VERSION ""

NS_ :

BS_:

BU_: Airbag Allrad EPS Teves_MK60_ESP LWS LWR Teves_MK70_MABS Waehlhebel EPB TRW_ESP ACC_Radar AFS Magne_Ride RKA_Plus Selespeed Waehlhebel_Sele PDC_PLA Lenkhilfe_APA VAQ Daempfer Hybrid_BMS Hybrid_PWR Hybrid_DQ200 EKlimakomp SWA HCA ACC_Lidar Lenkhilfe_ZF_3G FLA AG6 DQ Hybrid_MSG Diesel Otto Gateway_PQ35_A Gateway_PQ46_A Vector_XXX Fzg_CAN

BO_ 1104 mGetriebe_8: 8 Selespeed
 SG_ GE8_Checksumme : 0|8@1+ (1,0) [0|255] ""  Otto
 SG_ GE8_Hydr_Pumpe : 12|1@1+ (1,0) [0|1] ""  Otto
 SG_ GE8_Motor_aus : 13|1@1+ (1,0) [0|1] ""  Otto
 SG_ GE8_Anfahrfkt : 14|1@1+ (1,0) [0|1] ""  Otto
 SG_ GE8_SollDZ : 16|10@1+ (10,0) [0|10230] "upm"  Otto
 SG_ GE8_VorsteuerMom : 26|10@1+ (1,0) [0|1023] "Nm"  Otto
 SG_ GE8_KuppMom : 36|10@1+ (1,0) [0|1023] "Nm"  Otto
 SG_ GE8_Zaehler : 8|4@1+ (1,0) [0|15] ""  Otto
 SG_ GE8_res_15 : 15|1@1+ (1,0) [0|1] "" Vector__XXX
 SG_ GE8_res_46 : 46|1@1+ (1,0) [0|1] "" Vector__XXX
 SG_ GE8_res_47 : 47|1@1+ (1,0) [0|1] "" Vector__XXX
 SG_ GE8_res_48 : 48|1@1+ (1,0) [0|1] "" Vector__XXX
 SG_ GE8_res_49 : 49|1@1+ (1,0) [0|1] "" Vector__XXX
 SG_ GE8_res_50 : 50|1@1+ (1,0) [0|1] "" Vector__XXX
 SG_ GE8_res_52 : 52|1@1+ (1,0) [0|1] "" Vector__XXX
 SG_ GE8_res_53 : 53|1@1+ (1,0) [0|1] "" Vector__XXX
 SG_ GE8_res_54 : 54|1@1+ (1,0) [0|1] "" Vector__XXX
 SG_ GE8_res_55 : 55|1@1+ (1,0) [0|1] "" Vector__XXX
 SG_ GE8_res_56 : 56|1@1+ (1,0) [0|1] "" Vector__XXX
 SG_ GE8_res_57 : 57|1@1+ (1,0) [0|1] "" Vector__XXX
 SG_ GE8_res_51 : 51|1@1+ (1,0) [0|1] "" Vector__XXX
 SG_ GE8_res_58 : 58|1@1+ (1,0) [0|1] "" Vector__XXX
 SG_ GE8_res_59 : 59|1@1+ (1,0) [0|1] "" Vector__XXX
 SG_ GE8_res_60 : 60|1@1+ (1,0) [0|1] "" Vector__XXX
 SG_ GE8_res_61 : 61|1@1+ (1,0) [0|1] "" Vector__XXX
 SG_ GE8_res_63 : 63|1@1+ (1,0) [0|1] "" Vector__XXX
 SG_ GE8_res_62 : 62|1@1+ (1,0) [0|1] "" Vector__XXX

BO_ 1102 mWaehlhebel_2: 5 Waehlhebel_Sele
 SG_ WH2_Fehler0 : 24|1@1+ (1,0) [0|1] ""  Selespeed
 SG_ WH2_Testergebnis : 32|8@1+ (1,0) [0|255] ""  Selespeed
 SG_ WH2_Zaehler : 8|4@1+ (1,0) [0|15] ""  Selespeed
 SG_ WH2_Init : 12|1@1+ (1,0) [0|1] ""  Selespeed
 SG_ WH2_Checksumme : 0|8@1+ (1,0) [0|255] ""  Selespeed
 SG_ WH2_Winter : 15|1@1+ (1,0) [0|1] ""  Selespeed
 SG_ WH2_Sport : 14|1@1+ (1,0) [0|1] ""  Selespeed
 SG_ WH2_Reserve1 : 19|4@1+ (1,0) [0|15] ""  Selespeed
 SG_ WH2_Test_Flag : 13|1@1+ (1,0) [0|1] ""  Selespeed
 SG_ WH2_Position : 16|3@1+ (1,0) [0|7] ""  Selespeed
 SG_ WH2_Ruhestromfehler : 23|1@1+ (1,0) [0|1] ""  Selespeed
 SG_ WH2_Fehler2 : 26|1@1+ (1,0) [0|1] ""  Selespeed
 SG_ WH2_Fehler1 : 25|1@1+ (1,0) [0|1] ""  Selespeed
 SG_ WH2_Fehler4 : 28|1@1+ (1,0) [0|1] ""  Selespeed
 SG_ WH2_Fehler5 : 29|1@1+ (1,0) [0|1] ""  Selespeed
 SG_ WH2_Fehler3 : 27|1@1+ (1,0) [0|1] ""  Selespeed
 SG_ WH2_Fehler7 : 31|1@1+ (1,0) [0|1] ""  Selespeed
 SG_ WH2_Fehler6 : 30|1@1+ (1,0) [0|1] ""  Selespeed

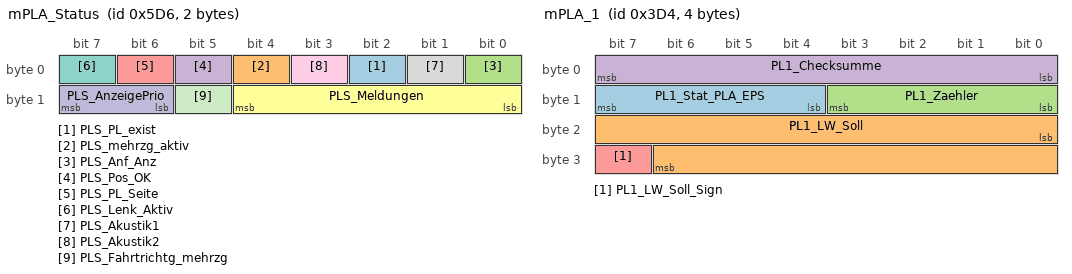
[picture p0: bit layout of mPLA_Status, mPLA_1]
BO_ 1494 mPLA_Status: 2 PDC_PLA
 SG_ PLS_PL_exist : 2|1@1+ (1,0) [0|1] ""  Gateway_PQ46_A,Gateway_PQ35_A
 SG_ PLS_mehrzg_aktiv : 4|1@1+ (1,0) [0|1] ""  Gateway_PQ46_A,Gateway_PQ35_A
 SG_ PLS_Anf_Anz : 0|1@1+ (1,0) [0|1] ""  Gateway_PQ46_A,Gateway_PQ35_A
 SG_ PLS_Pos_OK : 5|1@1+ (1,0) [0|1] ""  Gateway_PQ46_A,Gateway_PQ35_A
 SG_ PLS_PL_Seite : 6|1@1+ (1,0) [0|1] ""  Gateway_PQ46_A,Gateway_PQ35_A
 SG_ PLS_Meldungen : 8|5@1+ (1,0) [0|31] ""  Gateway_PQ46_A,Gateway_PQ35_A
 SG_ PLS_Lenk_Aktiv : 7|1@1+ (1,0) [0|1] ""  Gateway_PQ46_A,Gateway_PQ35_A
 SG_ PLS_Akustik1 : 1|1@1+ (1,0) [0|1] ""  Gateway_PQ46_A,Gateway_PQ35_A
 SG_ PLS_Akustik2 : 3|1@1+ (1,0) [0|1] ""  Gateway_PQ46_A,Gateway_PQ35_A
 SG_ PLS_AnzeigePrio : 14|2@1+ (1,0) [0|3] ""  Gateway_PQ46_A,Gateway_PQ35_A
 SG_ PLS_Fahrtrichtg_mehrzg : 13|1@1+ (1,0) [0|1] ""  Gateway_PQ46_A,Gateway_PQ35_A

BO_ 980 mPLA_1: 4 PDC_PLA
 SG_ PL1_Stat_PLA_EPS : 12|4@1+ (1,0) [0|15] ""  EPS,Lenkhilfe_APA,Lenkhilfe_ZF_3G
 SG_ PL1_LW_Soll : 16|15@1+ (0.04375,0) [0|1433.55625] "°"  EPS,Lenkhilfe_APA,Lenkhilfe_ZF_3G
 SG_ PL1_Zaehler : 8|4@1+ (1,0) [0|15] ""  EPS,Lenkhilfe_APA,Lenkhilfe_ZF_3G
 SG_ PL1_Checksumme : 0|8@1+ (1,0) [0|255] ""  EPS,Lenkhilfe_APA,Lenkhilfe_ZF_3G
 SG_ PL1_LW_Soll_Sign : 31|1@1+ (1,0) [0|1] ""  EPS,Lenkhilfe_APA,Lenkhilfe_ZF_3G

BO_ 541 mTP_Er_PLA_PDC: 7 PDC_PLA
 SG_ PLA_PDC_TP_Er : 0|56@1+ (1,0) [0|7.2057594038E+016] ""  Gateway_PQ46_A,Gateway_PQ35_A

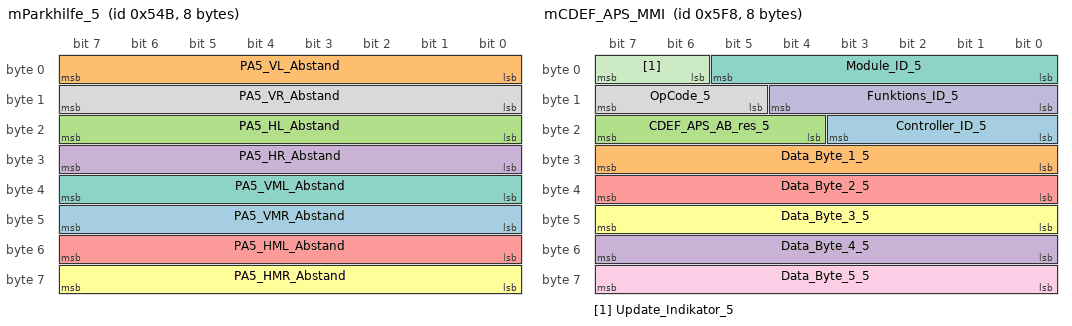
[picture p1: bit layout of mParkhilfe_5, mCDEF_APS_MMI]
BO_ 1355 mParkhilfe_5: 8 PDC_PLA
 SG_ PA5_VMR_Abstand : 40|8@1+ (1,0) [0|254] "cm"  Gateway_PQ46_A,Gateway_PQ35_A
 SG_ PA5_VL_Abstand : 0|8@1+ (1,0) [0|254] "cm"  Gateway_PQ46_A,Gateway_PQ35_A
 SG_ PA5_HL_Abstand : 16|8@1+ (1,0) [0|254] "cm"  Gateway_PQ46_A,Gateway_PQ35_A
 SG_ PA5_HR_Abstand : 24|8@1+ (1,0) [0|254] "cm"  Gateway_PQ46_A,Gateway_PQ35_A
 SG_ PA5_HML_Abstand : 48|8@1+ (1,0) [0|254] "cm"  Gateway_PQ46_A,Gateway_PQ35_A
 SG_ PA5_HMR_Abstand : 56|8@1+ (1,0) [0|254] "cm"  Gateway_PQ46_A,Gateway_PQ35_A
 SG_ PA5_VML_Abstand : 32|8@1+ (1,0) [0|254] "cm"  Gateway_PQ46_A,Gateway_PQ35_A
 SG_ PA5_VR_Abstand : 8|8@1+ (1,0) [0|254] "cm"  Gateway_PQ46_A,Gateway_PQ35_A

BO_ 1175 Parkhilfe_01: 8 PDC_PLA
 SG_ PH_Opt_Anzeige_V_ein : 16|1@1+ (1,0) [0|1] ""  Gateway_PQ46_A,Gateway_PQ35_A
 SG_ PH_Opt_Anzeige_H_ein : 17|1@1+ (1,0) [0|1] ""  Gateway_PQ46_A,Gateway_PQ35_A
 SG_ PH_Opt_Anz_V_Hindernis : 18|1@1+ (1,0) [0|1] ""  Gateway_PQ46_A,Gateway_PQ35_A
 SG_ PH_Abschaltursache : 13|3@1+ (1,0) [0|7] ""  Gateway_PQ46_A,Gateway_PQ35_A
 SG_ PH_Opt_Anz_H_Hindernis : 19|1@1+ (1,0) [0|1] ""  Gateway_PQ46_A,Gateway_PQ35_A
 SG_ PH_Tongeber_V_aktiv : 20|1@1+ (1,0) [0|1] ""  Gateway_PQ46_A,Gateway_PQ35_A
 SG_ PH_Tongeber_mute : 22|1@1+ (1,0) [0|1] ""  Gateway_PQ46_A,Gateway_PQ35_A
 SG_ PH_Frequenz_hinten : 32|4@1+ (1,0) [0|15] ""  Gateway_PQ46_A,Gateway_PQ35_A
 SG_ PH_Lautstaerke_hinten : 36|4@1+ (1,0) [0|15] ""  Gateway_PQ46_A,Gateway_PQ35_A
 SG_ PH_Tongeber_H_aktiv : 21|1@1+ (1,0) [0|1] ""  Gateway_PQ46_A,Gateway_PQ35_A
 SG_ PH_Frequenz_vorn : 40|4@1+ (1,0) [0|15] ""  Gateway_PQ46_A,Gateway_PQ35_A
 SG_ PH_Lautstaerke_vorn : 44|4@1+ (1,0) [0|15] ""  Gateway_PQ46_A,Gateway_PQ35_A
 SG_ PH_defekt : 56|1@1+ (1,0) [0|1] ""  Gateway_PQ46_A,Gateway_PQ35_A
 SG_ PH_Anf_Audioabsenkung : 23|1@1+ (1,0) [0|1] ""  Gateway_PQ46_A,Gateway_PQ35_A
 SG_ PH_Systemzustand : 58|3@1+ (1,0) [0|7] ""  Gateway_PQ46_A,Gateway_PQ35_A
 SG_ PH_Display_Kundenwunsch : 61|2@1+ (1,0) [0|3] ""  Gateway_PQ46_A,Gateway_PQ35_A
 SG_ PH_KD_Fehler : 63|1@1+ (1,0) [0|1] ""  Gateway_PQ46_A,Gateway_PQ35_A
 SG_ PH_gestoert : 57|1@1+ (1,0) [0|1] ""  Gateway_PQ46_A,Gateway_PQ35_A
 SG_ PH_res_02 : 2|1@1+ (1,0) [0|1] ""  Gateway_PQ46_A,Gateway_PQ35_A
 SG_ PH_res_04 : 4|1@1+ (1,0) [0|1] ""  Gateway_PQ46_A,Gateway_PQ35_A
 SG_ PH_res_01 : 1|1@1+ (1,0) [0|1] ""  Gateway_PQ46_A,Gateway_PQ35_A
 SG_ PH_res_00 : 0|1@1+ (1,0) [0|1] ""  Gateway_PQ46_A,Gateway_PQ35_A
 SG_ PH_res_05 : 5|1@1+ (1,0) [0|1] ""  Gateway_PQ46_A,Gateway_PQ35_A
 SG_ PH_res_03 : 3|1@1+ (1,0) [0|1] ""  Gateway_PQ46_A,Gateway_PQ35_A
 SG_ PH_res_06 : 6|1@1+ (1,0) [0|1] ""  Gateway_PQ46_A,Gateway_PQ35_A
 SG_ PH_res_07 : 7|1@1+ (1,0) [0|1] ""  Gateway_PQ46_A,Gateway_PQ35_A
 SG_ PH_res_08 : 8|1@1+ (1,0) [0|1] ""  Gateway_PQ46_A,Gateway_PQ35_A
 SG_ PH_res_10 : 10|1@1+ (1,0) [0|1] ""  Gateway_PQ46_A,Gateway_PQ35_A
 SG_ PH_res_11 : 11|1@1+ (1,0) [0|1] ""  Gateway_PQ46_A,Gateway_PQ35_A
 SG_ PH_res_12 : 12|1@1+ (1,0) [0|1] ""  Gateway_PQ46_A,Gateway_PQ35_A
 SG_ PH_res_09 : 9|1@1+ (1,0) [0|1] ""  Gateway_PQ46_A,Gateway_PQ35_A
 SG_ PH_res_25 : 25|1@1+ (1,0) [0|1] ""  Gateway_PQ46_A,Gateway_PQ35_A
 SG_ PH_res_26 : 26|1@1+ (1,0) [0|1] ""  Gateway_PQ46_A,Gateway_PQ35_A
 SG_ PH_res_27 : 27|1@1+ (1,0) [0|1] ""  Gateway_PQ46_A,Gateway_PQ35_A
 SG_ PH_res_24 : 24|1@1+ (1,0) [0|1] ""  Gateway_PQ46_A,Gateway_PQ35_A
 SG_ PH_res_28 : 28|1@1+ (1,0) [0|1] ""  Gateway_PQ46_A,Gateway_PQ35_A
 SG_ PH_res_30 : 30|1@1+ (1,0) [0|1] ""  Gateway_PQ46_A,Gateway_PQ35_A
 SG_ PH_Trigger_Bildaufschaltung : 48|1@1+ (1,0) [0|1] ""  Gateway_PQ46_A,Gateway_PQ35_A
 SG_ PH_Aufbauten_erk : 51|1@1+ (1,0) [0|1] ""  Gateway_PQ46_A,Gateway_PQ35_A
 SG_ PH_res_29 : 29|1@1+ (1,0) [0|1] ""  Gateway_PQ46_A,Gateway_PQ35_A
 SG_ PH_BerErk_vorn : 52|2@1+ (1,0) [0|3] ""  Gateway_PQ46_A,Gateway_PQ35_A
 SG_ PH_res_31 : 31|1@1+ (1,0) [0|1] ""  Gateway_PQ46_A,Gateway_PQ35_A
 SG_ PH_StartStopp_Info : 49|2@1+ (1,0) [0|3] ""  Gateway_PQ46_A,Gateway_PQ35_A,Otto,Diesel
 SG_ PH_BerErk_hinten : 54|2@1+ (1,0) [0|3] ""  Gateway_PQ46_A,Gateway_PQ35_A

BO_ 1754 BAP_OPS: 8 PDC_PLA
 SG_ BAP_var_OPS : 16|48@1+ (1,0) [0|2.8147497671E+014] ""  Gateway_PQ46_A,Gateway_PQ35_A
 SG_ BAP_Data_OPS : 0|16@1+ (1,0) [0|65535] ""  Gateway_PQ46_A,Gateway_PQ35_A

BO_ 1528 mCDEF_APS_MMI: 8 PDC_PLA
 SG_ Controller_ID_5 : 16|4@1+ (1,0) [0|15] ""  Gateway_PQ35_A
 SG_ Data_Byte_1_5 : 24|8@1+ (1,0) [0|255] ""  Gateway_PQ35_A
 SG_ CDEF_APS_AB_res_5 : 20|4@1+ (1,0) [0|15] ""  Gateway_PQ35_A
 SG_ Data_Byte_4_5 : 48|8@1+ (1,0) [0|255] ""  Gateway_PQ35_A
 SG_ Data_Byte_2_5 : 32|8@1+ (1,0) [0|255] ""  Gateway_PQ35_A
 SG_ Data_Byte_3_5 : 40|8@1+ (1,0) [0|255] ""  Gateway_PQ35_A
 SG_ Module_ID_5 : 0|6@1+ (1,0) [0|63] ""  Gateway_PQ35_A
 SG_ OpCode_5 : 13|3@1+ (1,0) [0|7] ""  Gateway_PQ35_A
 SG_ Data_Byte_5_5 : 56|8@1+ (1,0) [0|255] ""  Gateway_PQ35_A
 SG_ Funktions_ID_5 : 8|5@1+ (1,0) [0|31] ""  Gateway_PQ35_A
 SG_ Update_Indikator_5 : 6|2@1+ (1,0) [0|3] ""  Gateway_PQ35_A

BO_ 1908 ISO_EPH_Resp: 8 PDC_PLA
 SG_ ISO_EPH_Resp_Data : 0|64@1+ (1,0) [0|1.8446744074E+019] ""  Gateway_PQ46_A,Gateway_PQ35_A

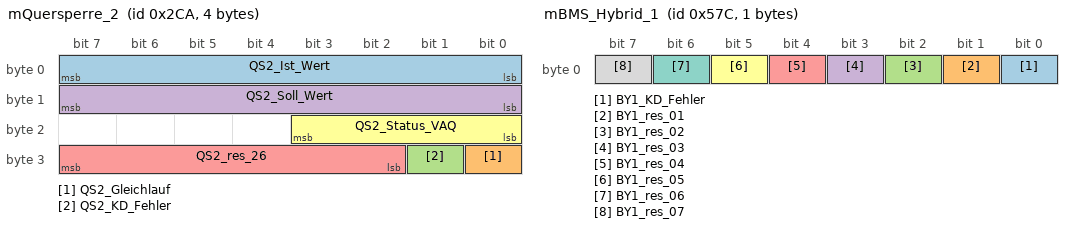
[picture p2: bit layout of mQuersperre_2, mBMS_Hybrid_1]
BO_ 714 mQuersperre_2: 4 VAQ
 SG_ QS2_Ist_Wert : 0|8@1+ (10,0) [0|2540] "Nm"  Teves_MK60_ESP
 SG_ QS2_Gleichlauf : 24|1@1+ (1,0) [0|1] ""  Teves_MK60_ESP
 SG_ QS2_KD_Fehler : 25|1@1+ (1,0) [0|1] ""  Gateway_PQ35_A
 SG_ QS2_Soll_Wert : 8|8@1+ (10,0) [0|2540] "Nm"  Teves_MK60_ESP
 SG_ QS2_res_26 : 26|6@1+ (1,0) [0|63] "" Vector__XXX
 SG_ QS2_Status_VAQ : 16|4@1+ (1,0) [0|15] ""  Teves_MK60_ESP

BO_ 536 mTP_Er_Quersperre: 7 VAQ
 SG_ Quersperre_TP_Er : 0|56@1+ (1,0) [0|7.2057594038E+016] ""  Gateway_PQ35_A

BO_ 1404 mBMS_Hybrid_1: 1 Hybrid_BMS
 SG_ BY1_KD_Fehler : 0|1@1+ (1,0) [0|1] "" Vector__XXX
 SG_ BY1_res_01 : 1|1@1+ (1,0) [0|1] "" Vector__XXX
 SG_ BY1_res_02 : 2|1@1+ (1,0) [0|1] "" Vector__XXX
 SG_ BY1_res_03 : 3|1@1+ (1,0) [0|1] "" Vector__XXX
 SG_ BY1_res_04 : 4|1@1+ (1,0) [0|1] "" Vector__XXX
 SG_ BY1_res_05 : 5|1@1+ (1,0) [0|1] "" Vector__XXX
 SG_ BY1_res_06 : 6|1@1+ (1,0) [0|1] "" Vector__XXX
 SG_ BY1_res_07 : 7|1@1+ (1,0) [0|1] "" Vector__XXX

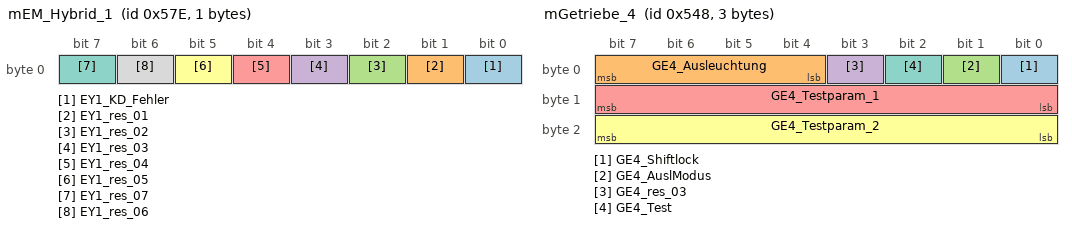
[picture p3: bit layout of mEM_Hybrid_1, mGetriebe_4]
BO_ 1406 mEM_Hybrid_1: 1 Hybrid_PWR
 SG_ EY1_KD_Fehler : 0|1@1+ (1,0) [0|1] "" Vector__XXX
 SG_ EY1_res_01 : 1|1@1+ (1,0) [0|1] "" Vector__XXX
 SG_ EY1_res_02 : 2|1@1+ (1,0) [0|1] "" Vector__XXX
 SG_ EY1_res_03 : 3|1@1+ (1,0) [0|1] "" Vector__XXX
 SG_ EY1_res_04 : 4|1@1+ (1,0) [0|1] "" Vector__XXX
 SG_ EY1_res_05 : 5|1@1+ (1,0) [0|1] "" Vector__XXX
 SG_ EY1_res_07 : 7|1@1+ (1,0) [0|1] "" Vector__XXX
 SG_ EY1_res_06 : 6|1@1+ (1,0) [0|1] "" Vector__XXX

BO_ 1352 mGetriebe_4: 3 Hybrid_DQ200
 SG_ GE4_Shiftlock : 0|1@1+ (1,0) [0|1] ""  Waehlhebel
 SG_ GE4_Ausleuchtung : 4|4@1+ (1,0) [0|15] ""  Waehlhebel
 SG_ GE4_AuslModus : 1|1@1+ (1,0) [0|1] ""  Waehlhebel
 SG_ GE4_res_03 : 3|1@1+ (1,0) [0|1] "" Vector__XXX
 SG_ GE4_Testparam_1 : 8|8@1+ (1,0) [0|255] ""  Waehlhebel
 SG_ GE4_Testparam_2 : 16|8@1+ (1,0) [0|255] ""  Waehlhebel
 SG_ GE4_Test : 2|1@1+ (1,0) [0|1] ""  Waehlhebel

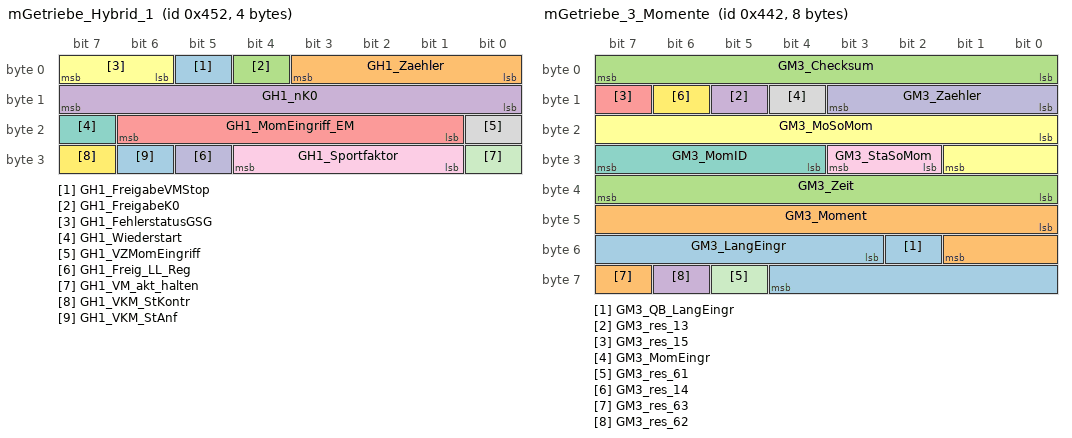
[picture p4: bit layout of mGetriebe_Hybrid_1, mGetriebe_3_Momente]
BO_ 1106 mGetriebe_Hybrid_1: 4 Hybrid_DQ200
 SG_ GH1_FreigabeVMStop : 5|1@1+ (1,0) [0|1] ""  Hybrid_MSG
 SG_ GH1_Zaehler : 0|4@1+ (1,0) [0|15] ""  Hybrid_MSG
 SG_ GH1_FreigabeK0 : 4|1@1+ (1,0) [0|1] ""  Hybrid_MSG
 SG_ GH1_nK0 : 8|8@1+ (25,0) [0|6350] "1/min"  Hybrid_MSG
 SG_ GH1_MomEingriff_EM : 17|6@1+ (0.5,0) [0|31.5] "Nm"  Hybrid_PWR
 SG_ GH1_FehlerstatusGSG : 6|2@1+ (1,0) [0|3] ""  Hybrid_MSG
 SG_ GH1_Wiederstart : 23|1@1+ (1,0) [0|1] ""  Hybrid_MSG
 SG_ GH1_VZMomEingriff : 16|1@1+ (1,0) [0|1] ""  Hybrid_PWR
 SG_ GH1_Sportfaktor : 25|4@1+ (1,0) [0|15] ""  Hybrid_MSG
 SG_ GH1_Freig_LL_Reg : 29|1@1+ (1,0) [0|1] ""  Hybrid_MSG
 SG_ GH1_VM_akt_halten : 24|1@1+ (1,0) [0|1] ""  Hybrid_MSG
 SG_ GH1_VKM_StKontr : 31|1@1+ (1,0) [0|1] ""  Hybrid_MSG
 SG_ GH1_VKM_StAnf : 30|1@1+ (1,0) [0|1] ""  Hybrid_MSG

BO_ 2025 ISO_Getriebe_01_Resp: 8 Hybrid_DQ200
 SG_ ISO_Getriebe_01_Resp_Data : 0|64@1+ (1,0) [0|1.8446744074E+019] ""  Gateway_PQ35_A,Gateway_PQ46_A

BO_ 1090 mGetriebe_3_Momente: 8 Hybrid_DQ200
 SG_ GM3_QB_LangEingr : 50|1@1+ (1,0) [0|1] "" Vector__XXX
 SG_ GM3_Moment : 40|10@1+ (1,0) [0|1022] "Nm" Vector__XXX
 SG_ GM3_Checksum : 0|8@1+ (1,0) [0|255] "" Vector__XXX
 SG_ GM3_res_13 : 13|1@1+ (1,0) [0|1] "" Vector__XXX
 SG_ GM3_res_15 : 15|1@1+ (1,0) [0|1] "" Vector__XXX
 SG_ GM3_MoSoMom : 16|10@1+ (1,0) [0|1021] "Nm"  Hybrid_MSG
 SG_ GM3_MomID : 28|4@1+ (1,0) [0|15] "" Vector__XXX
 SG_ GM3_MomEingr : 12|1@1+ (1,0) [0|1] ""  Hybrid_MSG
 SG_ GM3_StaSoMom : 26|2@1+ (1,0) [0|3] "" Vector__XXX
 SG_ GM3_Zaehler : 8|4@1+ (1,0) [0|15] "" Vector__XXX
 SG_ GM3_res_61 : 61|1@1+ (1,0) [0|1] "" Vector__XXX
 SG_ GM3_res_14 : 14|1@1+ (1,0) [0|1] "" Vector__XXX
 SG_ GM3_LangEingr : 51|10@1+ (1,0) [0|1021] "Nm" Vector__XXX
 SG_ GM3_res_63 : 63|1@1+ (1,0) [0|1] "" Vector__XXX
 SG_ GM3_Zeit : 32|8@1+ (10,0) [0|2550] "ms" Vector__XXX
 SG_ GM3_res_62 : 62|1@1+ (1,0) [0|1] "" Vector__XXX

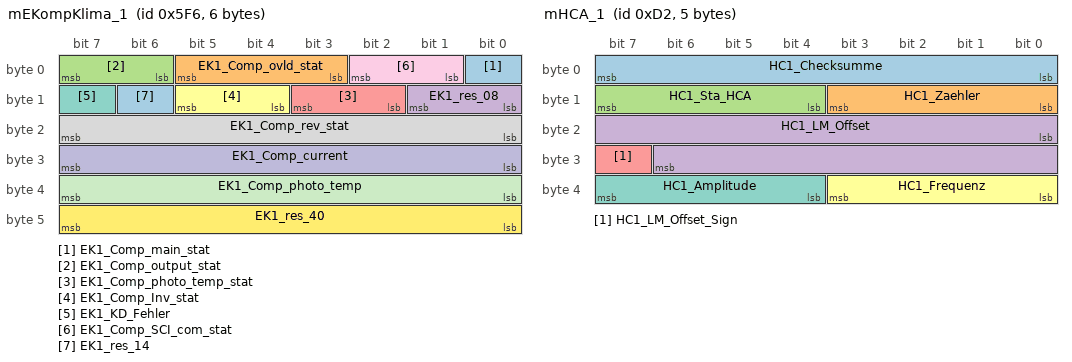
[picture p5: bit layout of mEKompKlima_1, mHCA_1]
BO_ 1526 mEKompKlima_1: 6 EKlimakomp
 SG_ EK1_Comp_main_stat : 0|1@1+ (1,0) [0|1] ""  Gateway_PQ35_A,Gateway_PQ46_A
 SG_ EK1_Comp_ovld_stat : 3|3@1+ (1,0) [0|7] ""  Gateway_PQ46_A,Gateway_PQ35_A
 SG_ EK1_Comp_output_stat : 6|2@1+ (1,0) [0|3] ""  Gateway_PQ46_A,Gateway_PQ35_A
 SG_ EK1_res_08 : 8|2@1+ (1,0) [0|3] ""  Gateway_PQ46_A,Gateway_PQ35_A
 SG_ EK1_Comp_photo_temp_stat : 10|2@1+ (1,0) [0|3] ""  Gateway_PQ46_A,Gateway_PQ35_A
 SG_ EK1_Comp_Inv_stat : 12|2@1+ (1,0) [0|3] ""  Gateway_PQ46_A,Gateway_PQ35_A
 SG_ EK1_KD_Fehler : 15|1@1+ (1,0) [0|1] ""  Gateway_PQ46_A,Gateway_PQ35_A
 SG_ EK1_Comp_rev_stat : 16|8@1+ (50,0) [0|8600] "rpm"  Gateway_PQ46_A,Gateway_PQ35_A
 SG_ EK1_Comp_SCI_com_stat : 1|2@1+ (1,0) [0|3] ""  Gateway_PQ46_A,Gateway_PQ35_A
 SG_ EK1_Comp_current : 24|8@1+ (0.1,0) [0|25.4] "A"  Hybrid_MSG,Gateway_PQ46_A,Gateway_PQ35_A
 SG_ EK1_Comp_photo_temp : 32|8@1+ (1,0) [0|254] "°C"  Gateway_PQ46_A,Gateway_PQ35_A
 SG_ EK1_res_40 : 40|8@1+ (1,0) [0|255] ""  Gateway_PQ46_A,Gateway_PQ35_A
 SG_ EK1_res_14 : 14|1@1+ (1,0) [0|1] ""  Gateway_PQ46_A,Gateway_PQ35_A

BO_ 1923 ISO_EKomp_Resp: 8 EKlimakomp
 SG_ ISO_EKomp_Resp_Data : 0|64@1+ (1,0) [0|1.8446744074E+019] "" Vector__XXX

BO_ 1650 BAP_SWA: 8 SWA
 SG_ BAP_var_SWA : 16|48@1+ (1,0) [0|2.8147497671E+014] ""  Gateway_PQ46_A,Gateway_PQ35_A
 SG_ BAP_Data_SWA : 0|16@1+ (1,0) [0|65535] ""  Gateway_PQ35_A,Gateway_PQ46_A

BO_ 954 mSWA_1: 8 SWA
 SG_ SWA_Gong : 16|2@1+ (1,0) [0|3] ""  Gateway_PQ35_A,Gateway_PQ46_A
 SG_ SWA_Textbits : 12|4@1+ (1,0) [0|15] ""  Gateway_PQ35_A,Gateway_PQ46_A
 SG_ SWA_Sta_passiv : 19|1@1+ (1,0) [0|1] ""  Gateway_PQ35_A,Gateway_PQ46_A
 SG_ SWA_KD_Fehler : 59|1@1+ (1,0) [0|1] ""  Gateway_PQ35_A,Gateway_PQ46_A
 SG_ SWA_res_00 : 0|1@1+ (1,0) [0|1] ""  Gateway_PQ46_A,Gateway_PQ35_A
 SG_ SWA_res_01 : 1|1@1+ (1,0) [0|1] ""  Gateway_PQ46_A,Gateway_PQ35_A
 SG_ SWA_res_02 : 2|1@1+ (1,0) [0|1] ""  Gateway_PQ46_A,Gateway_PQ35_A
 SG_ SWA_res_03 : 3|1@1+ (1,0) [0|1] ""  Gateway_PQ46_A,Gateway_PQ35_A
 SG_ SWA_res_06 : 6|1@1+ (1,0) [0|1] ""  Gateway_PQ46_A,Gateway_PQ35_A
 SG_ SWA_res_07 : 7|1@1+ (1,0) [0|1] ""  Gateway_PQ46_A,Gateway_PQ35_A
 SG_ SWA_Sta_aktiv : 20|1@1+ (1,0) [0|1] ""  Gateway_PQ35_A,Gateway_PQ46_A
 SG_ SWA_res_04 : 4|1@1+ (1,0) [0|1] ""  Gateway_PQ46_A,Gateway_PQ35_A
 SG_ SWA_res_05 : 5|1@1+ (1,0) [0|1] ""  Gateway_PQ46_A,Gateway_PQ35_A
 SG_ SWA_res_08 : 8|1@1+ (1,0) [0|1] ""  Gateway_PQ46_A,Gateway_PQ35_A
 SG_ SWA_res_09 : 9|1@1+ (1,0) [0|1] ""  Gateway_PQ46_A,Gateway_PQ35_A
 SG_ SWA_res_10 : 10|1@1+ (1,0) [0|1] ""  Gateway_PQ46_A,Gateway_PQ35_A
 SG_ SWA_res_11 : 11|1@1+ (1,0) [0|1] ""  Gateway_PQ46_A,Gateway_PQ35_A
 SG_ SWA_res_21 : 21|1@1+ (1,0) [0|1] ""  Gateway_PQ46_A,Gateway_PQ35_A
 SG_ SWA_res_22 : 22|1@1+ (1,0) [0|1] ""  Gateway_PQ46_A,Gateway_PQ35_A
 SG_ SWA_res_23 : 23|1@1+ (1,0) [0|1] ""  Gateway_PQ46_A,Gateway_PQ35_A
 SG_ SWA_res_18 : 18|1@1+ (1,0) [0|1] ""  Gateway_PQ46_A,Gateway_PQ35_A
 SG_ SWA_res_24 : 24|1@1+ (1,0) [0|1] ""  Gateway_PQ46_A,Gateway_PQ35_A
 SG_ SWA_res_25 : 25|1@1+ (1,0) [0|1] ""  Gateway_PQ46_A,Gateway_PQ35_A
 SG_ SWA_res_26 : 26|1@1+ (1,0) [0|1] ""  Gateway_PQ46_A,Gateway_PQ35_A
 SG_ SWA_res_27 : 27|1@1+ (1,0) [0|1] ""  Gateway_PQ46_A,Gateway_PQ35_A
 SG_ SWA_res_28 : 28|1@1+ (1,0) [0|1] ""  Gateway_PQ46_A,Gateway_PQ35_A
 SG_ SWA_res_30 : 30|1@1+ (1,0) [0|1] ""  Gateway_PQ46_A,Gateway_PQ35_A
 SG_ SWA_res_31 : 31|1@1+ (1,0) [0|1] ""  Gateway_PQ46_A,Gateway_PQ35_A
 SG_ SWA_res_32 : 32|1@1+ (1,0) [0|1] ""  Gateway_PQ46_A,Gateway_PQ35_A
 SG_ SWA_res_29 : 29|1@1+ (1,0) [0|1] ""  Gateway_PQ46_A,Gateway_PQ35_A
 SG_ SWA_res_33 : 33|1@1+ (1,0) [0|1] ""  Gateway_PQ46_A,Gateway_PQ35_A
 SG_ SWA_res_34 : 34|1@1+ (1,0) [0|1] ""  Gateway_PQ46_A,Gateway_PQ35_A
 SG_ SWA_res_35 : 35|1@1+ (1,0) [0|1] ""  Gateway_PQ46_A,Gateway_PQ35_A
 SG_ SWA_res_38 : 38|1@1+ (1,0) [0|1] ""  Gateway_PQ46_A,Gateway_PQ35_A
 SG_ SWA_res_39 : 39|1@1+ (1,0) [0|1] ""  Gateway_PQ46_A,Gateway_PQ35_A
 SG_ SWA_res_40 : 40|1@1+ (1,0) [0|1] ""  Gateway_PQ46_A,Gateway_PQ35_A
 SG_ SWA_res_37 : 37|1@1+ (1,0) [0|1] ""  Gateway_PQ46_A,Gateway_PQ35_A
 SG_ SWA_res_41 : 41|1@1+ (1,0) [0|1] ""  Gateway_PQ46_A,Gateway_PQ35_A
 SG_ SWA_res_36 : 36|1@1+ (1,0) [0|1] ""  Gateway_PQ46_A,Gateway_PQ35_A
 SG_ SWA_res_42 : 42|1@1+ (1,0) [0|1] ""  Gateway_PQ46_A,Gateway_PQ35_A
 SG_ SWA_res_43 : 43|1@1+ (1,0) [0|1] ""  Gateway_PQ46_A,Gateway_PQ35_A
 SG_ SWA_res_44 : 44|1@1+ (1,0) [0|1] ""  Gateway_PQ46_A,Gateway_PQ35_A
 SG_ SWA_res_45 : 45|1@1+ (1,0) [0|1] ""  Gateway_PQ46_A,Gateway_PQ35_A
 SG_ SWA_res_47 : 47|1@1+ (1,0) [0|1] ""  Gateway_PQ46_A,Gateway_PQ35_A
 SG_ SWA_res_48 : 48|1@1+ (1,0) [0|1] ""  Gateway_PQ46_A,Gateway_PQ35_A
 SG_ SWA_res_46 : 46|1@1+ (1,0) [0|1] ""  Gateway_PQ46_A,Gateway_PQ35_A
 SG_ SWA_res_50 : 50|1@1+ (1,0) [0|1] ""  Gateway_PQ46_A,Gateway_PQ35_A
 SG_ SWA_res_49 : 49|1@1+ (1,0) [0|1] ""  Gateway_PQ46_A,Gateway_PQ35_A
 SG_ SWA_res_51 : 51|1@1+ (1,0) [0|1] ""  Gateway_PQ46_A,Gateway_PQ35_A
 SG_ SWA_res_52 : 52|1@1+ (1,0) [0|1] ""  Gateway_PQ46_A,Gateway_PQ35_A
 SG_ SWA_res_53 : 53|1@1+ (1,0) [0|1] ""  Gateway_PQ46_A,Gateway_PQ35_A
 SG_ SWA_res_55 : 55|1@1+ (1,0) [0|1] ""  Gateway_PQ46_A,Gateway_PQ35_A
 SG_ SWA_res_57 : 57|1@1+ (1,0) [0|1] ""  Gateway_PQ46_A,Gateway_PQ35_A
 SG_ SWA_res_54 : 54|1@1+ (1,0) [0|1] ""  Gateway_PQ46_A,Gateway_PQ35_A
 SG_ SWA_res_60 : 60|1@1+ (1,0) [0|1] ""  Gateway_PQ46_A,Gateway_PQ35_A
 SG_ SWA_res_61 : 61|1@1+ (1,0) [0|1] ""  Gateway_PQ46_A,Gateway_PQ35_A
 SG_ SWA_res_56 : 56|1@1+ (1,0) [0|1] ""  Gateway_PQ46_A,Gateway_PQ35_A
 SG_ SWA_res_63 : 63|1@1+ (1,0) [0|1] ""  Gateway_PQ46_A,Gateway_PQ35_A
 SG_ SWA_res_58 : 58|1@1+ (1,0) [0|1] ""  Gateway_PQ46_A,Gateway_PQ35_A
 SG_ SWA_res_62 : 62|1@1+ (1,0) [0|1] ""  Gateway_PQ46_A,Gateway_PQ35_A

BO_ 540 mTP_Er_SWA: 7 SWA
 SG_ SWA_TP_Er : 0|56@1+ (1,0) [0|7.2057594038E+016] ""  Gateway_PQ35_A,Gateway_PQ46_A

BO_ 1651 BAP_LDW: 8 HCA
 SG_ BAP_Data_LDW : 0|16@1+ (1,0) [0|65535] ""  Gateway_PQ46_A,Gateway_PQ35_A
 SG_ BAP_var_LDW : 16|48@1+ (1,0) [0|2.8147497671E+014] ""  Gateway_PQ46_A,Gateway_PQ35_A

BO_ 1470 mLDW_Status: 3 HCA
 SG_ LDW_Lampe_gelb : 19|1@1+ (1,0) [0|1] ""  Gateway_PQ46_A,Gateway_PQ35_A
 SG_ LDW_Gong : 16|2@1+ (1,0) [0|3] ""  Gateway_PQ46_A,Gateway_PQ35_A
 SG_ LDW_Lampe_gruen : 20|1@1+ (1,0) [0|1] ""  Gateway_PQ46_A,Gateway_PQ35_A
 SG_ LDW_KD_Fehler : 23|1@1+ (1,0) [0|1] ""  Gateway_PQ46_A,Gateway_PQ35_A
 SG_ LDW_res_00 : 0|1@1+ (1,0) [0|1] ""  Gateway_PQ46_A,Gateway_PQ35_A
 SG_ LDW_Textbits : 12|4@1+ (1,0) [0|15] ""  Gateway_PQ46_A,Gateway_PQ35_A
 SG_ LDW_res_01 : 1|1@1+ (1,0) [0|1] ""  Gateway_PQ46_A,Gateway_PQ35_A
 SG_ LDW_res_02 : 2|1@1+ (1,0) [0|1] ""  Gateway_PQ46_A,Gateway_PQ35_A
 SG_ LDW_res_03 : 3|1@1+ (1,0) [0|1] ""  Gateway_PQ46_A,Gateway_PQ35_A
 SG_ LDW_res_05 : 5|1@1+ (1,0) [0|1] ""  Gateway_PQ46_A,Gateway_PQ35_A
 SG_ LDW_res_06 : 6|1@1+ (1,0) [0|1] ""  Gateway_PQ46_A,Gateway_PQ35_A
 SG_ LDW_res_07 : 7|1@1+ (1,0) [0|1] ""  Gateway_PQ46_A,Gateway_PQ35_A
 SG_ LDW_res_08 : 8|1@1+ (1,0) [0|1] ""  Gateway_PQ46_A,Gateway_PQ35_A
 SG_ LDW_Lernmodus : 9|3@1+ (1,0) [0|7] ""  Gateway_PQ46_A,Gateway_PQ35_A
 SG_ LDW_res_04 : 4|1@1+ (1,0) [0|1] ""  Gateway_PQ46_A,Gateway_PQ35_A
 SG_ LDW_res_18 : 18|1@1+ (1,0) [0|1] ""  Gateway_PQ46_A,Gateway_PQ35_A
 SG_ LDW_res_21 : 21|1@1+ (1,0) [0|1] ""  Gateway_PQ46_A,Gateway_PQ35_A
 SG_ LDW_res_22 : 22|1@1+ (1,0) [0|1] ""  Gateway_PQ46_A,Gateway_PQ35_A

BO_ 538 mTP_Er_LDW: 7 HCA
 SG_ LDW_TP_Er : 0|56@1+ (1,0) [0|7.2057594038E+016] ""  Gateway_PQ46_A,Gateway_PQ35_A

BO_ 210 mHCA_1: 5 HCA
 SG_ HC1_Checksumme : 0|8@1+ (1,0) [0|255] ""  EPS,Lenkhilfe_APA,Lenkhilfe_ZF_3G
 SG_ HC1_Zaehler : 8|4@1+ (1,0) [0|15] ""  Lenkhilfe_APA,EPS,Lenkhilfe_ZF_3G
 SG_ HC1_Sta_HCA : 12|4@1+ (1,0) [0|15] ""  Lenkhilfe_APA,EPS,Lenkhilfe_ZF_3G
 SG_ HC1_LM_Offset : 16|15@1+ (0.0003052,0) [0|10.0004884] "Nm"  Lenkhilfe_APA,EPS,Lenkhilfe_ZF_3G
 SG_ HC1_LM_Offset_Sign : 31|1@1+ (1,0) [0|1] ""  Lenkhilfe_APA,EPS,Lenkhilfe_ZF_3G
 SG_ HC1_Frequenz : 32|4@1+ (4,0) [0|60] "Hz"  Lenkhilfe_APA,EPS,Lenkhilfe_ZF_3G
 SG_ HC1_Amplitude : 36|4@1+ (0.5,0) [0|7.5] "Nm"  Lenkhilfe_APA,EPS,Lenkhilfe_ZF_3G

BO_ 1985 ISO_ACC_Resp: 8 ACC_Lidar
 SG_ ISO_ACC_Resp_Data : 0|64@1+ (1,0) [0|1.8446744074E+019] ""  Gateway_PQ35_A,Gateway_PQ46_A

BO_ 1916 ISO_Lenkhilfe_Resp: 8 Lenkhilfe_ZF_3G
 SG_ ISO_Lenkhilfe_Resp_Data : 0|64@1+ (1,0) [0|1.8446744074E+019] ""  Gateway_PQ46_A,Gateway_PQ35_A

BO_ 534 mTP_Er_FLA: 7 FLA
 SG_ FLA_TP_Er : 0|56@1+ (1,0) [0|7.2057594038E+016] ""  Gateway_PQ35_A,Gateway_PQ46_A

BO_ 1626 mFLA_1: 8 FLA
 SG_ FL1_Reserve01 : 0|8@1+ (1,0) [0|255] "" Vector__XXX
 SG_ FL1_Reserve02 : 8|4@1+ (1,0) [0|15] "" Vector__XXX
 SG_ FL1_KD_Fehler : 12|1@1+ (1,0) [0|1] ""  Gateway_PQ46_A,Gateway_PQ35_A
 SG_ FL1_FLA_aktiv : 13|1@1+ (1,0) [0|1] ""  Gateway_PQ46_A,Gateway_PQ35_A
 SG_ FL1_ISP_defekt : 14|1@1+ (1,0) [0|1] "" Vector__XXX
 SG_ FL1_Sensor_blockiert : 15|1@1+ (1,0) [0|1] "" Vector__XXX
 SG_ FL1_Abblendursache : 16|8@1+ (1,0) [0|255] "" Vector__XXX
 SG_ FL1_Fernlicht_PWM : 24|7@1+ (1,0) [0|100] "%" Vector__XXX
 SG_ FL1_ISP_Lichtwert_vo : 32|6@1+ (1,0) [0|61] "" Vector__XXX
 SG_ FL1_ISP_Lichtwert_hi : 40|6@1+ (1,0) [0|61] "" Vector__XXX
 SG_ FL1_ISP_Taste : 53|1@1+ (1,0) [0|1] "" Vector__XXX
 SG_ FL1_ISP_EC_aktiv : 54|1@1+ (1,0) [0|1] "" Vector__XXX
 SG_ FL1_ISP_Kompass_aktiv : 55|1@1+ (1,0) [0|1] "" Vector__XXX
 SG_ FL1_Dimmwert_ASP : 56|6@1+ (1.613,0) [0|100.006] "%" Vector__XXX
 SG_ FL1_FLA_Aufblenden : 62|1@1+ (1,0) [0|1] ""  Gateway_PQ46_A,Gateway_PQ35_A
 SG_ FL1_ISP_Himmelsrichtung : 48|5@1+ (12,0) [0|348] "Grad" Vector__XXX
 SG_ FL1_res_31 : 31|1@1+ (1,0) [0|1] "" Vector__XXX
 SG_ FL1_res_38 : 38|1@1+ (1,0) [0|1] "" Vector__XXX
 SG_ FL1_res_39 : 39|1@1+ (1,0) [0|1] "" Vector__XXX
 SG_ FL1_res_46 : 46|1@1+ (1,0) [0|1] "" Vector__XXX
 SG_ FL1_res_63 : 63|1@1+ (1,0) [0|1] "" Vector__XXX
 SG_ FL1_res_47 : 47|1@1+ (1,0) [0|1] "" Vector__XXX

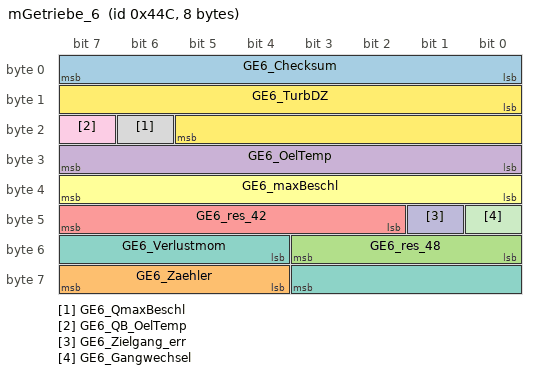
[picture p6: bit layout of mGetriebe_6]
BO_ 1100 mGetriebe_6: 8 AG6
 SG_ GE6_Checksum : 0|8@1+ (1,0) [0|255] ""  Diesel,Otto
 SG_ GE6_Zaehler : 60|4@1+ (1,0) [0|15] ""  Diesel,Otto
 SG_ GE6_res_48 : 48|4@1+ (1,0) [0|15] ""  Otto,Diesel
 SG_ GE6_OelTemp : 24|8@1+ (1,-55) [-55|199] "°C"  Diesel,Otto
 SG_ GE6_res_42 : 42|6@1+ (1,0) [0|63] ""  Otto,Diesel
 SG_ GE6_maxBeschl : 32|8@1+ (0.024,-2.112) [-2.112|3.984] "m/s²"  Otto,Diesel
 SG_ GE6_Verlustmom : 52|8@1+ (0.39,0) [0|99.45] "%"  Otto,Diesel
 SG_ GE6_QmaxBeschl : 22|1@1+ (1,0) [0|1] ""  Otto,Diesel
 SG_ GE6_QB_OelTemp : 23|1@1+ (1,0) [0|1] ""  Diesel,Otto
 SG_ GE6_Zielgang_err : 41|1@1+ (1,0) [0|1] ""  Otto,Diesel
 SG_ GE6_Gangwechsel : 40|1@1+ (1,0) [0|1] ""  Otto,Diesel
 SG_ GE6_TurbDZ : 8|14@1+ (1,0) [0|16381] "1/min"  Diesel,Otto

BO_ 896 mMotor_3: 8 Hybrid_MSG
 SG_ MO3_Prio_Dz : 1|1@1+ (1,0) [0|1] ""  TRW_ESP
 SG_ MO3_Sta_Pedal : 4|1@1+ (1,0) [0|1] ""  EPB,TRW_ESP
 SG_ MO3_res_02 : 2|1@1+ (1,0) [0|1] ""  TRW_ESP
 SG_ MO3_Winterprg : 3|1@1+ (1,0) [0|1] ""  AG6,DQ,TRW_ESP,Hybrid_DQ200
 SG_ MO3_Sign_FPG m1 : 6|1@1+ (1,0) [0|1] ""  TRW_ESP,Teves_MK60_ESP
 SG_ MO3_Aussentemp : 8|8@1+ (0.75,-48) [-48|142.5] "°C"  TRW_ESP,Magne_Ride
 SG_ MO3_Sta_FPG M : 5|1@1+ (1,0) [0|1] ""  TRW_ESP,Teves_MK60_ESP
 SG_ MO3_Vorgluehen : 0|1@1+ (1,0) [0|1] ""  TRW_ESP
 SG_ MO3_Sta_Temp : 7|1@1+ (1,0) [0|1] ""  TRW_ESP
 SG_ MO3_Pedalwert : 16|8@1+ (0.4,0) [0|101.6] "%"  AG6,EPB,TRW_ESP,Magne_Ride,HCA,Teves_MK60_ESP
 SG_ MO3_res_37 : 37|1@1+ (1,0) [0|1] ""  TRW_ESP
 SG_ MO3_res_38 : 38|1@1+ (1,0) [0|1] ""  TRW_ESP
 SG_ MO3_res_39 : 39|1@1+ (1,0) [0|1] ""  TRW_ESP
 SG_ MO3_FPGradient m1 : 56|8@1+ (25,0) [0|6350] "%/s"  TRW_ESP,Teves_MK60_ESP
 SG_ MO3_Vorz_RadWu : 36|1@1+ (1,0) [0|1] ""  TRW_ESP,DQ
 SG_ MO3_WunschDz : 48|8@1+ (25,0) [0|6350] "1/min"  TRW_ESP
 SG_ MO3_Rad_Wu_Mo : 24|12@1+ (0.39,0) [0|1596.66] "%MDI"  TRW_ESP,DQ
 SG_ MO3_DKW m0 : 56|8@1+ (0.4,0) [0|101.6] "%"  TRW_ESP
 SG_ MO3_Dz_Beeinfl : 40|8@1+ (0.39,0) [0|99.45] "%"  DQ,TRW_ESP,Hybrid_DQ200

BO_ 1420 mMotor_10: 8 Hybrid_MSG
 SG_ M10_Status_StSt : 8|2@1+ (1,0) [0|3] ""  Gateway_PQ35_A,Gateway_PQ46_A,ACC_Lidar,ACC_Radar,DQ,TRW_ESP,Teves_MK60_ESP
 SG_ M10_Druck_err_gem : 13|1@1+ (1,0) [0|1] ""  Gateway_PQ35_A,Gateway_PQ46_A
 SG_ M10_Anzeige : 0|4@1+ (1,0) [0|15] ""  Gateway_PQ35_A,Gateway_PQ46_A
 SG_ M10_Schubabschaltung : 12|1@1+ (1,0) [0|1] ""  Teves_MK60_ESP,Gateway_PQ35_A,Gateway_PQ46_A
 SG_ M10_rel_Saugrohrdruck : 16|6@1+ (18,0) [0|1116] "mbar"  Teves_MK60_ESP,Gateway_PQ35_A,Gateway_PQ46_A
 SG_ M10_Fahrbereitschaft : 22|1@1+ (1,0) [0|1] ""  EPS,Lenkhilfe_ZF_3G,EKlimakomp,Gateway_PQ35_A,Gateway_PQ46_A
 SG_ M10_Hybrid : 23|1@1+ (1,0) [0|1] ""  EPS,Lenkhilfe_ZF_3G,Gateway_PQ35_A,Gateway_PQ46_A
 SG_ M10_Freigabe_Reku : 14|2@1+ (1,0) [0|3] ""  Gateway_PQ35_A,Gateway_PQ46_A
 SG_ M10_VM_aktiv : 25|1@1+ (1,0) [0|1] ""  Gateway_PQ35_A,Gateway_PQ46_A
 SG_ M10_HYB_Bereitlampe : 26|1@1+ (1,0) [0|1] ""  Gateway_PQ35_A,Gateway_PQ46_A
 SG_ M10_HYB_Warnlampe : 27|1@1+ (1,0) [0|1] ""  Gateway_PQ35_A,Gateway_PQ46_A
 SG_ M10_HYB_Fehlerlampe : 28|1@1+ (1,0) [0|1] ""  Gateway_PQ35_A,Gateway_PQ46_A
 SG_ M10_Fehler_HV_Netz : 29|1@1+ (1,0) [0|1] ""  Gateway_PQ35_A,Gateway_PQ46_A
 SG_ M10_EKlKomLeiRed : 30|2@1+ (1,0) [0|1] ""  Gateway_PQ35_A,Gateway_PQ46_A
 SG_ M10_EM_aktiv : 24|1@1+ (1,0) [0|1] ""  Gateway_PQ35_A,Gateway_PQ46_A
 SG_ M10_Klimadruck : 32|8@1+ (0.2,0) [0|37] "bar"  Gateway_PQ46_A,Gateway_PQ35_A
 SG_ M10_KompAusCode : 40|4@1+ (1,0) [0|15] ""  Gateway_PQ46_A,Gateway_PQ35_A
 SG_ M10_Akustik : 46|2@1+ (1,0) [0|3] ""  Gateway_PQ35_A,Gateway_PQ46_A
 SG_ M10_ShiftLockLampe : 56|1@1+ (1,0) [0|1] ""  Gateway_PQ35_A,Gateway_PQ46_A
 SG_ M10_Text_1_Hybrid : 48|1@1+ (1,0) [0|1] ""  Gateway_PQ35_A,Gateway_PQ46_A
 SG_ M10_Text_2_Hybrid : 49|1@1+ (1,0) [0|1] ""  Gateway_PQ35_A,Gateway_PQ46_A
 SG_ M10_Text_4_Hybrid : 51|1@1+ (1,0) [0|1] ""  Gateway_PQ35_A,Gateway_PQ46_A
 SG_ M10_Text_5_Hybrid : 52|1@1+ (1,0) [0|1] ""  Gateway_PQ35_A,Gateway_PQ46_A
 SG_ M10_Text_6_Hybrid : 53|1@1+ (1,0) [0|1] ""  Gateway_PQ35_A,Gateway_PQ46_A
 SG_ M10_Text_7_Hybrid : 54|1@1+ (1,0) [0|1] ""  Gateway_PQ35_A,Gateway_PQ46_A
 SG_ M10_Text_8_Hybrid : 55|1@1+ (1,0) [0|1] ""  Gateway_PQ35_A,Gateway_PQ46_A
 SG_ M10_Text_3_Hybrid : 50|1@1+ (1,0) [0|1] ""  Gateway_PQ35_A,Gateway_PQ46_A
 SG_ M10_StSt_Lampe : 44|1@1+ (1,0) [0|1] ""  Gateway_PQ35_A,Gateway_PQ46_A
 SG_ M10_BattFanSpd : 60|4@1+ (10,0) [0|100] "%"  Gateway_PQ35_A,Gateway_PQ46_A
 SG_ M10_BMSInfo_gue : 58|1@1+ (1,0) [0|1] ""  Gateway_PQ35_A,Gateway_PQ46_A
 SG_ M10_VentilationReq : 59|1@1+ (1,0) [0|1] ""  Gateway_PQ35_A,Gateway_PQ46_A
 SG_ M10_res_06 : 6|1@1+ (1,0) [0|1] ""  Gateway_PQ46_A,Gateway_PQ35_A
 SG_ M10_MotorStopp : 10|1@1+ (1,0) [0|1] ""  Gateway_PQ35_A,Gateway_PQ46_A
 SG_ M10_Wiederstart : 11|1@1+ (1,0) [0|1] ""  Gateway_PQ35_A,Gateway_PQ46_A,ACC_Radar,ACC_Lidar,DQ,Teves_MK60_ESP,TRW_ESP
 SG_ M10_Anf_Kl75 : 4|1@1+ (1,0) [0|1] ""  Gateway_PQ46_A,Gateway_PQ35_A
 SG_ M10_Start_D_erl : 5|1@1+ (1,0) [0|1] ""  Gateway_PQ46_A,Gateway_PQ35_A,DQ
 SG_ M10_Blinken : 45|1@1+ (1,0) [0|1] ""  Gateway_PQ35_A,Gateway_PQ46_A
 SG_ M10_Start_D_gueltig : 57|1@1+ (1,0) [0|1] ""  Gateway_PQ35_A,Gateway_PQ46_A,DQ
 SG_ M10_UDruckDyn : 7|1@1+ (1,0) [0|1] ""  Gateway_PQ35_A,Gateway_PQ46_A,Teves_MK60_ESP

BO_ 513 mTP_Er_Motor: 7 Hybrid_MSG
 SG_ Motor_TP_Er : 0|56@1+ (1,0) [0|7.2057594038E+016] ""  Gateway_PQ46_A,Gateway_PQ35_A

BO_TX_BU_ 1352 : DQ,Hybrid_DQ200;
BO_TX_BU_ 2025 : DQ,AG6,Hybrid_DQ200;
BO_TX_BU_ 896 : Otto,Diesel,Hybrid_MSG;
BO_TX_BU_ 1420 : Otto,Diesel,Hybrid_MSG;
BO_TX_BU_ 513 : Otto,Diesel,Hybrid_MSG;
CM_ SG_ 1104 GE8_Checksumme "Checksumme
Prüfsumme, Definition im CAN Lastenheft";
CM_ SG_ 1104 GE8_Hydr_Pumpe "Hydraulikpumpe angesteuert
Momentenvorsteuerung der Leerlaufregelung muss erhöhtes Verlustmoment aussteuern";
CM_ SG_ 1104 GE8_Motor_aus "Motor aus
Motor soll beim Umschalten des Bits ausgeschaltet werden (Getriebeschutz)";
CM_ SG_ 1104 GE8_Anfahrfkt "Anfahrfunktion aktiv
Zwischen Motor und Getriebe gibt es für die Phase des Anfahrens eine besondere Funktion, bei der das Getriebe dem Motor eine Solldrehzahl und ein dazu passendes Vorsteuermoment vorgibt. Das Bit ?Anfahrfunktion aktiv? aktiviert die Funktion im Motor.";
CM_ SG_ 1104 GE8_SollDZ "Solldrehzahl für Anfahrfunktion
Zwischen Motor und Getriebe gibt es für die Phase des Anfahrens eine besondere Funktion, bei der das Getriebe dem Motor eine Solldrehzahl (Solldrehzahl für Anfahrfunktion) und ein dazu passendes Vorsteuermoment vorgibt.";
CM_ SG_ 1104 GE8_VorsteuerMom "Vorsteuermoment für Anfahrfunktion
Zwischen Motor und Getriebe gibt es für die Phase des Anfahrens eine besondere Funktion, bei der das Getriebe dem Motor eine Solldrehzahl (Solldrehzahl für Anfahrfunktion) und ein dazu passendes Vorsteuermoment (Vorsteuermoment für Anfahrfunktion) vorgibt.";
CM_ SG_ 1104 GE8_KuppMom "Kupplungsmoment für Anfahrfunktion
Zwischen Motor und Getriebe gibt es für die Phase des Anfahrens eine besondere Funktion, bei der das Getriebe dem Motor eine Solldrehzahl (Solldrehzahl für Anfahrfunktion) und ein dazu passendes Vorsteuermoment vorgibt. Im Fall, dass der Fahrer bei aktiver Anfahrfunktion plötzlich vom Gas geht, wird ein Überschwingen der Motordrehzahl wegen der sich plötzlich öffnenden Kupplung (Lastsprung) durch die Berücksichtigung des übertragenen Kupplungsmomentes verhindert.";
CM_ SG_ 1104 GE8_Zaehler "Botschaftszähler
Freilaufender Botschaftszähler";
CM_ SG_ 1104 GE8_res_15 " 
 ";
CM_ SG_ 1104 GE8_res_46 " 
 ";
CM_ SG_ 1104 GE8_res_47 " 
 ";
CM_ SG_ 1104 GE8_res_48 " 
 ";
CM_ SG_ 1104 GE8_res_49 " 
 ";
CM_ SG_ 1104 GE8_res_50 " 
 ";
CM_ SG_ 1104 GE8_res_52 " 
 ";
CM_ SG_ 1104 GE8_res_53 " 
 ";
CM_ SG_ 1104 GE8_res_54 " 
 ";
CM_ SG_ 1104 GE8_res_55 " 
 ";
CM_ SG_ 1104 GE8_res_56 " 
 ";
CM_ SG_ 1104 GE8_res_57 " 
 ";
CM_ SG_ 1104 GE8_res_51 " 
 ";
CM_ SG_ 1104 GE8_res_58 " 
 ";
CM_ SG_ 1104 GE8_res_59 " 
 ";
CM_ SG_ 1104 GE8_res_60 " 
 ";
CM_ SG_ 1104 GE8_res_61 " 
 ";
CM_ SG_ 1104 GE8_res_63 " 
 ";
CM_ SG_ 1104 GE8_res_62 " 
 ";
CM_ SG_ 1102 WH2_Fehler0 "Sensorarray Einzelfehler
Wird ein Einzelfehler im Sensorarray des Wählhebels erkannt, so wird dieses Bit gesetzt. Seitens Getriebesteuergerät erfolgt ein Fehlerspeichereintrag. Der Wählhebel funktioniert normal weiter.";
CM_ SG_ 1102 WH2_Testergebnis "Testergebnis (Wählhebel 2)
Ergebnis des Controllertests initiert durch Testfreigabeflag und Testparameter 1 + 2 aus Getriebe 5  Hier wird in Verbindung mit dem 'Test aktiv Flag' das gültige Testergebnis eines noch zu definierenden Frage- und Antwortspiels zur Überprüfung des Mikrokontrollers übertragen. Die Aufgabenstellung erfolgt über die beiden Bytes 'Testparameter 1 + 2', sowie über das Bit 'Testfreigabeflag' in der exklusiv für den Wählhebel gesendeten 'Getriebe 5¿ Botschaft. ;  ; Die Prüfung wird re";
CM_ SG_ 1102 WH2_Zaehler "Zähler (Wählhebel 2)
Freilaufender Botschaftszähler  Dient der Synchronisierung der Getriebebotschaften und stellt sicher, daß der Wählhebelrechner noch lebt, damit der Testmode nicht länger wie zwei Zyklen (20ms) aktiviert ist.";
CM_ SG_ 1102 WH2_Init "Wählhebel-Initialisierung
Das Bit zeigt dem Empfänger an, dass der Wählhebel in der Initialisierung war (z.B. Reset). Das Signal steht für 500ms ab Sendebeginn auf 1, danach dauerhaft auf 0.	";
CM_ SG_ 1102 WH2_Checksumme "Checksumme
Prüfsumme, Definition im CAN-Lastenheft";
CM_ SG_ 1102 WH2_Winter "Wintertaster
Das Bit zeigt an, dass der Fahrer den Wintermodus gewählt hat.";
CM_ SG_ 1102 WH2_Sport "Sporttaster
Das Bit zeigt an, dass der Fahrer den Sportmodus gewählt hat";
CM_ SG_ 1102 WH2_Reserve1 " 
 ";
CM_ SG_ 1102 WH2_Test_Flag "Test aktiv Flag (Wählhebel 2)
Controllertestergebnis gültig, Wählhebelposition kann evtl. nicht aktuell sein";
CM_ SG_ 1102 WH2_Position "Wählhebelposition (Wählhebel 2)
Wählhebel mit zwei stabilen Positionen (X und U). Zwischen X und U liegt die Zwischenposition V. Von X kann nach R getippt werden, der Wählhebel fällt danach zurück in X. Von U kann nach +, - und D getippt werden.";
CM_ SG_ 1102 WH2_Ruhestromfehler "Wählhebel Ruhestromfehler
Die Wählhebelelektronik enthält eine interne geschaltete Kl. 30 mit der die Hallsensoren versorgt werden. Bei Durchlegiertem Treiber werden die Hallsensoren dauerhaft versorgt, was zu einer erhöhten Ruhestromaufnahme führt. In diesem Fall wird das Bit gesetzt.";
CM_ SG_ 1102 WH2_Fehler2 "Sporttaster unterbrochen
Wird eine Unterbrechung der Verbindung zum Sporttaster erkannt, so wird dieses Bit gesetzt. Seitens Getriebesteuergerät erfolgt ein Fehlerspeichereintrag. Der Wählhebel funktioniert normal. Aktivierung der Sportfunktion nicht möglich.";
CM_ SG_ 1102 WH2_Fehler1 "Sensorarray Mehrfachfehler
Wird ein Mehrfachfehler im Sensorarray des Wählhebels erkannt, so wird dieses Bit gesetzt. Seitens Getriebesteuergerät erfolgt ein Fehlerspeichereintrag. Der Wählhebel wird deaktiviert. Im Kombstrument wird die Priorität 2 Warnmeldung ´Wählhjebel defekt, kein R-Gang´ angezeigt.";
CM_ SG_ 1102 WH2_Fehler4 "Unter-/ Überspannungsfehler
Verlässt die Versorgungsspannung den Bereich in dem ein störungsfreier Betrieb des Wählhebels gesichert ist, so wird dieses Bit gesetzt. Seitens Getriebesteuergerät erfolgt ein Fehlerspeichereintrag. Der Wählhebel funktioniert normal.";
CM_ SG_ 1102 WH2_Fehler5 "Kombi_2 message timeout
Der Wählhebel empfängt vom Kombi das Signal Kl58d für den Dimmwert der Anzeige am Wählhebel. Wird diese Botschaft nicht mehr empfangen, so wird der Dimmwert von der Hardware Kl58s verwendet. Ist auch Kl58s nicht verfügbar wird der maximale Helligkeitswert eingestellt. Seitens Getriebesteuergerät erfolgt ein Fehlerspeichereintrag. Der Wählhebel funktioniert normal.";
CM_ SG_ 1102 WH2_Fehler3 "Anzeige im Wählhebel defekt
Wird eine Falschausleuchtung der Getriebeposition am Wählhebel detektiert (Kurzschluss oder Unterbrechung des entsprechenden LED Treibers), so wird dieses Bit gesetzt. Seitens Getriebesteuergerät erfolgt ein Fehlerspeichereintrag. Der Wählhebel funktioniert normal. Die Positionsanzeige am Wählhebel wird bei Treiberunterbrechung abgeschaltet (keine Position ausgeleuchtet) und bei Treiberkurzschluss komplett eingeschaltet (alle Positionen ausgeleuchtet).";
CM_ SG_ 1102 WH2_Fehler7 "Gateway_Komfort_1 message timeout
Der Wählhebel empfängt aus der Gateway_Komfort_1 Botschaft das Sleep Acknowledge Bit zur Beendigung des Nachlaufes nach Kl. 15 AUS.  Fehlt die Botschalt Gateway_Komfort_1, so wird dieses Bit gesetzt. Seitens Getriebesteuergerät erfolgt ein Fehlerspeichereintrag. Der Wählhebel funktioniert bis Kl.15 AUS normal. Nach Klemme 15 AUS wird der Wählhebel nun 750ms nach dem Abschalten der Klemme 58s deaktiviert.";
CM_ SG_ 1102 WH2_Fehler6 "Getriebe_5 message timeout
Die Übertragung der Wählhebelposition an das Getriebesteuergerät ist durch ein Frage-Antwort Spiel abgesichert, dass die korrekte Bedienung von Getriebe_5 und Wählhebel_2 Botschaft voraussetzt. Fehlt die Botschalt Getriebe_5, so wird dieses Bit gesetzt. Der Wählhebel wird deaktiviert, die Anzeige am Wählhebel wird nicht mehr ausgeleuchtet. Seitens Getriebesteuergerät erfolgt ein Fehlerspeichereintrag.";
CM_ SG_ 1494 PLS_PL_exist "Parklückeninfo
Anzeige entsprechender Symbolik gem. HMI-Spezifikation  im Kombiinstrument";
CM_ SG_ 1494 PLS_mehrzg_aktiv "Mehrzügiges Einparken aktiv
Anzeige der Bedienbildschirme 'Mehrzügiges Einparken'";
CM_ SG_ 1494 PLS_Anf_Anz "Anforderung PLA-Anzeige
Nur Audi: Anforderung der Anzeige entsprechender Symbolik gem. HMI-Spezifikation  im Kombiinstrument in Abhängigkeit des Signals ?Parklücke links/rechts?, nachdem die PLA-Funktion über Tastendruck aktiviert wurde.Alle weiteren Signale des Bytes 1 werden nur zur Anzeige gebracht, wenn dieses Signal gesetzt ist.";
CM_ SG_ 1494 PLS_Pos_OK "Position Egofahrzeug
Anzeige der Parklückeninformationen gemäß HMI-Spezifikation.";
CM_ SG_ 1494 PLS_PL_Seite "Parklücke links/rechts
Anzeige der Parklückeninformationen gemäß HMI-Spezifikation.";
CM_ SG_ 1494 PLS_Meldungen "Meldungen PLA
Anzeige gemäß HMI-Spezifikation";
CM_ SG_ 1494 PLS_Lenk_Aktiv "Lenkeingriff aktiv
 ";
CM_ SG_ 1494 PLS_Akustik1 "Akustisches Signal 1
Nur Audi: Ausgabe bei Funktionsdeaktivierung oder Systemstörung";
CM_ SG_ 1494 PLS_Akustik2 "Akustisches Signal 2
Nur Audi: Das Signal dient der akustischen Signalisierung von PLA-Fehlerinformationen";
CM_ SG_ 1494 PLS_AnzeigePrio "Anzeige Priorität
Nur VW: Jeder Anzeigewunsch eines Piktogramms aus Byte 1 oder einer Meldung aus Byte 2 ist mit dieser Anzeigepriorität verknüpft. Entsprechend der Anzeigepriorität wird die Meldung in die Kombi-interne Prioritätenliste eingeordnet (s. Kombi-Spezifikation).Anforderung der Anzeige entsprechender Symbolik im Kombiinstrument gem. HMI-Spezifikation. Alle weiteren Signale des Bytes 1 und 2 werden nur zur Anzeige gebracht, wenn dieses Signal > 0 ist.";
CM_ SG_ 1494 PLS_Fahrtrichtg_mehrzg "Fahrtrichtung mehrzügig
In Kombination mit Bit Mehrzügiges Einparken aktiv und Bit Parklücke links/rechts Auswahl des Bildschirms";
CM_ SG_ 980 PL1_Stat_PLA_EPS "Status PLA EPS
16 Statuswerte (siehe LH PLA)";
CM_ SG_ 980 PL1_LW_Soll "Solllenkwinkel
positiver Lenkradwinkel: nach linksnegativer Lenkradwinkel: nach rechts";
CM_ SG_ 980 PL1_Zaehler "Botschaftszähler
Überlaufender Botschaftszähler, zur Lebenderkennung";
CM_ SG_ 980 PL1_Checksumme "Ckecksumme
Prüfsumme, Definition im CAN-Lastenheft";
CM_ SG_ 980 PL1_LW_Soll_Sign "VorzeichenSolllenkwinkel
Vorzeichen Solllenkwinkel";
CM_ SG_ 541 PLA_PDC_TP_Er "TP 2.0 Eroeffnungskanal
 ";
CM_ SG_ 1355 PA5_VMR_Abstand "Abstand vorne mitte rechts
FFh = kein Hindernis im Erfassungsbereich";
CM_ SG_ 1355 PA5_VL_Abstand "Abstand vorne links
FFh = kein Hindernis im Erfassungsbereich";
CM_ SG_ 1355 PA5_HL_Abstand "Abstand hinten links
FFh = kein Hindernis im Erfassungsbereich";
CM_ SG_ 1355 PA5_HR_Abstand "Abstand hinten rechts
FFh = kein Hindernis im Erfassungsbereich";
CM_ SG_ 1355 PA5_HML_Abstand "Abstand hinten mitte links
FFh = kein Hindernis im Erfassungsbereich";
CM_ SG_ 1355 PA5_HMR_Abstand "Abstand hinten mitte rechts
FFh = kein Hindernis im Erfassungsbereich";
CM_ SG_ 1355 PA5_VML_Abstand "Abstand vorne mitte links
FFh = kein Hindernis im Erfassungsbereich";
CM_ SG_ 1355 PA5_VR_Abstand "Abstand vorne rechts
FFh = kein Hindernis im Erfassungsbereich";
CM_ SG_ 1175 PH_Opt_Anzeige_V_ein "Optische Anzeige vorn aktiv
OPS vorne ist im Display aktiv bzw. Anzeigemodule vorne sind eingeschaltet";
CM_ SG_ 1175 PH_Opt_Anzeige_H_ein "Optische Anzeige hinten aktiv
OPS hinten ist im Display aktiv bzw. Anzeigemodule hinten sind eingeschaltet";
CM_ SG_ 1175 PH_Opt_Anz_V_Hindernis "Optische Anzeige vorn Hindernis
mindestens 1 Segment wird für den vorderen Detekionsbereich dargestellt, also ein Hindernis ist im Detektionsbereich";
CM_ SG_ 1175 PH_Abschaltursache "Abschaltursache
Abschaltursache bleibt bis zur nächsten Aktivierung bzw. bis KL15 aus gesetzt0 = keine, bzw. System aktiv1 = Abschaltung durch Herausnahme R-Gang2 = Abschaltung ueber Geschwindigkeit3 = Abschaltung ueber PDC-Taster4 = Abschaltung wegen PLA5 = Abschaltung durch Kl.15 Bit=07 = Fehler-/gestört Zustand, System noch aktiv";
CM_ SG_ 1175 PH_Opt_Anz_H_Hindernis "Optische Anzeige hinten Hindernis
mindestens 1 Segment wird für den hinteren Detekionsbereich dargestellt, also ein Hindernis ist im Detektionsbereich";
CM_ SG_ 1175 PH_Tongeber_V_aktiv "Tongeber vorn aktiv
Rohsignal für ´Tongeber vorne wird angesteuert´, verlängerbar mit Nachlauftimer";
CM_ SG_ 1175 PH_Tongeber_mute "Tongeber Mute
1 = Tongeber stummgeschaltet";
CM_ SG_ 1175 PH_Frequenz_hinten " 
Uebertragung der aktuell im APS Steuergeraet gespeicherten Werte fuer Tongeber Frequenz hinten";
CM_ SG_ 1175 PH_Lautstaerke_hinten " 
Uebertragung der aktuell im APS Steuergeraet gespeicherten Werte fuer Tongeber Lautstaerke hinten";
CM_ SG_ 1175 PH_Tongeber_H_aktiv "Tongeber hinten aktiv
Rohsignal für ´Tongeber hinten wird angesteuert´, verlängerbar mit Nachlauftimer";
CM_ SG_ 1175 PH_Frequenz_vorn " 
Uebertragung der aktuell im APS Steuergeraet gespeicherten Werte fuer Tongeber Frequenz vorne";
CM_ SG_ 1175 PH_Lautstaerke_vorn " 
Uebertragung der aktuell im APS Steuergeraet gespeicherten Werte fuer Tongeber Lautstaerke vorn.";
CM_ SG_ 1175 PH_defekt " 
ein Fehler ist aufgetreten, der die Parkhilfe in den Fehlerzustand versetzt, Signal bleibt bis zur nächste ´Gut-Aktivierung´ gesetzt";
CM_ SG_ 1175 PH_Anf_Audioabsenkung "Anforderung Audioabsenkung
1 = Anforderung an das Audiosystem für Absenkung der Lautstärke";
CM_ SG_ 1175 PH_Systemzustand " 
Aktivierungsursache wird für die Dauer der Aktivierung gemeldetIm Fehlerfall bei aktivem System wechselt das Signal auf ´7´(siehe auch ´Abschaltursache´)";
CM_ SG_ 1175 PH_Display_Kundenwunsch " 
Anzeige der aktuell verwendeten Parameter bzgl. Kundenwunsch Displayanziege bei Aktivierung (nicht zwingend die abgespeicherten !)";
CM_ SG_ 1175 PH_KD_Fehler " 
mindestens ein Fehler ist im Kundendienstfehlerspeicher eingetragen";
CM_ SG_ 1175 PH_gestoert " 
eine Störung ist aufgetreten, der die Parkhilfe in einen ´gestört-Zustand´ versetzt, z.B. massiver Fremdultraschall, Vereisung, Schnee";
CM_ SG_ 1175 PH_res_02 " 
 ";
CM_ SG_ 1175 PH_res_04 " 
 ";
CM_ SG_ 1175 PH_res_01 " 
 ";
CM_ SG_ 1175 PH_res_00 " 
 ";
CM_ SG_ 1175 PH_res_05 " 
 ";
CM_ SG_ 1175 PH_res_03 " 
 ";
CM_ SG_ 1175 PH_res_06 " 
 ";
CM_ SG_ 1175 PH_res_07 " 
 ";
CM_ SG_ 1175 PH_res_08 " 
 ";
CM_ SG_ 1175 PH_res_10 " 
 ";
CM_ SG_ 1175 PH_res_11 " 
 ";
CM_ SG_ 1175 PH_res_12 " 
 ";
CM_ SG_ 1175 PH_res_09 " 
 ";
CM_ SG_ 1175 PH_res_25 " 
 ";
CM_ SG_ 1175 PH_res_26 " 
 ";
CM_ SG_ 1175 PH_res_27 " 
 ";
CM_ SG_ 1175 PH_res_24 " 
 ";
CM_ SG_ 1175 PH_res_28 " 
 ";
CM_ SG_ 1175 PH_res_30 " 
 ";
CM_ SG_ 1175 PH_Trigger_Bildaufschaltung " 
nur Audi für OPS in der RNS-E";
CM_ SG_ 1175 PH_Aufbauten_erk " 
 ";
CM_ SG_ 1175 PH_res_29 " 
 ";
CM_ SG_ 1175 PH_BerErk_vorn " 
 ";
CM_ SG_ 1175 PH_res_31 " 
 ";
CM_ SG_ 1175 PH_StartStopp_Info " 
Stopp-Freigabe/Start-Anforderung für den Start-Stopp-Koordinator";
CM_ SG_ 1175 PH_BerErk_hinten " 
 ";
CM_ SG_ 1754 BAP_var_OPS " 
 ";
CM_ SG_ 1754 BAP_Data_OPS " 
 ";
CM_ SG_ 1528 Controller_ID_5 " 
 ";
CM_ SG_ 1528 Data_Byte_1_5 "Datenbyte 1
Festlegung der Datenbytes siehe CAN Data Exchange Function Datenfestlegung";
CM_ SG_ 1528 CDEF_APS_AB_res_5 " 
 ";
CM_ SG_ 1528 Data_Byte_4_5 "Datenbyte 4
Festlegung der Datenbytes siehe CAN Data Exchange Function Datenfestlegung";
CM_ SG_ 1528 Data_Byte_2_5 "Datenbyte 2
Festlegung der Datenbytes siehe CAN Data Exchange Function Datenfestlegung";
CM_ SG_ 1528 Data_Byte_3_5 "Datenbyte 3
Festlegung der Datenbytes siehe CAN Data Exchange Function Datenfestlegung";
CM_ SG_ 1528 Module_ID_5 "APS
 ";
CM_ SG_ 1528 OpCode_5 " 
 ";
CM_ SG_ 1528 Data_Byte_5_5 "Datenbyte 5
Festlegung der Datenbytes siehe CAN Data Exchange Function Datenfestlegung";
CM_ SG_ 1528 Funktions_ID_5 " 
 ";
CM_ SG_ 1528 Update_Indikator_5 " 
 ";
CM_ SG_ 1908 ISO_EPH_Resp_Data "ISO Response Kanal
 ";
CM_ SG_ 714 QS2_Ist_Wert "Ist-Wert
Aktuell eingestelltes Kupplungs-(Sperr-)Moment";
CM_ SG_ 714 QS2_Gleichlauf "Gleichlauf
Dient der Qualifizierung des Ist-Sperrmoments, da dieses nicht während Gleichlauf berechnet werden kann";
CM_ SG_ 714 QS2_KD_Fehler "Kundendienstfehler
Bei gesetztem Bit ist mindestens ein Kundendienstfehler eingetragen";
CM_ SG_ 714 QS2_Soll_Wert "Soll-Wert
Bei Fremdsteuerung durch ESP erscheint  hier der Wunschsperrgrat, den die Sperre ohne ESPeinstellen würde.Im unbeeinflussten Fall sind Ist- und Sollwert identisch";
CM_ SG_ 714 QS2_res_26 " 
 ";
CM_ SG_ 714 QS2_Status_VAQ "Statusmaschine: VAQ Status
 ";
CM_ SG_ 536 Quersperre_TP_Er "TP 2.0 Eroeffnungskanal
 ";
CM_ SG_ 1404 BY1_KD_Fehler "Kundendienstfehler
Info für Diagnose; bei gesetztem Bit befindet sich mindestens ein Kundendienstfehler im Fehlerspeicher";
CM_ SG_ 1404 BY1_res_01 " 
 ";
CM_ SG_ 1404 BY1_res_02 " 
 ";
CM_ SG_ 1404 BY1_res_03 " 
 ";
CM_ SG_ 1404 BY1_res_04 " 
 ";
CM_ SG_ 1404 BY1_res_05 " 
 ";
CM_ SG_ 1404 BY1_res_06 " 
 ";
CM_ SG_ 1404 BY1_res_07 " 
 ";
CM_ SG_ 1406 EY1_KD_Fehler "Kundendienstfehler
Info für Diagnose; bei gesetztem Bit befindet sich mindestens ein Kundendienstfehler im Fehlerspeicher";
CM_ SG_ 1406 EY1_res_01 " 
 ";
CM_ SG_ 1406 EY1_res_02 " 
 ";
CM_ SG_ 1406 EY1_res_03 " 
 ";
CM_ SG_ 1406 EY1_res_04 " 
 ";
CM_ SG_ 1406 EY1_res_05 " 
 ";
CM_ SG_ 1406 EY1_res_07 " 
 ";
CM_ SG_ 1406 EY1_res_06 " 
 ";
CM_ SG_ 1352 GE4_Shiftlock "Shiftlock
Shiftlockaktivierung";
CM_ SG_ 1352 GE4_Ausleuchtung "Wählhebelausleuchtung
Mit dieser Botschaft wird die aktive Istgangausleuchtung des Wählhebels gesteuert.";
CM_ SG_ 1352 GE4_AuslModus "Ausleuchtungsmodus für Wählhebel
Bei RDW ist die Ausleuchtungsdauer begrenzt (Wählhebel nicht in P)";
CM_ SG_ 1352 GE4_res_03 " 
 ";
CM_ SG_ 1352 GE4_Testparam_1 "Testparameter 1
Testparameter 1 zum Funktionstest des Wählhebel-Controllers";
CM_ SG_ 1352 GE4_Testparam_2 "Testparameter 2
Testparameter 2 zum Funktionstest des Wählhebel-Controllers";
CM_ SG_ 1352 GE4_Test "Testfreigabeflag
Controllertest mit den Testparametern 1 + 2 durchführen";
CM_ SG_ 1106 GH1_FreigabeVMStop "Freigabe VM Stop
Signalisiert Bereitschaft GSG, dass VM gestoppt werden darf (Soft Stop) oder dass EM gestoppt werden darf (Übergang EM-Fahren => EM-Fahrbereitschaft)";
CM_ SG_ 1106 GH1_Zaehler "Botschaftszähler
Freilaufender Botschaftszähler";
CM_ SG_ 1106 GH1_FreigabeK0 "Freigabe K0
Übergang von 0 nach 1 (bzw. 1 nach 0) ist Teil des Wiederstart- (Stop-) Handshakes";
CM_ SG_ 1106 GH1_nK0 "Drehzahl nach Schließen K0
Nur PQ35 Hybrid:GSG teilt MSG mit, auf welcher DZ die EM nach schnellem Schließen der K0 und nach DZAngleichung durch das GSG landen wird.Wenn Bit7 Byte3 nicht aktiv: EM-Drehzahl wird gespiegeltWenn Bit7 Byte3 aktiv: DZ, auf der Motor nach Schließen K0 und nach DZAngleichung drehen wird(fester Gang: Synchron-DZ, Kriechen: LL-Soll-DZ, Anfahren: um Makroschlupf bereinigte Motor-DZ, Schaltung: Synchron-DZ des Zielganges)Nicht benutzt für PL71 Hybrid";
CM_ SG_ 1106 GH1_MomEingriff_EM "Betrag Getriebeeingriff auf EM
Nur PQ35 Hybrid: Direkter Eingriff des GSG auf EM.Ist der Betrag des Absolutwertes des Eingriffsmomentes in Nm. Verwendet zur Dämpfung des Triebstranges nach Impulsstart, wenn VM-Momente noch ungenau sind.E-Gas-Sicherheit: begrenzt auf 30Nm, zusätzlich muss Zeitintegral Null sein(nicht benutzt für PL71 Hybrid)";
CM_ SG_ 1106 GH1_FehlerstatusGSG "Fehlerstati GSG
Hybrid-spezifische FehlerstatiPQ35: Fehlerstatus 1 signalisiert, dass der Druckzum Öffnen der K0 nicht ausreicht (nach Kl15 ein)PL71: Fehlerstatus 1 signalisiert eine unzureichendeDruckversorgung durch die EOP.Fehlerstatus 2: Verhinderung ungewollten Vortriebs";
CM_ SG_ 1106 GH1_Wiederstart "Wiederstart aktiv
Getriebe zeigt an, ob Wiederstart aktiv ist";
CM_ SG_ 1106 GH1_VZMomEingriff "Vorzeichen Getriebeeingriff auf EM
PQ35 Hybrid: Vorzeichen für Getriebeeingriff auf EM (Byte 3, Bit 6..1)";
CM_ SG_ 1106 GH1_Sportfaktor "Sportfaktor
Sportlichkeitsfaktor Getriebe, zur Verwendung in der Hybrid-Fahrstrategie0 = nicht sportlich1..15 = sportlich";
CM_ SG_ 1106 GH1_Freig_LL_Reg "Freigabe LL-Regelung
GSG gibt hier die Aktivierung einer DZ-Regelung von VM und/oder EM frei.(Verhinderung Selbstbeschleuniger)";
CM_ SG_ 1106 GH1_VM_akt_halten "VM aktiv halten
Im elektrischen Fahren/Tip: Übergang von 0 auf 1 zeigt VM-Startanforderung des GSG an.Ansonsten: Empfehlung GSG an MSG, dass VM aktiv gehalten werden soll. Verwendbar zB bei den Funktionen fast off (Gang halten) oder bei Rückschaltung bei Bremsen";
CM_ SG_ 1106 GH1_VKM_StKontr "VKM Startkontrolle
Freigabe der WiederstartkontrolleNur zur abgestimmten Verwendung zwischen Hybridcontroller (MSG) und Getriebe (GSG)";
CM_ SG_ 1106 GH1_VKM_StAnf "VKM Startanforderung
Auslösen des VM-Wiederstart im elektromot. BetriebNur zur abgestimmten Verwendung zwischen Hybridcontroller (MSG) und Getriebe (GSG)";
CM_ SG_ 2025 ISO_Getriebe_01_Resp_Data "ISO Response Kanal
 ";
CM_ SG_ 1090 GM3_QB_LangEingr "Qualifizierungsbit Langfristiger Eingriff
Definition nach CAN Lastenheft";
CM_ SG_ 1090 GM3_Moment "Moment
Moment des Moment-Zeit-PaaresAnmerkung: Der Faktor zur Normierung der Momente (0,25, 0,5, 1, 2) wird zukünftig aus der ´Motor_Momente´-Botschaft entnommen (vorrübergehend 1)";
CM_ SG_ 1090 GM3_Checksum "Checksumme (Getriebe_3_Momente)
Prüfsumme, Definition im CAN Lastenheft";
CM_ SG_ 1090 GM3_res_13 " 
 ";
CM_ SG_ 1090 GM3_res_15 " 
 ";
CM_ SG_ 1090 GM3_MoSoMom "Motorsollmoment, Getriebeeingriff
Hybrid:Getriebeeingriff auf indiziertes Moment (Absolutwert).- Reduzierendes Moment kann auch von EM erzeugt werden => Eingriff beinhaltet auch EMAnteile.- Erhöhendes Moment kann auch von EM erzeugt werden => Eingriff beinhaltet auch EM-Anteile.";
CM_ SG_ 1090 GM3_MomID "Momenten-Ident
Zur Identifizierung der Moment-Zeit-Paare";
CM_ SG_ 1090 GM3_MomEingr "Freigabe Momenteneingriffsanforderung
Freigabe-Bit z. Zt. nur für Luftpfad-Eingriff gültig: ´Eine möglichr Anforderung Momentenreduktion für Hochschaltungen kann umgesetzt werden´, Näheres im Lastenheft LuftpfadHybrid:PQ35H: parallel zu Byte 1 Bit 7 aus Getriebe 1.";
CM_ SG_ 1090 GM3_StaSoMom "Status Sollmoment
 ";
CM_ SG_ 1090 GM3_Zaehler "Zähler (Getriebe_3_Momente)
Freilaufender Botschaftszähler";
CM_ SG_ 1090 GM3_res_61 " 
 ";
CM_ SG_ 1090 GM3_res_14 " 
 ";
CM_ SG_ 1090 GM3_LangEingr "Langfristiger Eingriff
Getriebeschutzmoment";
CM_ SG_ 1090 GM3_res_63 " 
 ";
CM_ SG_ 1090 GM3_Zeit "Zeit
Zeit des Moment-Zeit-Paares";
CM_ SG_ 1090 GM3_res_62 " 
 ";
CM_ SG_ 1526 EK1_Comp_main_stat "EK1_Comp_main_stat
Real compressor status not CAN board status";
CM_ SG_ 1526 EK1_Comp_ovld_stat "EK1_Comp_ovld_stat
Diagnosis series 1 'Over load'´0´ normal´2´ current restriction´3´ software over current´4´ over load´6´ over input current";
CM_ SG_ 1526 EK1_Comp_output_stat "EK1_Comp_output_stat
Diagnosis series 1 'Output'´0´ normal´1´ output line short´2´ output line cut out´3´ abnormal current detection";
CM_ SG_ 1526 EK1_res_08 " 
 ";
CM_ SG_ 1526 EK1_Comp_photo_temp_stat "EK1_Comp_photo_temp_stat
Diagnosis series 2 'Inverter temp.'´0´ normal´1´ over heat L´2´ over heat S´3´ sermister abnormal";
CM_ SG_ 1526 EK1_Comp_Inv_stat "EK1_Comp_Inv_stat
Diagnosis series 2 'Startability'´0´ normal´1´ start fail´2´ temp protection´3´ system abnormal stop";
CM_ SG_ 1526 EK1_KD_Fehler "Kundendienstfehler
Mind. ein Kundendienstfehler ist eingetragen";
CM_ SG_ 1526 EK1_Comp_rev_stat "EK1_Comp_rev_stat
compressor real revolution0-8624 rpm is outputted´output = (actual speed + 25) / 50´   speed over 8625rpm: ´172´";
CM_ SG_ 1526 EK1_Comp_SCI_com_stat "EK1_Comp_SCI_com_stat
´00´ normal´x1´ CAN_error (abnormal)´1x´ Inverter_error";
CM_ SG_ 1526 EK1_Comp_current "EK1_Comp_current
Compressor input current";
CM_ SG_ 1526 EK1_Comp_photo_temp "EK1_Comp_photo_temp
IGBT temp. measured by inverter.Photo coupler temp. is not  measured in compressor temp. of IGBT (same as EK1_Comp_Inv_temp) will be sent";
CM_ SG_ 1526 EK1_res_40 " 
 ";
CM_ SG_ 1526 EK1_res_14 " 
 ";
CM_ SG_ 1923 ISO_EKomp_Resp_Data "ISO Response Kanal
 ";
CM_ SG_ 1650 BAP_var_SWA " 
 ";
CM_ SG_ 1650 BAP_Data_SWA " 
 ";
CM_ SG_ 954 SWA_Gong "Gong
Gong 1 als FahrerhinweisGong 2 als Fahrerwarnung";
CM_ SG_ 954 SWA_Textbits "Textbits
SWA FehlertextanzeigeAUDI:Text 1: 'Audi Side Assist zur Zeit nicht verfügbar'Text 2: 'Audi Side Assist: Systemfehler'Text 3: 'Audi Side Assist nicht verfügbar: Sensor blockiert.'Text 4: 'Audi Side Assist im Anhängerbetrieb nicht verfügbar'VW:Text 1: 'SVA zur Zeit nicht verfügbar'Text 2: 'SVA Systemfehler'Text 3: 'SVA nicht verfügbar: Sensor blockiert'Text 4: 'SVA im Anhängerbetrieb nicht verfügbar'";
CM_ SG_ 954 SWA_Sta_passiv "SWA Status passiv
Lampenansteuerung gelb im Kombiinstrument";
CM_ SG_ 954 SWA_KD_Fehler "Fehlerspeichereintrag
Bei gesetztem Bit ist mindestens ein Kundendienstfehler eingetragen";
CM_ SG_ 954 SWA_res_00 " 
 ";
CM_ SG_ 954 SWA_res_01 " 
 ";
CM_ SG_ 954 SWA_res_02 " 
 ";
CM_ SG_ 954 SWA_res_03 " 
 ";
CM_ SG_ 954 SWA_res_06 " 
 ";
CM_ SG_ 954 SWA_res_07 " 
 ";
CM_ SG_ 954 SWA_Sta_aktiv "SWA Status aktiv
Lampenansteuerung grün im Kombiinstrument";
CM_ SG_ 954 SWA_res_04 " 
 ";
CM_ SG_ 954 SWA_res_05 " 
 ";
CM_ SG_ 954 SWA_res_08 " 
 ";
CM_ SG_ 954 SWA_res_09 " 
 ";
CM_ SG_ 954 SWA_res_10 " 
 ";
CM_ SG_ 954 SWA_res_11 " 
 ";
CM_ SG_ 954 SWA_res_21 " 
 ";
CM_ SG_ 954 SWA_res_22 " 
 ";
CM_ SG_ 954 SWA_res_23 " 
 ";
CM_ SG_ 954 SWA_res_18 " 
 ";
CM_ SG_ 954 SWA_res_24 " 
 ";
CM_ SG_ 954 SWA_res_25 " 
 ";
CM_ SG_ 954 SWA_res_26 " 
 ";
CM_ SG_ 954 SWA_res_27 " 
 ";
CM_ SG_ 954 SWA_res_28 " 
 ";
CM_ SG_ 954 SWA_res_30 " 
 ";
CM_ SG_ 954 SWA_res_31 " 
 ";
CM_ SG_ 954 SWA_res_32 " 
 ";
CM_ SG_ 954 SWA_res_29 " 
 ";
CM_ SG_ 954 SWA_res_33 " 
 ";
CM_ SG_ 954 SWA_res_34 " 
 ";
CM_ SG_ 954 SWA_res_35 " 
 ";
CM_ SG_ 954 SWA_res_38 " 
 ";
CM_ SG_ 954 SWA_res_39 " 
 ";
CM_ SG_ 954 SWA_res_40 " 
 ";
CM_ SG_ 954 SWA_res_37 " 
 ";
CM_ SG_ 954 SWA_res_41 " 
 ";
CM_ SG_ 954 SWA_res_36 " 
 ";
CM_ SG_ 954 SWA_res_42 " 
 ";
CM_ SG_ 954 SWA_res_43 " 
 ";
CM_ SG_ 954 SWA_res_44 " 
 ";
CM_ SG_ 954 SWA_res_45 " 
 ";
CM_ SG_ 954 SWA_res_47 " 
 ";
CM_ SG_ 954 SWA_res_48 " 
 ";
CM_ SG_ 954 SWA_res_46 " 
 ";
CM_ SG_ 954 SWA_res_50 " 
 ";
CM_ SG_ 954 SWA_res_49 " 
 ";
CM_ SG_ 954 SWA_res_51 " 
 ";
CM_ SG_ 954 SWA_res_52 " 
 ";
CM_ SG_ 954 SWA_res_53 " 
 ";
CM_ SG_ 954 SWA_res_55 " 
 ";
CM_ SG_ 954 SWA_res_57 " 
 ";
CM_ SG_ 954 SWA_res_54 " 
 ";
CM_ SG_ 954 SWA_res_60 " 
 ";
CM_ SG_ 954 SWA_res_61 " 
 ";
CM_ SG_ 954 SWA_res_56 " 
 ";
CM_ SG_ 954 SWA_res_63 " 
 ";
CM_ SG_ 954 SWA_res_58 " 
 ";
CM_ SG_ 954 SWA_res_62 " 
 ";
CM_ SG_ 540 SWA_TP_Er "TP 2.0 Eroeffnungskanal
 ";
CM_ SG_ 1651 BAP_Data_LDW " 
 ";
CM_ SG_ 1651 BAP_var_LDW " 
 ";
CM_ SG_ 1470 LDW_Lampe_gelb "LDW Lampe gelb
Lampenansteuerung gelb im Kombiinstrument";
CM_ SG_ 1470 LDW_Gong "Gong
 ";
CM_ SG_ 1470 LDW_Lampe_gruen "LDW Lampe grün
Lampenansteuerung grün im Kombiinstrument";
CM_ SG_ 1470 LDW_KD_Fehler "Fehlerspeichereintrag
Bei gesetztem Bit ist mindestens ein Kundendienstfehler eingetragen";
CM_ SG_ 1470 LDW_res_00 " 
 ";
CM_ SG_ 1470 LDW_Textbits "Textbits
Audi: LDW FehlertextanzeigeText 1: LDW zur Zeit nicht verfügbarText 2: LDW SystemfehlerText 3: LDW Frontscheibe außen reinigenVW: Heading Control Textmeldungen:Text1: Heading Control: zur Zeit nicht verfügbarText2: Heading Control: SystemfehlerText3: Heading Control: nicht verfügbar: zur Zeit keine SensorsichtText4: Heading Control: FahrerübernahmeText5: Heading Control: keine Funktion bei AnhängerbetriebKeine Gongauslösung durch Textbits";
CM_ SG_ 1470 LDW_res_01 " 
 ";
CM_ SG_ 1470 LDW_res_02 " 
 ";
CM_ SG_ 1470 LDW_res_03 " 
 ";
CM_ SG_ 1470 LDW_res_05 " 
 ";
CM_ SG_ 1470 LDW_res_06 " 
 ";
CM_ SG_ 1470 LDW_res_07 " 
 ";
CM_ SG_ 1470 LDW_res_08 " 
 ";
CM_ SG_ 1470 LDW_Lernmodus "Lernmodus
Ansteuerung von LDW-Funktionsanzeigen im Mitteldisplay Kombiinstrument analog B8/Q5 (im AU716, C6)";
CM_ SG_ 1470 LDW_res_04 " 
 ";
CM_ SG_ 1470 LDW_res_18 " 
Vorhalt für Warnzustand (nur VW)";
CM_ SG_ 1470 LDW_res_21 " 
Vorhalt für Lampenansteuerung rot im VW-Kombiinstrument";
CM_ SG_ 1470 LDW_res_22 " 
Vorhalt für Anforderung des LDW-SG zum Einschalten der Frontscheibenheizung (nicht AU716)";
CM_ SG_ 538 LDW_TP_Er "TP 2.0 Eroeffnungskanal
 ";
CM_ SG_ 210 HC1_Checksumme "Checksumme
Prüfsumme, Definition im CAN-Lastenheft";
CM_ SG_ 210 HC1_Zaehler "Freilaufender Botschaftszähler
Definition im CAN-Lastenheft";
CM_ SG_ 210 HC1_Sta_HCA "Status HCA
0: HCA deaktiviert1: HCA Anforderung nicht ausführbar (Lenkung Fehlerstatus)2: Kommunikation zum Lenkhilfe-SG gestört3: HCA funktionsbereit4: reserviert5: externer Momenteneingriff angefordert";
CM_ SG_ 210 HC1_LM_Offset "Anforderung Lenkmomenten-Offset
Reale Auflösung 0,01 Nm";
CM_ SG_ 210 HC1_LM_Offset_Sign "Lenkmomenten-Offset-Sign
Vorzeichen Anforderung Lenkmomenten-Offset";
CM_ SG_ 210 HC1_Frequenz "Frequenz
Frequenz der Lenkradvibration";
CM_ SG_ 210 HC1_Amplitude "Amplitude
Amplitude der Lenkradvibration";
CM_ SG_ 1985 ISO_ACC_Resp_Data "ISO Response Kanal
 ";
CM_ SG_ 1916 ISO_Lenkhilfe_Resp_Data "ISO Response Kanal
 ";
CM_ SG_ 534 FLA_TP_Er "TP 2.0 Eroeffnungskanal
 ";
CM_ SG_ 1626 FL1_Reserve01 " 
 ";
CM_ SG_ 1626 FL1_Reserve02 " 
 ";
CM_ SG_ 1626 FL1_KD_Fehler "Kundendienstfehler
mindestens ein Fehler ist im Kundendienstfehlerspeicher eingetragen";
CM_ SG_ 1626 FL1_FLA_aktiv "FLA aktiv
FLA aktiv";
CM_ SG_ 1626 FL1_ISP_defekt "FLA Innenspiegel defekt
FLA Innenspiegel defektinterner Fehler";
CM_ SG_ 1626 FL1_Sensor_blockiert "FLA Sensor blockiert
FLA Sensor blockiertSichtbeeinträchtigung CMOS-Kamera";
CM_ SG_ 1626 FL1_Abblendursache "FLA Abblendursache
FLA Abblendursache0x0 keine0x1 entgegenkommendes Fahrzeug0x2 vorausfahrendes Fahrzeug0x4 Geschwindigkeitslimit unterschritten0x8 Ort erkannt0x10 Umgebungshelligkeit generell zu hell, Abblendlicht aus0x20 Nebel erkannt0x40 Übertemperatur Imager0x80 Verzögerungsbedingung0xFF Fehler";
CM_ SG_ 1626 FL1_Fernlicht_PWM "FLA Fernlicht PWM
FLA PWM Vorgabe Fernlicht";
CM_ SG_ 1626 FL1_ISP_Lichtwert_vo "ISP Lichtwert vorne
Innenspiegel: Lichtwert vorne";
CM_ SG_ 1626 FL1_ISP_Lichtwert_hi "ISP Lichtwert hinten
Innenspiegel: Lichtwert hinten";
CM_ SG_ 1626 FL1_ISP_Taste "ISP Taste betätigt
Innenspiegel Taste betätigt";
CM_ SG_ 1626 FL1_ISP_EC_aktiv "ISP EC aktiv
Status Innenspiegel (EC-Spiegel)";
CM_ SG_ 1626 FL1_ISP_Kompass_aktiv "ISP Kompass aktiv
Status Kompass Innenspiegel";
CM_ SG_ 1626 FL1_Dimmwert_ASP "ISP Dimmwert ASP
Dimmwertvorgabe für Aussenspiegel0x0 - 0x3E = Dimmwert (0-62 = 0-100%)";
CM_ SG_ 1626 FL1_FLA_Aufblenden "FLA Aufblenden
FLA Aufblenden";
CM_ SG_ 1626 FL1_ISP_Himmelsrichtung "ISP Himmelsrichtung
Himmelsrichtung Kompass im EC SpiegelWertebereich 0-29 (12°-Schritte, 0-348°)12 x Wert [Grad]0x1E nicht verfügbar / Init0x1F Fehler";
CM_ SG_ 1626 FL1_res_31 " 
 ";
CM_ SG_ 1626 FL1_res_38 " 
 ";
CM_ SG_ 1626 FL1_res_39 " 
 ";
CM_ SG_ 1626 FL1_res_46 " 
 ";
CM_ SG_ 1626 FL1_res_63 " 
 ";
CM_ SG_ 1626 FL1_res_47 " 
 ";
CM_ SG_ 1100 GE6_Checksum "Checksumme (Getriebe_6)
Prüfsumme, Definition im CAN Lastenheft";
CM_ SG_ 1100 GE6_Zaehler "Zähler (Getriebe_6)
Freilaufender Botschaftszähler";
CM_ SG_ 1100 GE6_res_48 " 
 ";
CM_ SG_ 1100 GE6_OelTemp "Getriebeöltemperatur
Getriebeöltemperatur";
CM_ SG_ 1100 GE6_res_42 " 
 ";
CM_ SG_ 1100 GE6_maxBeschl "Max. Beschleunigung Getriebe
max. Beschleunigung Getriebe für Audi ACC-Projekte";
CM_ SG_ 1100 GE6_Verlustmom "Getriebeverlustmoment ACC/GRA
gesamtes Verlustmoment von Zentralgetriebe incl. Vorderachsdifferential (und Zentraldifferential / Verteilergetriebe bei quattro) Nutzung im ACC, GRA und Triebstrangkoordinator im Motor (nur AU716 und D3, nicht für andere Projekte verwenden!)";
CM_ SG_ 1100 GE6_QmaxBeschl "Qualifizierungsbit max. Beschleunigung
Definition im CAN Lastenheft";
CM_ SG_ 1100 GE6_QB_OelTemp "Qualifizierungsbit Getriebeöltemperatur
Definition im CAN Lastenheft";
CM_ SG_ 1100 GE6_Zielgang_err "Zielgang erreicht
Das Bit wird gesetzt, wenn der Betrag der Differenz zwischen Getriebeeingangsdrehzahl und Produkt aus Getriebeausgangsdrehzahl und Übersetzung des Zielgangs einen getriebeseitig applizierbaren Schwellwert unterschreitet. Das Bit wird zurückgesetzt, wenn das Bit ´Schaltung aktiv´ gesetzt wird (Beginn der nächsten Schaltung). Sonderfall Mehrfachschaltung: Im Falle einer Mehrfachschaltung erfolgt das Rücksetzen des Bits ´Zielgang erreicht´ entweder zeitgesteuert oder über die Bedingung für ";
CM_ SG_ 1100 GE6_Gangwechsel "Gangwechsel
Das Bit wird gesetzt, wenn das Bit ´Schaltung aktiv´ gesetzt ist und der Betrag der Differenz zwischen dem Produkt aus Getriebeausgangsdrehzahl und Übersetzung des Istgangs und der Getriebeeingangsdrehzahl einen getriebeseitig applizierbaren Schwellwert überschreitet. Das Bit wird zurückgesetzt mit der positiven Flanke von ´Zielgang erreicht´, wenn keine Weiterschaltung erfolgt, sonst mit der positiven Flanke von ´Zielgang erreicht´ des letzten Gangwechsels. Sonderfall Schaltung im Stand: Das ";
CM_ SG_ 1100 GE6_TurbDZ "Turbinendrehzahl
Zur Verbesserung des Lastschlagverhaltens beim Schaltvorgang";
CM_ SG_ 896 MO3_Prio_Dz "Motor Wunschdrehzahl Priorität
Wunschdrehzahl in Byte 7 ist als Zwang oder als Wunsch an das Getriebe zu interpretieren(Info: war Übertemperaturschutz teilw. noch im PQ25,T5GP)";
CM_ SG_ 896 MO3_Sta_Pedal "Fahrpedalwert ungenau (Motor 3)
Ersatzwert in Byte 3, Leergas- oder Kickdown-Info können betroffen sein";
CM_ SG_ 896 MO3_res_02 " 
(Info: war Motor-Wunschdrehzahl Priorität teilw. noch im PQ25,T5GP)";
CM_ SG_ 896 MO3_Winterprg "Winterfahrprogramm aktiv
Bei aktivem Winterfahrprogramm wird die Ausgabe des  Pedalkennfeldes im Motor modifiziert (PQ35)";
CM_ SG_ 896 MO3_Sign_FPG "Vorzeichen Fahrpedalgradient
Kennzeichnet das Vorzeichen des Signals ´Fahrpedalgradient (Motor 3 Byte 8 Bit 7...0). Die Ausgabe erfolgt nur bei parallel statisch mit gesendetem Signal: ´Steuerungsbit Fahrpedalgradient´ (Motor 3 Byte 1 Bit 5) (AU716, Audi TTNF, T5, D3, C6)";
CM_ SG_ 896 MO3_Aussentemp "Ansauglufttemperatur
In Fahrzeugen ohne Außentemperatur vom Kombi kann aus der Ansauglufttemperatur auf die Außentemperatur geschlossen werden. Beim SDI ist das mit einer gewissen Genauigkeit gegeben. Genutzt wird es vom ASG.";
CM_ SG_ 896 MO3_Sta_FPG "Steuerungsbit Fahrpedalgradient
Nur wenn das Bit ´Steuerungsbit Fahrpedalgradient´ gesetzt ist werden die beide Signale: ´Fahrpedalgradient´ (Motor 3 Byte 8 Bit 7..0) und ´Vorzeichen Fahrpedalgradient´ (Motor 3 Byte 3 Bit 6) vom ESP-Steuergerät zur Vorbefüllung der Radbremsen zur Verkürzung der Anhalteweges genutzt. (AU716, Audi TTNF, T5, C6, D3)Wenn das Bit nicht gesetzt ist, wird in Byte 8 weiterhin das Signal Drosselklappenpoti übertragen.(Info: war Drosselklappenwinkel ungenau)";
CM_ SG_ 896 MO3_Vorgluehen "Vorglühmeldung
bei kaltem Motor muß der Motor gestartet werden oder der nächste Start darf nur nach Vorglühung erfolgen";
CM_ SG_ 896 MO3_Sta_Temp "Fehlerstatus Ansauglufttemperatur
Ersatzwert oder Fehlerwert";
CM_ SG_ 896 MO3_Pedalwert "Fahrpedal-Rohsignal
Siehe Fahrpedalspezifikation";
CM_ SG_ 896 MO3_res_37 " 
(war reserviert für Quittung der Modus-Anforderung in Getriebe 2, Byte 7, Bit 6)";
CM_ SG_ 896 MO3_res_38 " 
(war kein E-Gas)";
CM_ SG_ 896 MO3_res_39 " 
(war kein Start-Stop)";
CM_ SG_ 896 MO3_FPGradient "Fahrpedalgradient
Das Motorsteuergerät besitzt 2 analoge Fahrpedalsignale. Diese werden alle 4ms abgetastet. Entsprechend der Steuergeräte spezifischen Zykluszeit (Otto-Motor-Steuergeräte: alle 10ms, Diesel-Motor-Steuergeräte: alle 20ms), dann die einzelnen Gradienten berechnet und der kleinste Fahrpedalgradient des aktuellen Führungs- Fahrpedals ausgegeben. Zuvor erfolgt noch eine Entjitterung des Fahrpedalsignal um Bitschwankungen des A/D-Wandler heraus zu filtern. Bei einem Fehler in einem der beiden F";
CM_ SG_ 896 MO3_Vorz_RadWu "Vorzeichen Rad-Wunschmoment
Vorzeichen-Bit Rad-Wunschmoment";
CM_ SG_ 896 MO3_WunschDz "Motor Wunschdrehzahl
wenn das Bit 'Motor-Wunschdrehzahl Priorität' (Byte 1, Bit 1) gesetzt ist, wird hier vom Motor-SG eine wegen Übertemperaturschutz oder wegen Motor internen Fehlern bedingte Maximal-Motordrehzahl ausgegeben, die das Getriebe-SG durch Rückschaltungen nicht überschreiten darf;wenn das Bit nicht gesetzt ist, wird hier eine aus Emissionsgründen nicht zu überschreitende maximale Motordrehzahl ausgegeben;ansonsten wird der Init-Wert ausgegeben";
CM_ SG_ 896 MO3_Rad_Wu_Mo "Rad-Wunschmoment
Low Byte 4; High Nibbel in Byte 5; der Wertebereich geht damit von 0 bis 4094 x 0,39 Prozent MDI (Byte 4 entspricht in der Darstellung den anderen Motormomenten, Nibbel in Byte 5 ist die Erweiterung) ";
CM_ SG_ 896 MO3_DKW "Drosselklappenpoti
Rohsignal des Drosselklappenpotis bei Otto Motor Steuergeräten mit E-GasEntfall zukünftig geplantDie Ausgabe erfolgt nur wenn Signal: ´Steuerungsbit Fahrpedalgradient´ (Motor 3, Byte 1, Bit 5) auf 0";
CM_ SG_ 896 MO3_Dz_Beeinfl "Motordrehzahlbeeinflussung
Mit diesem Faktor kann das Motorsteuergerät die vom VL30-Getriebe einzustellende Sollmotordrehzahl beeinflussen. Im VL30-Steuergerät ist ein verbrauchsoptimales Kennfeld und ein abgasoptimiertes Kennfeld abgelegt. Mit dem Wert von 0-100% wird zwischen diesen beiden Kennfeldern interpoliert. Dabei bedeutet 0% verbrauchoptimale Motordrehzahl. Solange ein Wert > 0% übertragen wird, ist die Fahrerbewertung (DSP) deaktiviert. ";
CM_ SG_ 1420 M10_Status_StSt "Systemstatus Start Stopp
Systemstatus des Start-Stopp-Koordinators0 = System in diesem Kl15 Zyklus nicht verfügbar (Sicherheitsabschaltung, Sensorfehler erkannt, Funktion nicht implementiert)1 = Abschaltung über Hauptschalter2 = System aktiv, Motorlauf nicht notwendig (Freigaben aller Komponenten liegen vor)3 = System aktiv, Motorlauf notwendig bzw. Wiederstart erforderlich (mindestens eine Komponenten-freigabe fehlt)";
CM_ SG_ 1420 M10_Druck_err_gem "Rel. Saugrohrdruck errechnet/gemessen
0: mind. eine Modellrechnung wird zur Berechnung des relativen Saugrohrdrucks (Byte 3, Bit 5..0) herangezogen.1: Relativer Saugrohrdruck wird ausschließlich über Messgrößen bestimmt.";
CM_ SG_ 1420 M10_Anzeige "Anzeige Start/Stopp_Automatikstart
0 keine AnzeigeStart/Stopp: 1 Anzeige Motor im Stopp-Betrieb 2 Anzeige Start-Stopp    sicherheitsbedingt deaktiviert 3 Anzeige System fordert Wiederstart4..11 tbdAutomatikstart:12 Anzeige Motor startet13 Anzeige Kupplung betätigen14 Anzeige Wählhebel in P/N Position15 Anzeige Bremse treten";
CM_ SG_ 1420 M10_Schubabschaltung "Schubabschaltung
ESP plausibilisiert Unterdrucksensor nur bei aktiver Schubabschaltung";
CM_ SG_ 1420 M10_rel_Saugrohrdruck "Relativer Saugrohrdruck
Der Wert gibt an, um wieviel mbar der Saugrohrdruck unterhalb des Umgebungsdrucks liegt. Überdruck im Saugrohr wird nicht ausgegeben.0: Saugrohrdruck >= Umgebungsdruck";
CM_ SG_ 1420 M10_Fahrbereitschaft "Fahrbereitschaft
Signal steuert u.a. in der Lenkhilfe zusammen mit weiteren Informationen den Modewechsel in den ´Drivemode´";
CM_ SG_ 1420 M10_Hybrid "Hybrid
Anhand dieses Signals plausibilisiert die Lenkhilfe das Bit Fahrbereitschaft";
CM_ SG_ 1420 M10_Freigabe_Reku "Freigabe Rekuperation
Empfehlung des Motor-SG's zur Spannungsabsenkung/-anhebung für den Rekuperationsbetrieb (PQ25, PQ35/46, AU210, C6, AU716, Hybrid-Projekte)";
CM_ SG_ 1420 M10_VM_aktiv "V-Motor aktiv
für Kombiinstrument zur Steuerung der Anzeigen und Auswertung (z.B. Reichweite, DÖW usw.)";
CM_ SG_ 1420 M10_HYB_Bereitlampe "Lampe Hybrid-Bereitschaft
grüne Anzeige im Kombiinstrument zur Signalisierung der Bereitschaft des Hybridsystems";
CM_ SG_ 1420 M10_HYB_Warnlampe "Lampe Hybrid-Warnung
gelbe Anzeige im Kombiinstrument zur Signalisierung der Warnmeldung des Hybridsystems";
CM_ SG_ 1420 M10_HYB_Fehlerlampe "Lampe Hybrid-Fehler
rote Anzeige im Kombiinstrument zur Signalisierung der Sicherheitsmeldung des Hybridsystems";
CM_ SG_ 1420 M10_Fehler_HV_Netz "Fehler HV-Netz
Im HV-Bordnetz ist fehlerbedingt kein generatorischer Betrieb möglich. Das 12V-Bordnetz wird über den DC/DC-Wandler allein aus der Traktionsbatterie gespeist. Um diesen Zustand möglichst lange aufrechterhalten zu können, sollten Komfort-Verbraucher abgeschaltet werden. (Hybrid)";
CM_ SG_ 1420 M10_EKlKomLeiRed "E-Klimakompressor Leistungsbegrenzung
Anforderung an die Klimasteuerung, die Leistungsaufnahme des E-Kompressors bei schlechtem SOC und in bestimmten Fahrsituationen zu begrenzen.(Das bereits bestehende Signal ´Klimakompressor aus´ Motor5, Byte2, Bit5 als stets umzusetzende Anforderung bleibt unverändert bestehen.)0 keine Leistungsbegr. gewünscht1 Leistungsbegr. auf 75% der max. Leistung2 Leistungsbegr. auf 50% der max. Leistung3 Leistungsbegr. auf 25% der max. Leistung";
CM_ SG_ 1420 M10_EM_aktiv "E-Motor aktiv
für Kombiinstrument zur Steuerung der Anzeigen und Auswertung (z.B. Reichweite, DÖW usw.)";
CM_ SG_ 1420 M10_Klimadruck "Klimadruck
Drucksensor am Motor-SG (China Modell X/Y)";
CM_ SG_ 1420 M10_KompAusCode "Kompressor-Aus-Code
Abschaltbedingungen im Motor für den Klimakompressor (China Modell X/Y)";
CM_ SG_ 1420 M10_Akustik "Akustik
Anforderung einer Akustikwarnung im Kombi (durch Hybrid- oder Start/Stopp-Koordinator)0 = keine Akustik1 = Akustik 1 (Gong 1000 bei VW)2 = Akustik 2 (3xSummer2000 bei VW)3 = frei";
CM_ SG_ 1420 M10_ShiftLockLampe "Shift-Lock Lampe
Bei Automatikstart/Startersteuerung im MSG: In Automatik-Fahrzeugen ist Betätigen der Bremse Freigabebedingung für den Startwunsch. (ergänzend/alternativ zur Textanzeige)";
CM_ SG_ 1420 M10_Text_1_Hybrid "Text 1 Hybrid
Text 1 (ID_TXT_1024.1): Fehler Hybridsystem Werkstatt aufsuchen (Kategorie 1)";
CM_ SG_ 1420 M10_Text_2_Hybrid "Text 2 Hybrid
Text 2 (ID_TXT_1025.1): Fehler Hybridsystem Werkstatt aufsuchen (Kategorie 2)";
CM_ SG_ 1420 M10_Text_4_Hybrid "Text 4 Hybrid
Text 4 (ID_TXT_1025.3): Bordnetzunterspannung Bordbuch";
CM_ SG_ 1420 M10_Text_5_Hybrid "Text 5 Hybrid
Text 5 (ID_TXT_1025.4): Anlasser länger betätigen!";
CM_ SG_ 1420 M10_Text_6_Hybrid "Text 6 Hybrid
 ";
CM_ SG_ 1420 M10_Text_7_Hybrid "Text 7 Hybrid
 ";
CM_ SG_ 1420 M10_Text_8_Hybrid "Text 8 Hybrid
 ";
CM_ SG_ 1420 M10_Text_3_Hybrid "Text 3 Hybrid
Text 3 (ID_TXT_1025.2): Warten. HV-Batterie wird geladen. Bordbuch";
CM_ SG_ 1420 M10_StSt_Lampe "Start Stopp Lampe
Vorhalt Start Stopp Lampe für Low-Line-Kombis";
CM_ SG_ 1420 M10_BattFanSpd "M10_VentilationReq
Relativwert der Batterielüfter-Ansteuerung bezogen auf Maximalwert. Signal wird vom MSG von Hybrid-CAN auf den A-CAN gespiegelt(mBMS_HYB_3, Byte 7, Bit 7..4 aus Hybrid-CAN DF > V1.5)";
CM_ SG_ 1420 M10_BMSInfo_gue "BMS Hybrid Info gültig
Die vom MSG aus dem Hybrid-CAN gespiegelten Daten ´M10_VentilationReq und ´M10_BattFanSpd sind gültig (Botschaften vom Hybrid-CAN vor weniger als 1000ms empfangen).";
CM_ SG_ 1420 M10_VentilationReq "M10_VentilationReq
BMS fordert bei Climatronic die Öffnung der Umluftklappe an. Signal wird vom MSG von Hybrid-CAN auf den A-CAN gespiegelt (mBMS_HYB_6, Byte 8, Bit 1 aus Hybrid-CAN DF > V1.5)";
CM_ SG_ 1420 M10_res_06 " 
 ";
CM_ SG_ 1420 M10_MotorStopp "Motor Stopp
Motor-Stopp durch Start-Stopp-Koordinator. Das Signal wird nur bei einem Motorstopp durch den Start-Stopp-Koordinator gesetzt. Bei Abwürgen des Motors oder nach Abstellen des Motors über KL15 (Nachlauf) bleibt das Signal inaktiv.Stopp-Modus aktiv wird erst nach Wiederstartende zurückgenommen, wenn der Motor stabil läuft und Moment abgefordert werden kann.";
CM_ SG_ 1420 M10_Wiederstart "Wiederstart
Motorwiederstart durch Start-Stopp-Koordinator. Wiederstart aktiv wird vom Koordinator gesetzt sobald der Wiederstart angetriggert wird und bleibt bis zum Startende gesetzt. (bleibt beim Erststart 0)";
CM_ SG_ 1420 M10_Anf_Kl75 "Anforderung KL75
Anforderung an das BSG/BCM bei Konzepten mit Startersteuerung durch das MSG: Beim Erststart fordert das MSG mit diesem Signal das Ausschalten der KL75-Verbraucher an. (Bei einem Wiederstart innerhalb der Start-Stopp-Funktionalität bleib das Signal gesetzt.)";
CM_ SG_ 1420 M10_Start_D_erl "Starten in Fahrstufe erlaubt
Erweiterte Startfreigabe für einen Wiederstart (bei Start/Stopp)";
CM_ SG_ 1420 M10_Blinken "Blink-Bit Start Stopp Lampe
Vorhalt Blink-Bit Start Stopp Lampe für Low-Line-Kombis";
CM_ SG_ 1420 M10_Start_D_gueltig "Gültigkeit der Startfreigabebedingungen
Das Signal Starten in Fahrstufe erlaubt (Byte 1, Bit 5) führt im Getriebe nur dann zu einer Änderung der Startfreigabe (P/N-Leitung), wenn es hier gültig erklärt wird.(Verhinderung von Startabbrüchen durch Initwerte in Byte1, Bit 5 nach Unterspannungsreset)";
CM_ SG_ 1420 M10_UDruckDyn "Saugrohrunterdruckdynamik
0 = Der Saugrohrunterdruckwert überstieg mind. einmal mehr als 50mbar (in Richtung Vakuum), bezogen auf den höchsten Saugrohrunterdruckwert aus der aktuellen und letzen CAN-Ausgabe (siehe mMotor_10, Byte 3, Bit 5..0).1 = Der Saugrohrunterdruckwert war immer weniger als 50mbar angestiegen (in Richtung Vakuum), bezogen auf den höchsten Saugrohrunterdruckwert aus der aktuellen und letzen CAN-Ausgabe (siehe mMotor_10, Byte 3, Bit 5..0).";
CM_ SG_ 513 Motor_TP_Er "TP 2.0 Eroeffnungskanal
 ";
BA_DEF_ BO_  "VAGTP20_API" HEX 0 255;
BA_DEF_ BO_  "VAGTP20_StatConnection" ENUM  "No","Yes";
BA_DEF_ BO_  "VAGTP20_DynConnection" ENUM  "No","Yes";
BA_DEF_ BO_  "VAGTP20_DynSetup" ENUM  "No","Yes";
BA_DEF_ BO_  "NmMessage" ENUM  "No","Yes";
BA_DEF_ BO_  "NmhMessage" ENUM  "No","Yes";
BA_DEF_ BO_  "GenMsgCycleTime" INT 0 65535;
BA_DEF_ BO_  "GenMsgSendType" ENUM  "cyclicX","spontanX","cyclicIfActiveX","spontanWithDelay","cyclicAndSpontanX","cyclicAndSpontanWithDelay","spontanWithRepitition","cyclicIfActiveAndSpontanWD","NoMsgSendType","cyclicWithRepeatOnDemand";
BA_DEF_ BO_  "GenMsgCycleTimeFast" INT 0 65535;
BA_DEF_ BO_  "GenMsgNrOfRepetition" INT 0 255;
BA_DEF_ BO_  "GenMsgDelayTime" INT 0 100000;
BA_DEF_ BO_  "GenMsgILSupport" ENUM  "No","Yes";
BA_DEF_ BO_  "GenMsgTimeoutTime" INT 0 100000;
BA_DEF_ BO_  "GenMsgAutoGenDsp" ENUM  "No","Yes";
BA_DEF_ BO_  "GenMsgAutoGenSnd" ENUM  "No","Yes";
BA_DEF_ BO_  "DiagRequest" ENUM  "No","Yes";
BA_DEF_ BO_  "DiagResponse" ENUM  "No","Yes";
BA_DEF_ BO_  "DiagState" ENUM  "No","Yes";
BA_DEF_ SG_  "GenSigSendType" ENUM  "Cyclic","OnWrite","OnWriteWithRepetition","OnChange","OnChangeWithRepetition","IfActive","IfActiveWithRepetition","NoSigSendType";
BA_DEF_ SG_  "GenSigStartValue" INT 0 4294967295;
BA_DEF_ SG_  "GenSigInactiveValue" INT 0 2147483647;
BA_DEF_ SG_  "GenSigAutoGenDsp" ENUM  "No","Yes";
BA_DEF_ SG_  "GenSigAutoGenSnd" ENUM  "No","Yes";
BA_DEF_ SG_  "GenSigEnvVarType" STRING ;
BA_DEF_ SG_  "GenSigFuncType" ENUM  "NoFunction","MsgCounter","CRC-8","XOR","XOR-2","DatedBit","SW-Kl15","CHK","Constant","Protokoll";
BA_DEF_ SG_  "NWM-WakeUpAllowed" ENUM  "No","Yes";
BA_DEF_ SG_  "INIT" STRING ;
BA_DEF_ SG_  "GenSigTimeoutMsg_Airbag" HEX 0 2047;
BA_DEF_ SG_  "GenSigTimeoutTime_Airbag" INT 0 65535;
BA_DEF_ SG_  "GenSigTimeoutMsg_Allrad" HEX 0 2047;
BA_DEF_ SG_  "GenSigTimeoutTime_Allrad" INT 0 65535;
BA_DEF_ SG_  "GenSigTimeoutMsg_Lenkhilfe_ZF_2" HEX 0 2047;
BA_DEF_ SG_  "GenSigTimeoutTime_Lenkhilfe_ZF_2" INT 0 65535;
BA_DEF_ SG_  "GenSigTimeoutMsg_Teves_MK60_ESP" HEX 0 2047;
BA_DEF_ SG_  "GenSigTimeoutTime_Teves_MK60_ESP" INT 0 65535;
BA_DEF_ SG_  "GenSigTimeoutMsg_LWS" HEX 0 2047;
BA_DEF_ SG_  "GenSigTimeoutTime_LWS" INT 0 65535;
BA_DEF_ SG_  "GenSigTimeoutMsg_LWR" HEX 0 2047;
BA_DEF_ SG_  "GenSigTimeoutTime_LWR" INT 0 65535;
BA_DEF_ SG_  "GenSigTimeoutMsg_Teves_MK70_MAB" HEX 0 2047;
BA_DEF_ SG_  "GenSigTimeoutTime_Teves_MK70_MAB" INT 0 65535;
BA_DEF_ SG_  "GenSigTimeoutMsg_Waehlhebel" HEX 0 2047;
BA_DEF_ SG_  "GenSigTimeoutTime_Waehlhebel" INT 0 65535;
BA_DEF_ SG_  "GenSigTimeoutMsg_EPB" HEX 0 2047;
BA_DEF_ SG_  "GenSigTimeoutTime_EPB" INT 0 65535;
BA_DEF_ SG_  "GenSigTimeoutMsg_TRW_ESP" HEX 0 2047;
BA_DEF_ SG_  "GenSigTimeoutTime_TRW_ESP" INT 0 65535;
BA_DEF_ SG_  "GenSigTimeoutMsg_ACC_Radar" HEX 0 2047;
BA_DEF_ SG_  "GenSigTimeoutTime_ACC_Radar" INT 0 65535;
BA_DEF_ SG_  "GenSigTimeoutMsg_AFS" HEX 0 2047;
BA_DEF_ SG_  "GenSigTimeoutTime_AFS" INT 0 65535;
BA_DEF_ SG_  "GenSigTimeoutMsg_Magne_Ride" HEX 0 2047;
BA_DEF_ SG_  "GenSigTimeoutTime_Magne_Ride" INT 0 65535;
BA_DEF_ SG_  "GenSigTimeoutMsg_RKA_Plus" HEX 0 2047;
BA_DEF_ SG_  "GenSigTimeoutTime_RKA_Plus" INT 0 65535;
BA_DEF_ SG_  "GenSigTimeoutMsg_Selespeed" HEX 0 2047;
BA_DEF_ SG_  "GenSigTimeoutTime_Selespeed" INT 0 65535;
BA_DEF_ SG_  "GenSigTimeoutMsg_Waehlhebel_Sel" HEX 0 2047;
BA_DEF_ SG_  "GenSigTimeoutTime_Waehlhebel_Sel" INT 0 65535;
BA_DEF_ SG_  "GenSigTimeoutMsg_PDC_PLA" HEX 0 2047;
BA_DEF_ SG_  "GenSigTimeoutTime_PDC_PLA" INT 0 65535;
BA_DEF_ SG_  "GenSigTimeoutMsg_Lenkhilfe_APA" HEX 0 2047;
BA_DEF_ SG_  "GenSigTimeoutTime_Lenkhilfe_APA" INT 0 65535;
BA_DEF_ SG_  "GenSigTimeoutMsg_VAQ" HEX 0 2047;
BA_DEF_ SG_  "GenSigTimeoutTime_VAQ" INT 0 65535;
BA_DEF_ SG_  "GenSigTimeoutMsg_Daempfer" HEX 0 2047;
BA_DEF_ SG_  "GenSigTimeoutTime_Daempfer" INT 0 65535;
BA_DEF_ SG_  "GenSigTimeoutMsg_Hybrid_BMS" HEX 0 2047;
BA_DEF_ SG_  "GenSigTimeoutTime_Hybrid_BMS" INT 0 65535;
BA_DEF_ SG_  "GenSigTimeoutMsg_Hybrid_PWR" HEX 0 2047;
BA_DEF_ SG_  "GenSigTimeoutTime_Hybrid_PWR" INT 0 65535;
BA_DEF_ SG_  "GenSigTimeoutMsg_Hybrid_DQ200" HEX 0 2047;
BA_DEF_ SG_  "GenSigTimeoutTime_Hybrid_DQ200" INT 0 65535;
BA_DEF_ SG_  "GenSigTimeoutMsg_EKlimakomp" HEX 0 2047;
BA_DEF_ SG_  "GenSigTimeoutTime_EKlimakomp" INT 0 65535;
BA_DEF_ SG_  "GenSigTimeoutMsg_SWA" HEX 0 2047;
BA_DEF_ SG_  "GenSigTimeoutTime_SWA" INT 0 65535;
BA_DEF_ SG_  "GenSigTimeoutMsg_HCA" HEX 0 2047;
BA_DEF_ SG_  "GenSigTimeoutTime_HCA" INT 0 65535;
BA_DEF_ SG_  "GenSigTimeoutMsg_ACC_Lidar" HEX 0 2047;
BA_DEF_ SG_  "GenSigTimeoutTime_ACC_Lidar" INT 0 65535;
BA_DEF_ SG_  "GenSigTimeoutMsg_Lenkhilfe_ZF_3" HEX 0 2047;
BA_DEF_ SG_  "GenSigTimeoutTime_Lenkhilfe_ZF_3" INT 0 65535;
BA_DEF_ SG_  "GenSigTimeoutMsg_FLA" HEX 0 2047;
BA_DEF_ SG_  "GenSigTimeoutTime_FLA" INT 0 65535;
BA_DEF_ SG_  "GenSigTimeoutMsg_AG6" HEX 0 2047;
BA_DEF_ SG_  "GenSigTimeoutTime_AG6" INT 0 65535;
BA_DEF_ SG_  "GenSigTimeoutMsg_DQ" HEX 0 2047;
BA_DEF_ SG_  "GenSigTimeoutTime_DQ" INT 0 65535;
BA_DEF_ SG_  "GenSigTimeoutMsg_Hybrid_MSG" HEX 0 2047;
BA_DEF_ SG_  "GenSigTimeoutTime_Hybrid_MSG" INT 0 65535;
BA_DEF_ SG_  "GenSigTimeoutMsg_Diesel" HEX 0 2047;
BA_DEF_ SG_  "GenSigTimeoutTime_Diesel" INT 0 65535;
BA_DEF_ SG_  "GenSigTimeoutMsg_Otto" HEX 0 2047;
BA_DEF_ SG_  "GenSigTimeoutTime_Otto" INT 0 65535;
BA_DEF_ SG_  "GenSigTimeoutMsg_Gateway_PQ35_A" HEX 0 2047;
BA_DEF_ SG_  "GenSigTimeoutTime_Gateway_PQ35_A" INT 0 65535;
BA_DEF_ SG_  "GenSigTimeoutMsg_Gateway_PQ46_A" HEX 0 2047;
BA_DEF_ SG_  "GenSigTimeoutTime_Gateway_PQ46_A" INT 0 65535;
BA_DEF_DEF_  "VAGTP20_API" 0;
BA_DEF_DEF_  "VAGTP20_StatConnection" "No";
BA_DEF_DEF_  "VAGTP20_DynConnection" "No";
BA_DEF_DEF_  "VAGTP20_DynSetup" "No";
BA_DEF_DEF_  "NmMessage" "No";
BA_DEF_DEF_  "NmhMessage" "No";
BA_DEF_DEF_  "GenMsgCycleTime" 0;
BA_DEF_DEF_  "GenMsgSendType" "NoMsgSendType";
BA_DEF_DEF_  "GenMsgCycleTimeFast" 0;
BA_DEF_DEF_  "GenMsgNrOfRepetition" 0;
BA_DEF_DEF_  "GenMsgDelayTime" 0;
BA_DEF_DEF_  "GenMsgILSupport" "No";
BA_DEF_DEF_  "GenMsgTimeoutTime" 0;
BA_DEF_DEF_  "GenMsgAutoGenDsp" "Yes";
BA_DEF_DEF_  "GenMsgAutoGenSnd" "Yes";
BA_DEF_DEF_  "DiagRequest" "No";
BA_DEF_DEF_  "DiagResponse" "No";
BA_DEF_DEF_  "DiagState" "No";
BA_DEF_DEF_  "GenSigSendType" "NoSigSendType";
BA_DEF_DEF_  "GenSigStartValue" 0;
BA_DEF_DEF_  "GenSigInactiveValue" 0;
BA_DEF_DEF_  "GenSigAutoGenDsp" "Yes";
BA_DEF_DEF_  "GenSigAutoGenSnd" "Yes";
BA_DEF_DEF_  "GenSigEnvVarType" "Undef";
BA_DEF_DEF_  "GenSigFuncType" "NoFunction";
BA_DEF_DEF_  "NWM-WakeUpAllowed" "No";
BA_DEF_DEF_  "INIT" "";
BA_DEF_DEF_  "GenSigTimeoutMsg_Airbag" 0;
BA_DEF_DEF_  "GenSigTimeoutTime_Airbag" 0;
BA_DEF_DEF_  "GenSigTimeoutMsg_Allrad" 0;
BA_DEF_DEF_  "GenSigTimeoutTime_Allrad" 0;
BA_DEF_DEF_  "GenSigTimeoutMsg_Lenkhilfe_ZF_2" 0;
BA_DEF_DEF_  "GenSigTimeoutTime_Lenkhilfe_ZF_2" 0;
BA_DEF_DEF_  "GenSigTimeoutMsg_Teves_MK60_ESP" 0;
BA_DEF_DEF_  "GenSigTimeoutTime_Teves_MK60_ESP" 0;
BA_DEF_DEF_  "GenSigTimeoutMsg_LWS" 0;
BA_DEF_DEF_  "GenSigTimeoutTime_LWS" 0;
BA_DEF_DEF_  "GenSigTimeoutMsg_LWR" 0;
BA_DEF_DEF_  "GenSigTimeoutTime_LWR" 0;
BA_DEF_DEF_  "GenSigTimeoutMsg_Teves_MK70_MAB" 0;
BA_DEF_DEF_  "GenSigTimeoutTime_Teves_MK70_MAB" 0;
BA_DEF_DEF_  "GenSigTimeoutMsg_Waehlhebel" 0;
BA_DEF_DEF_  "GenSigTimeoutTime_Waehlhebel" 0;
BA_DEF_DEF_  "GenSigTimeoutMsg_EPB" 0;
BA_DEF_DEF_  "GenSigTimeoutTime_EPB" 0;
BA_DEF_DEF_  "GenSigTimeoutMsg_TRW_ESP" 0;
BA_DEF_DEF_  "GenSigTimeoutTime_TRW_ESP" 0;
BA_DEF_DEF_  "GenSigTimeoutMsg_ACC_Radar" 0;
BA_DEF_DEF_  "GenSigTimeoutTime_ACC_Radar" 0;
BA_DEF_DEF_  "GenSigTimeoutMsg_AFS" 0;
BA_DEF_DEF_  "GenSigTimeoutTime_AFS" 0;
BA_DEF_DEF_  "GenSigTimeoutMsg_Magne_Ride" 0;
BA_DEF_DEF_  "GenSigTimeoutTime_Magne_Ride" 0;
BA_DEF_DEF_  "GenSigTimeoutMsg_RKA_Plus" 0;
BA_DEF_DEF_  "GenSigTimeoutTime_RKA_Plus" 0;
BA_DEF_DEF_  "GenSigTimeoutMsg_Selespeed" 0;
BA_DEF_DEF_  "GenSigTimeoutTime_Selespeed" 0;
BA_DEF_DEF_  "GenSigTimeoutMsg_Waehlhebel_Sel" 0;
BA_DEF_DEF_  "GenSigTimeoutTime_Waehlhebel_Sel" 0;
BA_DEF_DEF_  "GenSigTimeoutMsg_PDC_PLA" 0;
BA_DEF_DEF_  "GenSigTimeoutTime_PDC_PLA" 0;
BA_DEF_DEF_  "GenSigTimeoutMsg_Lenkhilfe_APA" 0;
BA_DEF_DEF_  "GenSigTimeoutTime_Lenkhilfe_APA" 0;
BA_DEF_DEF_  "GenSigTimeoutMsg_VAQ" 0;
BA_DEF_DEF_  "GenSigTimeoutTime_VAQ" 0;
BA_DEF_DEF_  "GenSigTimeoutMsg_Daempfer" 0;
BA_DEF_DEF_  "GenSigTimeoutTime_Daempfer" 0;
BA_DEF_DEF_  "GenSigTimeoutMsg_Hybrid_BMS" 0;
BA_DEF_DEF_  "GenSigTimeoutTime_Hybrid_BMS" 0;
BA_DEF_DEF_  "GenSigTimeoutMsg_Hybrid_PWR" 0;
BA_DEF_DEF_  "GenSigTimeoutTime_Hybrid_PWR" 0;
BA_DEF_DEF_  "GenSigTimeoutMsg_Hybrid_DQ200" 0;
BA_DEF_DEF_  "GenSigTimeoutTime_Hybrid_DQ200" 0;
BA_DEF_DEF_  "GenSigTimeoutMsg_EKlimakomp" 0;
BA_DEF_DEF_  "GenSigTimeoutTime_EKlimakomp" 0;
BA_DEF_DEF_  "GenSigTimeoutMsg_SWA" 0;
BA_DEF_DEF_  "GenSigTimeoutTime_SWA" 0;
BA_DEF_DEF_  "GenSigTimeoutMsg_HCA" 0;
BA_DEF_DEF_  "GenSigTimeoutTime_HCA" 0;
BA_DEF_DEF_  "GenSigTimeoutMsg_ACC_Lidar" 0;
BA_DEF_DEF_  "GenSigTimeoutTime_ACC_Lidar" 0;
BA_DEF_DEF_  "GenSigTimeoutMsg_Lenkhilfe_ZF_3" 0;
BA_DEF_DEF_  "GenSigTimeoutTime_Lenkhilfe_ZF_3" 0;
BA_DEF_DEF_  "GenSigTimeoutMsg_FLA" 0;
BA_DEF_DEF_  "GenSigTimeoutTime_FLA" 0;
BA_DEF_DEF_  "GenSigTimeoutMsg_AG6" 0;
BA_DEF_DEF_  "GenSigTimeoutTime_AG6" 0;
BA_DEF_DEF_  "GenSigTimeoutMsg_DQ" 0;
BA_DEF_DEF_  "GenSigTimeoutTime_DQ" 0;
BA_DEF_DEF_  "GenSigTimeoutMsg_Hybrid_MSG" 0;
BA_DEF_DEF_  "GenSigTimeoutTime_Hybrid_MSG" 0;
BA_DEF_DEF_  "GenSigTimeoutMsg_Diesel" 0;
BA_DEF_DEF_  "GenSigTimeoutTime_Diesel" 0;
BA_DEF_DEF_  "GenSigTimeoutMsg_Otto" 0;
BA_DEF_DEF_  "GenSigTimeoutTime_Otto" 0;
BA_DEF_DEF_  "GenSigTimeoutMsg_Gateway_PQ35_A" 0;
BA_DEF_DEF_  "GenSigTimeoutTime_Gateway_PQ35_A" 0;
BA_DEF_DEF_  "GenSigTimeoutMsg_Gateway_PQ46_A" 0;
BA_DEF_DEF_  "GenSigTimeoutTime_Gateway_PQ46_A" 0;
BA_ "GenMsgTimeoutTime" BO_ 1104 500;
BA_ "GenMsgSendType" BO_ 1104 0;
BA_ "GenMsgCycleTime" BO_ 1104 10;
BA_ "GenMsgTimeoutTime" BO_ 1102 500;
BA_ "GenMsgSendType" BO_ 1102 0;
BA_ "GenMsgCycleTime" BO_ 1102 10;
BA_ "GenMsgTimeoutTime" BO_ 1494 1000;
BA_ "GenMsgSendType" BO_ 1494 0;
BA_ "GenMsgCycleTime" BO_ 1494 100;
BA_ "GenMsgTimeoutTime" BO_ 980 500;
BA_ "GenMsgSendType" BO_ 980 0;
BA_ "GenMsgCycleTime" BO_ 980 20;
BA_ "GenMsgSendType" BO_ 541 1;
BA_ "VAGTP20_DynSetup" BO_ 541 1;
BA_ "GenMsgDelayTime" BO_ 1355 100;
BA_ "GenMsgCycleTimeFast" BO_ 1355 100;
BA_ "GenMsgSendType" BO_ 1355 2;
BA_ "GenMsgTimeoutTime" BO_ 1175 1000;
BA_ "GenMsgDelayTime" BO_ 1175 50;
BA_ "GenMsgSendType" BO_ 1175 5;
BA_ "GenMsgCycleTime" BO_ 1175 100;
BA_ "GenMsgSendType" BO_ 1754 1;
BA_ "GenMsgDelayTime" BO_ 1528 50;
BA_ "GenMsgCycleTimeFast" BO_ 1528 50;
BA_ "GenMsgSendType" BO_ 1528 7;
BA_ "DiagResponse" BO_ 1908 1;
BA_ "GenMsgSendType" BO_ 1908 1;
BA_ "GenMsgTimeoutTime" BO_ 714 500;
BA_ "GenMsgSendType" BO_ 714 0;
BA_ "GenMsgCycleTime" BO_ 714 10;
BA_ "GenMsgSendType" BO_ 536 1;
BA_ "VAGTP20_DynSetup" BO_ 536 1;
BA_ "GenMsgTimeoutTime" BO_ 1404 5000;
BA_ "GenMsgSendType" BO_ 1404 0;
BA_ "GenMsgCycleTime" BO_ 1404 1000;
BA_ "GenMsgTimeoutTime" BO_ 1406 5000;
BA_ "GenMsgSendType" BO_ 1406 0;
BA_ "GenMsgCycleTime" BO_ 1406 1000;
BA_ "GenMsgTimeoutTime" BO_ 1352 500;
BA_ "GenMsgSendType" BO_ 1352 0;
BA_ "GenMsgCycleTime" BO_ 1352 10;
BA_ "GenMsgTimeoutTime" BO_ 1106 500;
BA_ "GenMsgSendType" BO_ 1106 0;
BA_ "GenMsgCycleTime" BO_ 1106 10;
BA_ "DiagResponse" BO_ 2025 1;
BA_ "GenMsgSendType" BO_ 2025 1;
BA_ "GenMsgTimeoutTime" BO_ 1090 500;
BA_ "GenMsgSendType" BO_ 1090 0;
BA_ "GenMsgCycleTime" BO_ 1090 10;
BA_ "GenMsgTimeoutTime" BO_ 1526 5000;
BA_ "GenMsgSendType" BO_ 1526 0;
BA_ "GenMsgCycleTime" BO_ 1526 500;
BA_ "DiagResponse" BO_ 1923 1;
BA_ "GenMsgSendType" BO_ 1923 1;
BA_ "GenMsgSendType" BO_ 1650 1;
BA_ "GenMsgTimeoutTime" BO_ 954 500;
BA_ "GenMsgSendType" BO_ 954 0;
BA_ "GenMsgCycleTime" BO_ 954 50;
BA_ "GenMsgSendType" BO_ 540 1;
BA_ "VAGTP20_DynSetup" BO_ 540 1;
BA_ "GenMsgSendType" BO_ 1651 1;
BA_ "GenMsgTimeoutTime" BO_ 1470 500;
BA_ "GenMsgSendType" BO_ 1470 0;
BA_ "GenMsgCycleTime" BO_ 1470 50;
BA_ "GenMsgSendType" BO_ 538 1;
BA_ "VAGTP20_DynSetup" BO_ 538 1;
BA_ "GenMsgTimeoutTime" BO_ 210 500;
BA_ "GenMsgSendType" BO_ 210 0;
BA_ "GenMsgCycleTime" BO_ 210 20;
BA_ "DiagResponse" BO_ 1985 1;
BA_ "GenMsgSendType" BO_ 1985 1;
BA_ "DiagResponse" BO_ 1916 1;
BA_ "GenMsgSendType" BO_ 1916 1;
BA_ "GenMsgSendType" BO_ 534 1;
BA_ "VAGTP20_DynSetup" BO_ 534 1;
BA_ "GenMsgTimeoutTime" BO_ 1626 5000;
BA_ "GenMsgDelayTime" BO_ 1626 200;
BA_ "GenMsgSendType" BO_ 1626 5;
BA_ "GenMsgCycleTime" BO_ 1626 1000;
BA_ "GenMsgTimeoutTime" BO_ 1100 500;
BA_ "GenMsgSendType" BO_ 1100 0;
BA_ "GenMsgCycleTime" BO_ 1100 20;
BA_ "GenMsgTimeoutTime" BO_ 896 500;
BA_ "GenMsgSendType" BO_ 896 0;
BA_ "GenMsgCycleTime" BO_ 896 10;
BA_ "GenMsgTimeoutTime" BO_ 1420 1000;
BA_ "GenMsgDelayTime" BO_ 1420 10;
BA_ "GenMsgSendType" BO_ 1420 5;
BA_ "GenMsgCycleTime" BO_ 1420 100;
BA_ "GenMsgSendType" BO_ 513 1;
BA_ "VAGTP20_DynSetup" BO_ 513 1;
BA_ "GenSigTimeoutTime_Otto" SG_ 1104 GE8_Checksumme 500;
BA_ "GenSigTimeoutMsg_Otto" SG_ 1104 GE8_Checksumme 1104;
BA_ "GenSigSendType" SG_ 1104 GE8_Checksumme 0;
BA_ "INIT" SG_ 1104 GE8_Checksumme "CHK";
BA_ "GenSigTimeoutTime_Otto" SG_ 1104 GE8_Hydr_Pumpe 500;
BA_ "GenSigTimeoutMsg_Otto" SG_ 1104 GE8_Hydr_Pumpe 1104;
BA_ "GenSigSendType" SG_ 1104 GE8_Hydr_Pumpe 0;
BA_ "GenSigTimeoutTime_Otto" SG_ 1104 GE8_Motor_aus 500;
BA_ "GenSigTimeoutMsg_Otto" SG_ 1104 GE8_Motor_aus 1104;
BA_ "GenSigSendType" SG_ 1104 GE8_Motor_aus 0;
BA_ "GenSigTimeoutTime_Otto" SG_ 1104 GE8_Anfahrfkt 500;
BA_ "GenSigTimeoutMsg_Otto" SG_ 1104 GE8_Anfahrfkt 1104;
BA_ "GenSigSendType" SG_ 1104 GE8_Anfahrfkt 0;
BA_ "GenSigTimeoutTime_Otto" SG_ 1104 GE8_SollDZ 500;
BA_ "GenSigTimeoutMsg_Otto" SG_ 1104 GE8_SollDZ 1104;
BA_ "GenSigSendType" SG_ 1104 GE8_SollDZ 0;
BA_ "GenSigTimeoutTime_Otto" SG_ 1104 GE8_VorsteuerMom 500;
BA_ "GenSigTimeoutMsg_Otto" SG_ 1104 GE8_VorsteuerMom 1104;
BA_ "GenSigSendType" SG_ 1104 GE8_VorsteuerMom 0;
BA_ "GenSigTimeoutTime_Otto" SG_ 1104 GE8_KuppMom 500;
BA_ "GenSigTimeoutMsg_Otto" SG_ 1104 GE8_KuppMom 1104;
BA_ "GenSigSendType" SG_ 1104 GE8_KuppMom 0;
BA_ "GenSigTimeoutTime_Otto" SG_ 1104 GE8_Zaehler 500;
BA_ "GenSigTimeoutMsg_Otto" SG_ 1104 GE8_Zaehler 1104;
BA_ "GenSigSendType" SG_ 1104 GE8_Zaehler 0;
BA_ "GenSigSendType" SG_ 1104 GE8_res_15 0;
BA_ "GenSigSendType" SG_ 1104 GE8_res_46 0;
BA_ "GenSigSendType" SG_ 1104 GE8_res_47 0;
BA_ "GenSigSendType" SG_ 1104 GE8_res_48 0;
BA_ "GenSigSendType" SG_ 1104 GE8_res_49 0;
BA_ "GenSigSendType" SG_ 1104 GE8_res_50 0;
BA_ "GenSigSendType" SG_ 1104 GE8_res_52 0;
BA_ "GenSigSendType" SG_ 1104 GE8_res_53 0;
BA_ "GenSigSendType" SG_ 1104 GE8_res_54 0;
BA_ "GenSigSendType" SG_ 1104 GE8_res_55 0;
BA_ "GenSigSendType" SG_ 1104 GE8_res_56 0;
BA_ "GenSigSendType" SG_ 1104 GE8_res_57 0;
BA_ "GenSigSendType" SG_ 1104 GE8_res_51 0;
BA_ "GenSigSendType" SG_ 1104 GE8_res_58 0;
BA_ "GenSigSendType" SG_ 1104 GE8_res_59 0;
BA_ "GenSigSendType" SG_ 1104 GE8_res_60 0;
BA_ "GenSigSendType" SG_ 1104 GE8_res_61 0;
BA_ "GenSigSendType" SG_ 1104 GE8_res_63 0;
BA_ "GenSigSendType" SG_ 1104 GE8_res_62 0;
BA_ "GenSigTimeoutTime_Selespeed" SG_ 1102 WH2_Fehler0 500;
BA_ "GenSigTimeoutMsg_Selespeed" SG_ 1102 WH2_Fehler0 1102;
BA_ "GenSigSendType" SG_ 1102 WH2_Fehler0 0;
BA_ "GenSigTimeoutTime_Selespeed" SG_ 1102 WH2_Testergebnis 500;
BA_ "GenSigTimeoutMsg_Selespeed" SG_ 1102 WH2_Testergebnis 1102;
BA_ "GenSigSendType" SG_ 1102 WH2_Testergebnis 0;
BA_ "GenSigTimeoutTime_Selespeed" SG_ 1102 WH2_Zaehler 500;
BA_ "GenSigTimeoutMsg_Selespeed" SG_ 1102 WH2_Zaehler 1102;
BA_ "GenSigSendType" SG_ 1102 WH2_Zaehler 0;
BA_ "GenSigTimeoutTime_Selespeed" SG_ 1102 WH2_Init 500;
BA_ "GenSigTimeoutMsg_Selespeed" SG_ 1102 WH2_Init 1102;
BA_ "GenSigSendType" SG_ 1102 WH2_Init 0;
BA_ "GenSigStartValue" SG_ 1102 WH2_Init 1;
BA_ "GenSigTimeoutTime_Selespeed" SG_ 1102 WH2_Checksumme 500;
BA_ "GenSigTimeoutMsg_Selespeed" SG_ 1102 WH2_Checksumme 1102;
BA_ "GenSigSendType" SG_ 1102 WH2_Checksumme 0;
BA_ "INIT" SG_ 1102 WH2_Checksumme "CHK";
BA_ "GenSigTimeoutTime_Selespeed" SG_ 1102 WH2_Winter 500;
BA_ "GenSigTimeoutMsg_Selespeed" SG_ 1102 WH2_Winter 1102;
BA_ "GenSigSendType" SG_ 1102 WH2_Winter 0;
BA_ "GenSigTimeoutTime_Selespeed" SG_ 1102 WH2_Sport 500;
BA_ "GenSigTimeoutMsg_Selespeed" SG_ 1102 WH2_Sport 1102;
BA_ "GenSigSendType" SG_ 1102 WH2_Sport 0;
BA_ "GenSigTimeoutTime_Selespeed" SG_ 1102 WH2_Reserve1 500;
BA_ "GenSigTimeoutMsg_Selespeed" SG_ 1102 WH2_Reserve1 1102;
BA_ "GenSigSendType" SG_ 1102 WH2_Reserve1 0;
BA_ "GenSigTimeoutTime_Selespeed" SG_ 1102 WH2_Test_Flag 500;
BA_ "GenSigTimeoutMsg_Selespeed" SG_ 1102 WH2_Test_Flag 1102;
BA_ "GenSigSendType" SG_ 1102 WH2_Test_Flag 0;
BA_ "GenSigTimeoutTime_Selespeed" SG_ 1102 WH2_Position 500;
BA_ "GenSigTimeoutMsg_Selespeed" SG_ 1102 WH2_Position 1102;
BA_ "GenSigSendType" SG_ 1102 WH2_Position 0;
BA_ "GenSigTimeoutTime_Selespeed" SG_ 1102 WH2_Ruhestromfehler 500;
BA_ "GenSigTimeoutMsg_Selespeed" SG_ 1102 WH2_Ruhestromfehler 1102;
BA_ "GenSigSendType" SG_ 1102 WH2_Ruhestromfehler 0;
BA_ "GenSigTimeoutTime_Selespeed" SG_ 1102 WH2_Fehler2 500;
BA_ "GenSigTimeoutMsg_Selespeed" SG_ 1102 WH2_Fehler2 1102;
BA_ "GenSigSendType" SG_ 1102 WH2_Fehler2 0;
BA_ "GenSigTimeoutTime_Selespeed" SG_ 1102 WH2_Fehler1 500;
BA_ "GenSigTimeoutMsg_Selespeed" SG_ 1102 WH2_Fehler1 1102;
BA_ "GenSigSendType" SG_ 1102 WH2_Fehler1 0;
BA_ "GenSigTimeoutTime_Selespeed" SG_ 1102 WH2_Fehler4 500;
BA_ "GenSigTimeoutMsg_Selespeed" SG_ 1102 WH2_Fehler4 1102;
BA_ "GenSigSendType" SG_ 1102 WH2_Fehler4 0;
BA_ "GenSigTimeoutTime_Selespeed" SG_ 1102 WH2_Fehler5 500;
BA_ "GenSigTimeoutMsg_Selespeed" SG_ 1102 WH2_Fehler5 1102;
BA_ "GenSigSendType" SG_ 1102 WH2_Fehler5 0;
BA_ "GenSigTimeoutTime_Selespeed" SG_ 1102 WH2_Fehler3 500;
BA_ "GenSigTimeoutMsg_Selespeed" SG_ 1102 WH2_Fehler3 1102;
BA_ "GenSigSendType" SG_ 1102 WH2_Fehler3 0;
BA_ "GenSigTimeoutTime_Selespeed" SG_ 1102 WH2_Fehler7 500;
BA_ "GenSigTimeoutMsg_Selespeed" SG_ 1102 WH2_Fehler7 1102;
BA_ "GenSigSendType" SG_ 1102 WH2_Fehler7 0;
BA_ "GenSigTimeoutTime_Selespeed" SG_ 1102 WH2_Fehler6 500;
BA_ "GenSigTimeoutMsg_Selespeed" SG_ 1102 WH2_Fehler6 1102;
BA_ "GenSigSendType" SG_ 1102 WH2_Fehler6 0;
BA_ "GenSigTimeoutTime_Gateway_PQ35_A" SG_ 1494 PLS_PL_exist 1000;
BA_ "GenSigTimeoutMsg_Gateway_PQ35_A" SG_ 1494 PLS_PL_exist 1494;
BA_ "GenSigTimeoutTime_Gateway_PQ46_A" SG_ 1494 PLS_PL_exist 1000;
BA_ "GenSigTimeoutMsg_Gateway_PQ46_A" SG_ 1494 PLS_PL_exist 1494;
BA_ "GenSigSendType" SG_ 1494 PLS_PL_exist 0;
BA_ "GenSigTimeoutTime_Gateway_PQ35_A" SG_ 1494 PLS_mehrzg_aktiv 1000;
BA_ "GenSigTimeoutMsg_Gateway_PQ35_A" SG_ 1494 PLS_mehrzg_aktiv 1494;
BA_ "GenSigTimeoutTime_Gateway_PQ46_A" SG_ 1494 PLS_mehrzg_aktiv 1000;
BA_ "GenSigTimeoutMsg_Gateway_PQ46_A" SG_ 1494 PLS_mehrzg_aktiv 1494;
BA_ "GenSigSendType" SG_ 1494 PLS_mehrzg_aktiv 0;
BA_ "GenSigTimeoutTime_Gateway_PQ35_A" SG_ 1494 PLS_Anf_Anz 1000;
BA_ "GenSigTimeoutMsg_Gateway_PQ35_A" SG_ 1494 PLS_Anf_Anz 1494;
BA_ "GenSigTimeoutTime_Gateway_PQ46_A" SG_ 1494 PLS_Anf_Anz 1000;
BA_ "GenSigTimeoutMsg_Gateway_PQ46_A" SG_ 1494 PLS_Anf_Anz 1494;
BA_ "GenSigSendType" SG_ 1494 PLS_Anf_Anz 0;
BA_ "GenSigTimeoutTime_Gateway_PQ35_A" SG_ 1494 PLS_Pos_OK 1000;
BA_ "GenSigTimeoutMsg_Gateway_PQ35_A" SG_ 1494 PLS_Pos_OK 1494;
BA_ "GenSigTimeoutTime_Gateway_PQ46_A" SG_ 1494 PLS_Pos_OK 1000;
BA_ "GenSigTimeoutMsg_Gateway_PQ46_A" SG_ 1494 PLS_Pos_OK 1494;
BA_ "GenSigSendType" SG_ 1494 PLS_Pos_OK 0;
BA_ "GenSigTimeoutTime_Gateway_PQ35_A" SG_ 1494 PLS_PL_Seite 1000;
BA_ "GenSigTimeoutMsg_Gateway_PQ35_A" SG_ 1494 PLS_PL_Seite 1494;
BA_ "GenSigTimeoutTime_Gateway_PQ46_A" SG_ 1494 PLS_PL_Seite 1000;
BA_ "GenSigTimeoutMsg_Gateway_PQ46_A" SG_ 1494 PLS_PL_Seite 1494;
BA_ "GenSigSendType" SG_ 1494 PLS_PL_Seite 0;
BA_ "GenSigTimeoutTime_Gateway_PQ35_A" SG_ 1494 PLS_Meldungen 1000;
BA_ "GenSigTimeoutMsg_Gateway_PQ35_A" SG_ 1494 PLS_Meldungen 1494;
BA_ "GenSigTimeoutTime_Gateway_PQ46_A" SG_ 1494 PLS_Meldungen 1000;
BA_ "GenSigTimeoutMsg_Gateway_PQ46_A" SG_ 1494 PLS_Meldungen 1494;
BA_ "GenSigSendType" SG_ 1494 PLS_Meldungen 0;
BA_ "GenSigTimeoutTime_Gateway_PQ35_A" SG_ 1494 PLS_Lenk_Aktiv 1000;
BA_ "GenSigTimeoutMsg_Gateway_PQ35_A" SG_ 1494 PLS_Lenk_Aktiv 1494;
BA_ "GenSigTimeoutTime_Gateway_PQ46_A" SG_ 1494 PLS_Lenk_Aktiv 1000;
BA_ "GenSigTimeoutMsg_Gateway_PQ46_A" SG_ 1494 PLS_Lenk_Aktiv 1494;
BA_ "GenSigSendType" SG_ 1494 PLS_Lenk_Aktiv 0;
BA_ "GenSigTimeoutTime_Gateway_PQ35_A" SG_ 1494 PLS_Akustik1 1000;
BA_ "GenSigTimeoutMsg_Gateway_PQ35_A" SG_ 1494 PLS_Akustik1 1494;
BA_ "GenSigTimeoutTime_Gateway_PQ46_A" SG_ 1494 PLS_Akustik1 1000;
BA_ "GenSigTimeoutMsg_Gateway_PQ46_A" SG_ 1494 PLS_Akustik1 1494;
BA_ "GenSigSendType" SG_ 1494 PLS_Akustik1 0;
BA_ "GenSigTimeoutTime_Gateway_PQ35_A" SG_ 1494 PLS_Akustik2 1000;
BA_ "GenSigTimeoutMsg_Gateway_PQ35_A" SG_ 1494 PLS_Akustik2 1494;
BA_ "GenSigTimeoutTime_Gateway_PQ46_A" SG_ 1494 PLS_Akustik2 1000;
BA_ "GenSigTimeoutMsg_Gateway_PQ46_A" SG_ 1494 PLS_Akustik2 1494;
BA_ "GenSigSendType" SG_ 1494 PLS_Akustik2 0;
BA_ "GenSigTimeoutTime_Gateway_PQ35_A" SG_ 1494 PLS_AnzeigePrio 1000;
BA_ "GenSigTimeoutMsg_Gateway_PQ35_A" SG_ 1494 PLS_AnzeigePrio 1494;
BA_ "GenSigTimeoutTime_Gateway_PQ46_A" SG_ 1494 PLS_AnzeigePrio 1000;
BA_ "GenSigTimeoutMsg_Gateway_PQ46_A" SG_ 1494 PLS_AnzeigePrio 1494;
BA_ "GenSigSendType" SG_ 1494 PLS_AnzeigePrio 0;
BA_ "GenSigTimeoutTime_Gateway_PQ35_A" SG_ 1494 PLS_Fahrtrichtg_mehrzg 1000;
BA_ "GenSigTimeoutMsg_Gateway_PQ35_A" SG_ 1494 PLS_Fahrtrichtg_mehrzg 1494;
BA_ "GenSigTimeoutTime_Gateway_PQ46_A" SG_ 1494 PLS_Fahrtrichtg_mehrzg 1000;
BA_ "GenSigTimeoutMsg_Gateway_PQ46_A" SG_ 1494 PLS_Fahrtrichtg_mehrzg 1494;
BA_ "GenSigSendType" SG_ 1494 PLS_Fahrtrichtg_mehrzg 0;
BA_ "GenSigTimeoutTime_Lenkhilfe_ZF_3" SG_ 980 PL1_Stat_PLA_EPS 500;
BA_ "GenSigTimeoutMsg_Lenkhilfe_ZF_3" SG_ 980 PL1_Stat_PLA_EPS 980;
BA_ "GenSigTimeoutTime_Lenkhilfe_APA" SG_ 980 PL1_Stat_PLA_EPS 500;
BA_ "GenSigTimeoutMsg_Lenkhilfe_APA" SG_ 980 PL1_Stat_PLA_EPS 980;
BA_ "GenSigTimeoutTime_Lenkhilfe_ZF_2" SG_ 980 PL1_Stat_PLA_EPS 500;
BA_ "GenSigTimeoutMsg_Lenkhilfe_ZF_2" SG_ 980 PL1_Stat_PLA_EPS 980;
BA_ "GenSigSendType" SG_ 980 PL1_Stat_PLA_EPS 0;
BA_ "GenSigTimeoutTime_Lenkhilfe_ZF_3" SG_ 980 PL1_LW_Soll 500;
BA_ "GenSigTimeoutMsg_Lenkhilfe_ZF_3" SG_ 980 PL1_LW_Soll 980;
BA_ "GenSigTimeoutTime_Lenkhilfe_APA" SG_ 980 PL1_LW_Soll 500;
BA_ "GenSigTimeoutMsg_Lenkhilfe_APA" SG_ 980 PL1_LW_Soll 980;
BA_ "GenSigTimeoutTime_Lenkhilfe_ZF_2" SG_ 980 PL1_LW_Soll 500;
BA_ "GenSigTimeoutMsg_Lenkhilfe_ZF_2" SG_ 980 PL1_LW_Soll 980;
BA_ "GenSigSendType" SG_ 980 PL1_LW_Soll 0;
BA_ "GenSigTimeoutTime_Lenkhilfe_ZF_3" SG_ 980 PL1_Zaehler 500;
BA_ "GenSigTimeoutMsg_Lenkhilfe_ZF_3" SG_ 980 PL1_Zaehler 980;
BA_ "GenSigTimeoutTime_Lenkhilfe_APA" SG_ 980 PL1_Zaehler 500;
BA_ "GenSigTimeoutMsg_Lenkhilfe_APA" SG_ 980 PL1_Zaehler 980;
BA_ "GenSigTimeoutTime_Lenkhilfe_ZF_2" SG_ 980 PL1_Zaehler 500;
BA_ "GenSigTimeoutMsg_Lenkhilfe_ZF_2" SG_ 980 PL1_Zaehler 980;
BA_ "GenSigSendType" SG_ 980 PL1_Zaehler 0;
BA_ "GenSigTimeoutTime_Lenkhilfe_ZF_3" SG_ 980 PL1_Checksumme 500;
BA_ "GenSigTimeoutMsg_Lenkhilfe_ZF_3" SG_ 980 PL1_Checksumme 980;
BA_ "GenSigTimeoutTime_Lenkhilfe_APA" SG_ 980 PL1_Checksumme 500;
BA_ "GenSigTimeoutMsg_Lenkhilfe_APA" SG_ 980 PL1_Checksumme 980;
BA_ "GenSigTimeoutTime_Lenkhilfe_ZF_2" SG_ 980 PL1_Checksumme 500;
BA_ "GenSigTimeoutMsg_Lenkhilfe_ZF_2" SG_ 980 PL1_Checksumme 980;
BA_ "GenSigSendType" SG_ 980 PL1_Checksumme 0;
BA_ "INIT" SG_ 980 PL1_Checksumme "CHK";
BA_ "GenSigTimeoutTime_Lenkhilfe_ZF_3" SG_ 980 PL1_LW_Soll_Sign 500;
BA_ "GenSigTimeoutMsg_Lenkhilfe_ZF_3" SG_ 980 PL1_LW_Soll_Sign 980;
BA_ "GenSigTimeoutTime_Lenkhilfe_APA" SG_ 980 PL1_LW_Soll_Sign 500;
BA_ "GenSigTimeoutMsg_Lenkhilfe_APA" SG_ 980 PL1_LW_Soll_Sign 980;
BA_ "GenSigTimeoutTime_Lenkhilfe_ZF_2" SG_ 980 PL1_LW_Soll_Sign 500;
BA_ "GenSigTimeoutMsg_Lenkhilfe_ZF_2" SG_ 980 PL1_LW_Soll_Sign 980;
BA_ "GenSigSendType" SG_ 980 PL1_LW_Soll_Sign 0;
BA_ "GenSigTimeoutMsg_Gateway_PQ35_A" SG_ 541 PLA_PDC_TP_Er 541;
BA_ "GenSigTimeoutMsg_Gateway_PQ46_A" SG_ 541 PLA_PDC_TP_Er 541;
BA_ "GenSigSendType" SG_ 541 PLA_PDC_TP_Er 5;
BA_ "GenSigTimeoutMsg_Gateway_PQ35_A" SG_ 1355 PA5_VMR_Abstand 1355;
BA_ "GenSigTimeoutMsg_Gateway_PQ46_A" SG_ 1355 PA5_VMR_Abstand 1355;
BA_ "GenSigSendType" SG_ 1355 PA5_VMR_Abstand 5;
BA_ "GenSigStartValue" SG_ 1355 PA5_VMR_Abstand 255;
BA_ "GenSigTimeoutMsg_Gateway_PQ35_A" SG_ 1355 PA5_VL_Abstand 1355;
BA_ "GenSigTimeoutMsg_Gateway_PQ46_A" SG_ 1355 PA5_VL_Abstand 1355;
BA_ "GenSigSendType" SG_ 1355 PA5_VL_Abstand 5;
BA_ "GenSigStartValue" SG_ 1355 PA5_VL_Abstand 255;
BA_ "GenSigTimeoutMsg_Gateway_PQ35_A" SG_ 1355 PA5_HL_Abstand 1355;
BA_ "GenSigTimeoutMsg_Gateway_PQ46_A" SG_ 1355 PA5_HL_Abstand 1355;
BA_ "GenSigSendType" SG_ 1355 PA5_HL_Abstand 5;
BA_ "GenSigStartValue" SG_ 1355 PA5_HL_Abstand 255;
BA_ "GenSigTimeoutMsg_Gateway_PQ35_A" SG_ 1355 PA5_HR_Abstand 1355;
BA_ "GenSigTimeoutMsg_Gateway_PQ46_A" SG_ 1355 PA5_HR_Abstand 1355;
BA_ "GenSigSendType" SG_ 1355 PA5_HR_Abstand 5;
BA_ "GenSigStartValue" SG_ 1355 PA5_HR_Abstand 255;
BA_ "GenSigTimeoutMsg_Gateway_PQ35_A" SG_ 1355 PA5_HML_Abstand 1355;
BA_ "GenSigTimeoutMsg_Gateway_PQ46_A" SG_ 1355 PA5_HML_Abstand 1355;
BA_ "GenSigSendType" SG_ 1355 PA5_HML_Abstand 5;
BA_ "GenSigStartValue" SG_ 1355 PA5_HML_Abstand 255;
BA_ "GenSigTimeoutMsg_Gateway_PQ35_A" SG_ 1355 PA5_HMR_Abstand 1355;
BA_ "GenSigTimeoutMsg_Gateway_PQ46_A" SG_ 1355 PA5_HMR_Abstand 1355;
BA_ "GenSigSendType" SG_ 1355 PA5_HMR_Abstand 5;
BA_ "GenSigStartValue" SG_ 1355 PA5_HMR_Abstand 255;
BA_ "GenSigTimeoutMsg_Gateway_PQ35_A" SG_ 1355 PA5_VML_Abstand 1355;
BA_ "GenSigTimeoutMsg_Gateway_PQ46_A" SG_ 1355 PA5_VML_Abstand 1355;
BA_ "GenSigSendType" SG_ 1355 PA5_VML_Abstand 5;
BA_ "GenSigStartValue" SG_ 1355 PA5_VML_Abstand 255;
BA_ "GenSigTimeoutMsg_Gateway_PQ35_A" SG_ 1355 PA5_VR_Abstand 1355;
BA_ "GenSigTimeoutMsg_Gateway_PQ46_A" SG_ 1355 PA5_VR_Abstand 1355;
BA_ "GenSigSendType" SG_ 1355 PA5_VR_Abstand 5;
BA_ "GenSigStartValue" SG_ 1355 PA5_VR_Abstand 255;
BA_ "GenSigTimeoutTime_Gateway_PQ35_A" SG_ 1175 PH_Opt_Anzeige_V_ein 1000;
BA_ "GenSigTimeoutMsg_Gateway_PQ35_A" SG_ 1175 PH_Opt_Anzeige_V_ein 1175;
BA_ "GenSigTimeoutTime_Gateway_PQ46_A" SG_ 1175 PH_Opt_Anzeige_V_ein 1000;
BA_ "GenSigTimeoutMsg_Gateway_PQ46_A" SG_ 1175 PH_Opt_Anzeige_V_ein 1175;
BA_ "GenSigSendType" SG_ 1175 PH_Opt_Anzeige_V_ein 3;
BA_ "GenSigTimeoutTime_Gateway_PQ35_A" SG_ 1175 PH_Opt_Anzeige_H_ein 1000;
BA_ "GenSigTimeoutMsg_Gateway_PQ35_A" SG_ 1175 PH_Opt_Anzeige_H_ein 1175;
BA_ "GenSigTimeoutTime_Gateway_PQ46_A" SG_ 1175 PH_Opt_Anzeige_H_ein 1000;
BA_ "GenSigTimeoutMsg_Gateway_PQ46_A" SG_ 1175 PH_Opt_Anzeige_H_ein 1175;
BA_ "GenSigSendType" SG_ 1175 PH_Opt_Anzeige_H_ein 3;
BA_ "GenSigTimeoutTime_Gateway_PQ35_A" SG_ 1175 PH_Opt_Anz_V_Hindernis 1000;
BA_ "GenSigTimeoutMsg_Gateway_PQ35_A" SG_ 1175 PH_Opt_Anz_V_Hindernis 1175;
BA_ "GenSigTimeoutTime_Gateway_PQ46_A" SG_ 1175 PH_Opt_Anz_V_Hindernis 1000;
BA_ "GenSigTimeoutMsg_Gateway_PQ46_A" SG_ 1175 PH_Opt_Anz_V_Hindernis 1175;
BA_ "GenSigSendType" SG_ 1175 PH_Opt_Anz_V_Hindernis 3;
BA_ "GenSigTimeoutTime_Gateway_PQ35_A" SG_ 1175 PH_Abschaltursache 1000;
BA_ "GenSigTimeoutMsg_Gateway_PQ35_A" SG_ 1175 PH_Abschaltursache 1175;
BA_ "GenSigTimeoutTime_Gateway_PQ46_A" SG_ 1175 PH_Abschaltursache 1000;
BA_ "GenSigTimeoutMsg_Gateway_PQ46_A" SG_ 1175 PH_Abschaltursache 1175;
BA_ "GenSigSendType" SG_ 1175 PH_Abschaltursache 3;
BA_ "GenSigTimeoutTime_Gateway_PQ35_A" SG_ 1175 PH_Opt_Anz_H_Hindernis 1000;
BA_ "GenSigTimeoutMsg_Gateway_PQ35_A" SG_ 1175 PH_Opt_Anz_H_Hindernis 1175;
BA_ "GenSigTimeoutTime_Gateway_PQ46_A" SG_ 1175 PH_Opt_Anz_H_Hindernis 1000;
BA_ "GenSigTimeoutMsg_Gateway_PQ46_A" SG_ 1175 PH_Opt_Anz_H_Hindernis 1175;
BA_ "GenSigSendType" SG_ 1175 PH_Opt_Anz_H_Hindernis 3;
BA_ "GenSigTimeoutTime_Gateway_PQ35_A" SG_ 1175 PH_Tongeber_V_aktiv 1000;
BA_ "GenSigTimeoutMsg_Gateway_PQ35_A" SG_ 1175 PH_Tongeber_V_aktiv 1175;
BA_ "GenSigTimeoutTime_Gateway_PQ46_A" SG_ 1175 PH_Tongeber_V_aktiv 1000;
BA_ "GenSigTimeoutMsg_Gateway_PQ46_A" SG_ 1175 PH_Tongeber_V_aktiv 1175;
BA_ "GenSigSendType" SG_ 1175 PH_Tongeber_V_aktiv 3;
BA_ "GenSigTimeoutTime_Gateway_PQ35_A" SG_ 1175 PH_Tongeber_mute 1000;
BA_ "GenSigTimeoutMsg_Gateway_PQ35_A" SG_ 1175 PH_Tongeber_mute 1175;
BA_ "GenSigTimeoutTime_Gateway_PQ46_A" SG_ 1175 PH_Tongeber_mute 1000;
BA_ "GenSigTimeoutMsg_Gateway_PQ46_A" SG_ 1175 PH_Tongeber_mute 1175;
BA_ "GenSigSendType" SG_ 1175 PH_Tongeber_mute 3;
BA_ "GenSigTimeoutTime_Gateway_PQ35_A" SG_ 1175 PH_Frequenz_hinten 1000;
BA_ "GenSigTimeoutMsg_Gateway_PQ35_A" SG_ 1175 PH_Frequenz_hinten 1175;
BA_ "GenSigTimeoutTime_Gateway_PQ46_A" SG_ 1175 PH_Frequenz_hinten 1000;
BA_ "GenSigTimeoutMsg_Gateway_PQ46_A" SG_ 1175 PH_Frequenz_hinten 1175;
BA_ "GenSigSendType" SG_ 1175 PH_Frequenz_hinten 0;
BA_ "GenSigTimeoutTime_Gateway_PQ35_A" SG_ 1175 PH_Lautstaerke_hinten 1000;
BA_ "GenSigTimeoutMsg_Gateway_PQ35_A" SG_ 1175 PH_Lautstaerke_hinten 1175;
BA_ "GenSigTimeoutTime_Gateway_PQ46_A" SG_ 1175 PH_Lautstaerke_hinten 1000;
BA_ "GenSigTimeoutMsg_Gateway_PQ46_A" SG_ 1175 PH_Lautstaerke_hinten 1175;
BA_ "GenSigSendType" SG_ 1175 PH_Lautstaerke_hinten 0;
BA_ "GenSigTimeoutTime_Gateway_PQ35_A" SG_ 1175 PH_Tongeber_H_aktiv 1000;
BA_ "GenSigTimeoutMsg_Gateway_PQ35_A" SG_ 1175 PH_Tongeber_H_aktiv 1175;
BA_ "GenSigTimeoutTime_Gateway_PQ46_A" SG_ 1175 PH_Tongeber_H_aktiv 1000;
BA_ "GenSigTimeoutMsg_Gateway_PQ46_A" SG_ 1175 PH_Tongeber_H_aktiv 1175;
BA_ "GenSigSendType" SG_ 1175 PH_Tongeber_H_aktiv 3;
BA_ "GenSigTimeoutTime_Gateway_PQ35_A" SG_ 1175 PH_Frequenz_vorn 1000;
BA_ "GenSigTimeoutMsg_Gateway_PQ35_A" SG_ 1175 PH_Frequenz_vorn 1175;
BA_ "GenSigTimeoutTime_Gateway_PQ46_A" SG_ 1175 PH_Frequenz_vorn 1000;
BA_ "GenSigTimeoutMsg_Gateway_PQ46_A" SG_ 1175 PH_Frequenz_vorn 1175;
BA_ "GenSigSendType" SG_ 1175 PH_Frequenz_vorn 0;
BA_ "GenSigTimeoutTime_Gateway_PQ35_A" SG_ 1175 PH_Lautstaerke_vorn 1000;
BA_ "GenSigTimeoutMsg_Gateway_PQ35_A" SG_ 1175 PH_Lautstaerke_vorn 1175;
BA_ "GenSigTimeoutTime_Gateway_PQ46_A" SG_ 1175 PH_Lautstaerke_vorn 1000;
BA_ "GenSigTimeoutMsg_Gateway_PQ46_A" SG_ 1175 PH_Lautstaerke_vorn 1175;
BA_ "GenSigSendType" SG_ 1175 PH_Lautstaerke_vorn 0;
BA_ "GenSigTimeoutTime_Gateway_PQ35_A" SG_ 1175 PH_defekt 1000;
BA_ "GenSigTimeoutMsg_Gateway_PQ35_A" SG_ 1175 PH_defekt 1175;
BA_ "GenSigTimeoutTime_Gateway_PQ46_A" SG_ 1175 PH_defekt 1000;
BA_ "GenSigTimeoutMsg_Gateway_PQ46_A" SG_ 1175 PH_defekt 1175;
BA_ "GenSigSendType" SG_ 1175 PH_defekt 3;
BA_ "GenSigTimeoutTime_Gateway_PQ35_A" SG_ 1175 PH_Anf_Audioabsenkung 1000;
BA_ "GenSigTimeoutMsg_Gateway_PQ35_A" SG_ 1175 PH_Anf_Audioabsenkung 1175;
BA_ "GenSigTimeoutTime_Gateway_PQ46_A" SG_ 1175 PH_Anf_Audioabsenkung 1000;
BA_ "GenSigTimeoutMsg_Gateway_PQ46_A" SG_ 1175 PH_Anf_Audioabsenkung 1175;
BA_ "GenSigSendType" SG_ 1175 PH_Anf_Audioabsenkung 3;
BA_ "GenSigTimeoutTime_Gateway_PQ35_A" SG_ 1175 PH_Systemzustand 1000;
BA_ "GenSigTimeoutMsg_Gateway_PQ35_A" SG_ 1175 PH_Systemzustand 1175;
BA_ "GenSigTimeoutTime_Gateway_PQ46_A" SG_ 1175 PH_Systemzustand 1000;
BA_ "GenSigTimeoutMsg_Gateway_PQ46_A" SG_ 1175 PH_Systemzustand 1175;
BA_ "GenSigSendType" SG_ 1175 PH_Systemzustand 3;
BA_ "GenSigTimeoutTime_Gateway_PQ35_A" SG_ 1175 PH_Display_Kundenwunsch 1000;
BA_ "GenSigTimeoutMsg_Gateway_PQ35_A" SG_ 1175 PH_Display_Kundenwunsch 1175;
BA_ "GenSigTimeoutTime_Gateway_PQ46_A" SG_ 1175 PH_Display_Kundenwunsch 1000;
BA_ "GenSigTimeoutMsg_Gateway_PQ46_A" SG_ 1175 PH_Display_Kundenwunsch 1175;
BA_ "GenSigSendType" SG_ 1175 PH_Display_Kundenwunsch 3;
BA_ "GenSigTimeoutTime_Gateway_PQ35_A" SG_ 1175 PH_KD_Fehler 1000;
BA_ "GenSigTimeoutMsg_Gateway_PQ35_A" SG_ 1175 PH_KD_Fehler 1175;
BA_ "GenSigTimeoutTime_Gateway_PQ46_A" SG_ 1175 PH_KD_Fehler 1000;
BA_ "GenSigTimeoutMsg_Gateway_PQ46_A" SG_ 1175 PH_KD_Fehler 1175;
BA_ "GenSigSendType" SG_ 1175 PH_KD_Fehler 3;
BA_ "GenSigTimeoutTime_Gateway_PQ35_A" SG_ 1175 PH_gestoert 1000;
BA_ "GenSigTimeoutMsg_Gateway_PQ35_A" SG_ 1175 PH_gestoert 1175;
BA_ "GenSigTimeoutTime_Gateway_PQ46_A" SG_ 1175 PH_gestoert 1000;
BA_ "GenSigTimeoutMsg_Gateway_PQ46_A" SG_ 1175 PH_gestoert 1175;
BA_ "GenSigSendType" SG_ 1175 PH_gestoert 3;
BA_ "GenSigTimeoutTime_Gateway_PQ35_A" SG_ 1175 PH_res_02 1000;
BA_ "GenSigTimeoutMsg_Gateway_PQ35_A" SG_ 1175 PH_res_02 1175;
BA_ "GenSigTimeoutTime_Gateway_PQ46_A" SG_ 1175 PH_res_02 1000;
BA_ "GenSigTimeoutMsg_Gateway_PQ46_A" SG_ 1175 PH_res_02 1175;
BA_ "GenSigSendType" SG_ 1175 PH_res_02 0;
BA_ "GenSigTimeoutTime_Gateway_PQ35_A" SG_ 1175 PH_res_04 1000;
BA_ "GenSigTimeoutMsg_Gateway_PQ35_A" SG_ 1175 PH_res_04 1175;
BA_ "GenSigTimeoutTime_Gateway_PQ46_A" SG_ 1175 PH_res_04 1000;
BA_ "GenSigTimeoutMsg_Gateway_PQ46_A" SG_ 1175 PH_res_04 1175;
BA_ "GenSigSendType" SG_ 1175 PH_res_04 0;
BA_ "GenSigTimeoutTime_Gateway_PQ35_A" SG_ 1175 PH_res_01 1000;
BA_ "GenSigTimeoutMsg_Gateway_PQ35_A" SG_ 1175 PH_res_01 1175;
BA_ "GenSigTimeoutTime_Gateway_PQ46_A" SG_ 1175 PH_res_01 1000;
BA_ "GenSigTimeoutMsg_Gateway_PQ46_A" SG_ 1175 PH_res_01 1175;
BA_ "GenSigSendType" SG_ 1175 PH_res_01 0;
BA_ "GenSigTimeoutTime_Gateway_PQ35_A" SG_ 1175 PH_res_00 1000;
BA_ "GenSigTimeoutMsg_Gateway_PQ35_A" SG_ 1175 PH_res_00 1175;
BA_ "GenSigTimeoutTime_Gateway_PQ46_A" SG_ 1175 PH_res_00 1000;
BA_ "GenSigTimeoutMsg_Gateway_PQ46_A" SG_ 1175 PH_res_00 1175;
BA_ "GenSigSendType" SG_ 1175 PH_res_00 0;
BA_ "GenSigTimeoutTime_Gateway_PQ35_A" SG_ 1175 PH_res_05 1000;
BA_ "GenSigTimeoutMsg_Gateway_PQ35_A" SG_ 1175 PH_res_05 1175;
BA_ "GenSigTimeoutTime_Gateway_PQ46_A" SG_ 1175 PH_res_05 1000;
BA_ "GenSigTimeoutMsg_Gateway_PQ46_A" SG_ 1175 PH_res_05 1175;
BA_ "GenSigSendType" SG_ 1175 PH_res_05 0;
BA_ "GenSigTimeoutTime_Gateway_PQ35_A" SG_ 1175 PH_res_03 1000;
BA_ "GenSigTimeoutMsg_Gateway_PQ35_A" SG_ 1175 PH_res_03 1175;
BA_ "GenSigTimeoutTime_Gateway_PQ46_A" SG_ 1175 PH_res_03 1000;
BA_ "GenSigTimeoutMsg_Gateway_PQ46_A" SG_ 1175 PH_res_03 1175;
BA_ "GenSigSendType" SG_ 1175 PH_res_03 0;
BA_ "GenSigTimeoutTime_Gateway_PQ35_A" SG_ 1175 PH_res_06 1000;
BA_ "GenSigTimeoutMsg_Gateway_PQ35_A" SG_ 1175 PH_res_06 1175;
BA_ "GenSigTimeoutTime_Gateway_PQ46_A" SG_ 1175 PH_res_06 1000;
BA_ "GenSigTimeoutMsg_Gateway_PQ46_A" SG_ 1175 PH_res_06 1175;
BA_ "GenSigSendType" SG_ 1175 PH_res_06 0;
BA_ "GenSigTimeoutTime_Gateway_PQ35_A" SG_ 1175 PH_res_07 1000;
BA_ "GenSigTimeoutMsg_Gateway_PQ35_A" SG_ 1175 PH_res_07 1175;
BA_ "GenSigTimeoutTime_Gateway_PQ46_A" SG_ 1175 PH_res_07 1000;
BA_ "GenSigTimeoutMsg_Gateway_PQ46_A" SG_ 1175 PH_res_07 1175;
BA_ "GenSigSendType" SG_ 1175 PH_res_07 0;
BA_ "GenSigTimeoutTime_Gateway_PQ35_A" SG_ 1175 PH_res_08 1000;
BA_ "GenSigTimeoutMsg_Gateway_PQ35_A" SG_ 1175 PH_res_08 1175;
BA_ "GenSigTimeoutTime_Gateway_PQ46_A" SG_ 1175 PH_res_08 1000;
BA_ "GenSigTimeoutMsg_Gateway_PQ46_A" SG_ 1175 PH_res_08 1175;
BA_ "GenSigSendType" SG_ 1175 PH_res_08 3;
BA_ "GenSigTimeoutTime_Gateway_PQ35_A" SG_ 1175 PH_res_10 1000;
BA_ "GenSigTimeoutMsg_Gateway_PQ35_A" SG_ 1175 PH_res_10 1175;
BA_ "GenSigTimeoutTime_Gateway_PQ46_A" SG_ 1175 PH_res_10 1000;
BA_ "GenSigTimeoutMsg_Gateway_PQ46_A" SG_ 1175 PH_res_10 1175;
BA_ "GenSigSendType" SG_ 1175 PH_res_10 3;
BA_ "GenSigTimeoutTime_Gateway_PQ35_A" SG_ 1175 PH_res_11 1000;
BA_ "GenSigTimeoutMsg_Gateway_PQ35_A" SG_ 1175 PH_res_11 1175;
BA_ "GenSigTimeoutTime_Gateway_PQ46_A" SG_ 1175 PH_res_11 1000;
BA_ "GenSigTimeoutMsg_Gateway_PQ46_A" SG_ 1175 PH_res_11 1175;
BA_ "GenSigSendType" SG_ 1175 PH_res_11 3;
BA_ "GenSigTimeoutTime_Gateway_PQ35_A" SG_ 1175 PH_res_12 1000;
BA_ "GenSigTimeoutMsg_Gateway_PQ35_A" SG_ 1175 PH_res_12 1175;
BA_ "GenSigTimeoutTime_Gateway_PQ46_A" SG_ 1175 PH_res_12 1000;
BA_ "GenSigTimeoutMsg_Gateway_PQ46_A" SG_ 1175 PH_res_12 1175;
BA_ "GenSigSendType" SG_ 1175 PH_res_12 3;
BA_ "GenSigTimeoutTime_Gateway_PQ35_A" SG_ 1175 PH_res_09 1000;
BA_ "GenSigTimeoutMsg_Gateway_PQ35_A" SG_ 1175 PH_res_09 1175;
BA_ "GenSigTimeoutTime_Gateway_PQ46_A" SG_ 1175 PH_res_09 1000;
BA_ "GenSigTimeoutMsg_Gateway_PQ46_A" SG_ 1175 PH_res_09 1175;
BA_ "GenSigSendType" SG_ 1175 PH_res_09 3;
BA_ "GenSigTimeoutTime_Gateway_PQ35_A" SG_ 1175 PH_res_25 1000;
BA_ "GenSigTimeoutMsg_Gateway_PQ35_A" SG_ 1175 PH_res_25 1175;
BA_ "GenSigTimeoutTime_Gateway_PQ46_A" SG_ 1175 PH_res_25 1000;
BA_ "GenSigTimeoutMsg_Gateway_PQ46_A" SG_ 1175 PH_res_25 1175;
BA_ "GenSigSendType" SG_ 1175 PH_res_25 0;
BA_ "GenSigTimeoutTime_Gateway_PQ35_A" SG_ 1175 PH_res_26 1000;
BA_ "GenSigTimeoutMsg_Gateway_PQ35_A" SG_ 1175 PH_res_26 1175;
BA_ "GenSigTimeoutTime_Gateway_PQ46_A" SG_ 1175 PH_res_26 1000;
BA_ "GenSigTimeoutMsg_Gateway_PQ46_A" SG_ 1175 PH_res_26 1175;
BA_ "GenSigSendType" SG_ 1175 PH_res_26 0;
BA_ "GenSigTimeoutTime_Gateway_PQ35_A" SG_ 1175 PH_res_27 1000;
BA_ "GenSigTimeoutMsg_Gateway_PQ35_A" SG_ 1175 PH_res_27 1175;
BA_ "GenSigTimeoutTime_Gateway_PQ46_A" SG_ 1175 PH_res_27 1000;
BA_ "GenSigTimeoutMsg_Gateway_PQ46_A" SG_ 1175 PH_res_27 1175;
BA_ "GenSigSendType" SG_ 1175 PH_res_27 0;
BA_ "GenSigTimeoutTime_Gateway_PQ35_A" SG_ 1175 PH_res_24 1000;
BA_ "GenSigTimeoutMsg_Gateway_PQ35_A" SG_ 1175 PH_res_24 1175;
BA_ "GenSigTimeoutTime_Gateway_PQ46_A" SG_ 1175 PH_res_24 1000;
BA_ "GenSigTimeoutMsg_Gateway_PQ46_A" SG_ 1175 PH_res_24 1175;
BA_ "GenSigSendType" SG_ 1175 PH_res_24 0;
BA_ "GenSigTimeoutTime_Gateway_PQ35_A" SG_ 1175 PH_res_28 1000;
BA_ "GenSigTimeoutMsg_Gateway_PQ35_A" SG_ 1175 PH_res_28 1175;
BA_ "GenSigTimeoutTime_Gateway_PQ46_A" SG_ 1175 PH_res_28 1000;
BA_ "GenSigTimeoutMsg_Gateway_PQ46_A" SG_ 1175 PH_res_28 1175;
BA_ "GenSigSendType" SG_ 1175 PH_res_28 0;
BA_ "GenSigTimeoutTime_Gateway_PQ35_A" SG_ 1175 PH_res_30 1000;
BA_ "GenSigTimeoutMsg_Gateway_PQ35_A" SG_ 1175 PH_res_30 1175;
BA_ "GenSigTimeoutTime_Gateway_PQ46_A" SG_ 1175 PH_res_30 1000;
BA_ "GenSigTimeoutMsg_Gateway_PQ46_A" SG_ 1175 PH_res_30 1175;
BA_ "GenSigSendType" SG_ 1175 PH_res_30 0;
BA_ "GenSigTimeoutTime_Gateway_PQ35_A" SG_ 1175 PH_Trigger_Bildaufschaltung 1000;
BA_ "GenSigTimeoutMsg_Gateway_PQ35_A" SG_ 1175 PH_Trigger_Bildaufschaltung 1175;
BA_ "GenSigTimeoutTime_Gateway_PQ46_A" SG_ 1175 PH_Trigger_Bildaufschaltung 1000;
BA_ "GenSigTimeoutMsg_Gateway_PQ46_A" SG_ 1175 PH_Trigger_Bildaufschaltung 1175;
BA_ "GenSigSendType" SG_ 1175 PH_Trigger_Bildaufschaltung 3;
BA_ "GenSigTimeoutTime_Gateway_PQ35_A" SG_ 1175 PH_Aufbauten_erk 1000;
BA_ "GenSigTimeoutMsg_Gateway_PQ35_A" SG_ 1175 PH_Aufbauten_erk 1175;
BA_ "GenSigTimeoutTime_Gateway_PQ46_A" SG_ 1175 PH_Aufbauten_erk 1000;
BA_ "GenSigTimeoutMsg_Gateway_PQ46_A" SG_ 1175 PH_Aufbauten_erk 1175;
BA_ "GenSigSendType" SG_ 1175 PH_Aufbauten_erk 3;
BA_ "GenSigTimeoutTime_Gateway_PQ35_A" SG_ 1175 PH_res_29 1000;
BA_ "GenSigTimeoutMsg_Gateway_PQ35_A" SG_ 1175 PH_res_29 1175;
BA_ "GenSigTimeoutTime_Gateway_PQ46_A" SG_ 1175 PH_res_29 1000;
BA_ "GenSigTimeoutMsg_Gateway_PQ46_A" SG_ 1175 PH_res_29 1175;
BA_ "GenSigSendType" SG_ 1175 PH_res_29 0;
BA_ "GenSigTimeoutTime_Gateway_PQ35_A" SG_ 1175 PH_BerErk_vorn 1000;
BA_ "GenSigTimeoutMsg_Gateway_PQ35_A" SG_ 1175 PH_BerErk_vorn 1175;
BA_ "GenSigTimeoutTime_Gateway_PQ46_A" SG_ 1175 PH_BerErk_vorn 1000;
BA_ "GenSigTimeoutMsg_Gateway_PQ46_A" SG_ 1175 PH_BerErk_vorn 1175;
BA_ "GenSigSendType" SG_ 1175 PH_BerErk_vorn 3;
BA_ "GenSigTimeoutTime_Gateway_PQ35_A" SG_ 1175 PH_res_31 1000;
BA_ "GenSigTimeoutMsg_Gateway_PQ35_A" SG_ 1175 PH_res_31 1175;
BA_ "GenSigTimeoutTime_Gateway_PQ46_A" SG_ 1175 PH_res_31 1000;
BA_ "GenSigTimeoutMsg_Gateway_PQ46_A" SG_ 1175 PH_res_31 1175;
BA_ "GenSigSendType" SG_ 1175 PH_res_31 0;
BA_ "GenSigTimeoutTime_Diesel" SG_ 1175 PH_StartStopp_Info 1000;
BA_ "GenSigTimeoutMsg_Diesel" SG_ 1175 PH_StartStopp_Info 1175;
BA_ "GenSigTimeoutTime_Otto" SG_ 1175 PH_StartStopp_Info 1000;
BA_ "GenSigTimeoutMsg_Otto" SG_ 1175 PH_StartStopp_Info 1175;
BA_ "GenSigTimeoutTime_Gateway_PQ35_A" SG_ 1175 PH_StartStopp_Info 1000;
BA_ "GenSigTimeoutMsg_Gateway_PQ35_A" SG_ 1175 PH_StartStopp_Info 1175;
BA_ "GenSigTimeoutTime_Gateway_PQ46_A" SG_ 1175 PH_StartStopp_Info 1000;
BA_ "GenSigTimeoutMsg_Gateway_PQ46_A" SG_ 1175 PH_StartStopp_Info 1175;
BA_ "GenSigSendType" SG_ 1175 PH_StartStopp_Info 3;
BA_ "GenSigTimeoutTime_Gateway_PQ35_A" SG_ 1175 PH_BerErk_hinten 1000;
BA_ "GenSigTimeoutMsg_Gateway_PQ35_A" SG_ 1175 PH_BerErk_hinten 1175;
BA_ "GenSigTimeoutTime_Gateway_PQ46_A" SG_ 1175 PH_BerErk_hinten 1000;
BA_ "GenSigTimeoutMsg_Gateway_PQ46_A" SG_ 1175 PH_BerErk_hinten 1175;
BA_ "GenSigSendType" SG_ 1175 PH_BerErk_hinten 3;
BA_ "GenSigTimeoutMsg_Gateway_PQ35_A" SG_ 1754 BAP_var_OPS 1754;
BA_ "GenSigTimeoutMsg_Gateway_PQ46_A" SG_ 1754 BAP_var_OPS 1754;
BA_ "GenSigTimeoutMsg_Gateway_PQ35_A" SG_ 1754 BAP_Data_OPS 1754;
BA_ "GenSigTimeoutMsg_Gateway_PQ46_A" SG_ 1754 BAP_Data_OPS 1754;
BA_ "GenSigTimeoutMsg_Gateway_PQ35_A" SG_ 1528 Controller_ID_5 1528;
BA_ "GenSigSendType" SG_ 1528 Controller_ID_5 3;
BA_ "GenSigTimeoutMsg_Gateway_PQ35_A" SG_ 1528 Data_Byte_1_5 1528;
BA_ "GenSigSendType" SG_ 1528 Data_Byte_1_5 3;
BA_ "GenSigTimeoutMsg_Gateway_PQ35_A" SG_ 1528 CDEF_APS_AB_res_5 1528;
BA_ "GenSigSendType" SG_ 1528 CDEF_APS_AB_res_5 3;
BA_ "GenSigTimeoutMsg_Gateway_PQ35_A" SG_ 1528 Data_Byte_4_5 1528;
BA_ "GenSigSendType" SG_ 1528 Data_Byte_4_5 3;
BA_ "GenSigTimeoutMsg_Gateway_PQ35_A" SG_ 1528 Data_Byte_2_5 1528;
BA_ "GenSigSendType" SG_ 1528 Data_Byte_2_5 3;
BA_ "GenSigTimeoutMsg_Gateway_PQ35_A" SG_ 1528 Data_Byte_3_5 1528;
BA_ "GenSigSendType" SG_ 1528 Data_Byte_3_5 3;
BA_ "GenSigTimeoutMsg_Gateway_PQ35_A" SG_ 1528 Module_ID_5 1528;
BA_ "GenSigSendType" SG_ 1528 Module_ID_5 3;
BA_ "GenSigTimeoutMsg_Gateway_PQ35_A" SG_ 1528 OpCode_5 1528;
BA_ "GenSigSendType" SG_ 1528 OpCode_5 3;
BA_ "GenSigTimeoutMsg_Gateway_PQ35_A" SG_ 1528 Data_Byte_5_5 1528;
BA_ "GenSigSendType" SG_ 1528 Data_Byte_5_5 3;
BA_ "GenSigTimeoutMsg_Gateway_PQ35_A" SG_ 1528 Funktions_ID_5 1528;
BA_ "GenSigSendType" SG_ 1528 Funktions_ID_5 3;
BA_ "GenSigTimeoutMsg_Gateway_PQ35_A" SG_ 1528 Update_Indikator_5 1528;
BA_ "GenSigSendType" SG_ 1528 Update_Indikator_5 3;
BA_ "GenSigTimeoutMsg_Gateway_PQ35_A" SG_ 1908 ISO_EPH_Resp_Data 1908;
BA_ "GenSigTimeoutMsg_Gateway_PQ46_A" SG_ 1908 ISO_EPH_Resp_Data 1908;
BA_ "GenSigTimeoutTime_Teves_MK60_ESP" SG_ 714 QS2_Ist_Wert 500;
BA_ "GenSigTimeoutMsg_Teves_MK60_ESP" SG_ 714 QS2_Ist_Wert 714;
BA_ "GenSigSendType" SG_ 714 QS2_Ist_Wert 0;
BA_ "GenSigTimeoutTime_Teves_MK60_ESP" SG_ 714 QS2_Gleichlauf 500;
BA_ "GenSigTimeoutMsg_Teves_MK60_ESP" SG_ 714 QS2_Gleichlauf 714;
BA_ "GenSigSendType" SG_ 714 QS2_Gleichlauf 0;
BA_ "GenSigTimeoutTime_Gateway_PQ35_A" SG_ 714 QS2_KD_Fehler 500;
BA_ "GenSigTimeoutMsg_Gateway_PQ35_A" SG_ 714 QS2_KD_Fehler 714;
BA_ "GenSigSendType" SG_ 714 QS2_KD_Fehler 0;
BA_ "GenSigTimeoutTime_Teves_MK60_ESP" SG_ 714 QS2_Soll_Wert 500;
BA_ "GenSigTimeoutMsg_Teves_MK60_ESP" SG_ 714 QS2_Soll_Wert 714;
BA_ "GenSigSendType" SG_ 714 QS2_Soll_Wert 0;
BA_ "GenSigSendType" SG_ 714 QS2_res_26 0;
BA_ "GenSigTimeoutTime_Teves_MK60_ESP" SG_ 714 QS2_Status_VAQ 500;
BA_ "GenSigTimeoutMsg_Teves_MK60_ESP" SG_ 714 QS2_Status_VAQ 714;
BA_ "GenSigSendType" SG_ 714 QS2_Status_VAQ 0;
BA_ "GenSigTimeoutMsg_Gateway_PQ35_A" SG_ 536 Quersperre_TP_Er 536;
BA_ "GenSigSendType" SG_ 536 Quersperre_TP_Er 5;
BA_ "GenSigSendType" SG_ 1404 BY1_KD_Fehler 0;
BA_ "GenSigSendType" SG_ 1404 BY1_res_01 0;
BA_ "GenSigSendType" SG_ 1404 BY1_res_02 0;
BA_ "GenSigSendType" SG_ 1404 BY1_res_03 0;
BA_ "GenSigSendType" SG_ 1404 BY1_res_04 0;
BA_ "GenSigSendType" SG_ 1404 BY1_res_05 0;
BA_ "GenSigSendType" SG_ 1404 BY1_res_06 0;
BA_ "GenSigSendType" SG_ 1404 BY1_res_07 0;
BA_ "GenSigSendType" SG_ 1406 EY1_KD_Fehler 0;
BA_ "GenSigSendType" SG_ 1406 EY1_res_01 0;
BA_ "GenSigSendType" SG_ 1406 EY1_res_02 0;
BA_ "GenSigSendType" SG_ 1406 EY1_res_03 0;
BA_ "GenSigSendType" SG_ 1406 EY1_res_04 0;
BA_ "GenSigSendType" SG_ 1406 EY1_res_05 0;
BA_ "GenSigSendType" SG_ 1406 EY1_res_07 0;
BA_ "GenSigSendType" SG_ 1406 EY1_res_06 0;
BA_ "GenSigTimeoutTime_Waehlhebel" SG_ 1352 GE4_Shiftlock 500;
BA_ "GenSigTimeoutMsg_Waehlhebel" SG_ 1352 GE4_Shiftlock 1352;
BA_ "GenSigSendType" SG_ 1352 GE4_Shiftlock 0;
BA_ "GenSigStartValue" SG_ 1352 GE4_Shiftlock 1;
BA_ "GenSigTimeoutTime_Waehlhebel" SG_ 1352 GE4_Ausleuchtung 500;
BA_ "GenSigTimeoutMsg_Waehlhebel" SG_ 1352 GE4_Ausleuchtung 1352;
BA_ "GenSigSendType" SG_ 1352 GE4_Ausleuchtung 0;
BA_ "GenSigTimeoutTime_Waehlhebel" SG_ 1352 GE4_AuslModus 500;
BA_ "GenSigTimeoutMsg_Waehlhebel" SG_ 1352 GE4_AuslModus 1352;
BA_ "GenSigSendType" SG_ 1352 GE4_AuslModus 0;
BA_ "GenSigSendType" SG_ 1352 GE4_res_03 0;
BA_ "GenSigTimeoutTime_Waehlhebel" SG_ 1352 GE4_Testparam_1 500;
BA_ "GenSigTimeoutMsg_Waehlhebel" SG_ 1352 GE4_Testparam_1 1352;
BA_ "GenSigSendType" SG_ 1352 GE4_Testparam_1 0;
BA_ "GenSigTimeoutTime_Waehlhebel" SG_ 1352 GE4_Testparam_2 500;
BA_ "GenSigTimeoutMsg_Waehlhebel" SG_ 1352 GE4_Testparam_2 1352;
BA_ "GenSigSendType" SG_ 1352 GE4_Testparam_2 0;
BA_ "GenSigTimeoutTime_Waehlhebel" SG_ 1352 GE4_Test 500;
BA_ "GenSigTimeoutMsg_Waehlhebel" SG_ 1352 GE4_Test 1352;
BA_ "GenSigSendType" SG_ 1352 GE4_Test 0;
BA_ "GenSigTimeoutTime_Hybrid_MSG" SG_ 1106 GH1_FreigabeVMStop 500;
BA_ "GenSigTimeoutMsg_Hybrid_MSG" SG_ 1106 GH1_FreigabeVMStop 1106;
BA_ "GenSigSendType" SG_ 1106 GH1_FreigabeVMStop 0;
BA_ "GenSigTimeoutTime_Hybrid_MSG" SG_ 1106 GH1_Zaehler 500;
BA_ "GenSigTimeoutMsg_Hybrid_MSG" SG_ 1106 GH1_Zaehler 1106;
BA_ "GenSigSendType" SG_ 1106 GH1_Zaehler 0;
BA_ "GenSigTimeoutTime_Hybrid_MSG" SG_ 1106 GH1_FreigabeK0 500;
BA_ "GenSigTimeoutMsg_Hybrid_MSG" SG_ 1106 GH1_FreigabeK0 1106;
BA_ "GenSigSendType" SG_ 1106 GH1_FreigabeK0 0;
BA_ "GenSigTimeoutTime_Hybrid_MSG" SG_ 1106 GH1_nK0 500;
BA_ "GenSigTimeoutMsg_Hybrid_MSG" SG_ 1106 GH1_nK0 1106;
BA_ "GenSigSendType" SG_ 1106 GH1_nK0 0;
BA_ "GenSigTimeoutTime_Hybrid_PWR" SG_ 1106 GH1_MomEingriff_EM 500;
BA_ "GenSigTimeoutMsg_Hybrid_PWR" SG_ 1106 GH1_MomEingriff_EM 1106;
BA_ "GenSigSendType" SG_ 1106 GH1_MomEingriff_EM 0;
BA_ "GenSigTimeoutTime_Hybrid_MSG" SG_ 1106 GH1_FehlerstatusGSG 500;
BA_ "GenSigTimeoutMsg_Hybrid_MSG" SG_ 1106 GH1_FehlerstatusGSG 1106;
BA_ "GenSigSendType" SG_ 1106 GH1_FehlerstatusGSG 0;
BA_ "GenSigTimeoutTime_Hybrid_MSG" SG_ 1106 GH1_Wiederstart 500;
BA_ "GenSigTimeoutMsg_Hybrid_MSG" SG_ 1106 GH1_Wiederstart 1106;
BA_ "GenSigSendType" SG_ 1106 GH1_Wiederstart 0;
BA_ "GenSigTimeoutTime_Hybrid_PWR" SG_ 1106 GH1_VZMomEingriff 500;
BA_ "GenSigTimeoutMsg_Hybrid_PWR" SG_ 1106 GH1_VZMomEingriff 1106;
BA_ "GenSigTimeoutTime_Hybrid_MSG" SG_ 1106 GH1_VZMomEingriff 500;
BA_ "GenSigTimeoutMsg_Hybrid_MSG" SG_ 1106 GH1_VZMomEingriff 1106;
BA_ "GenSigSendType" SG_ 1106 GH1_VZMomEingriff 0;
BA_ "GenSigTimeoutTime_Hybrid_MSG" SG_ 1106 GH1_Sportfaktor 500;
BA_ "GenSigTimeoutMsg_Hybrid_MSG" SG_ 1106 GH1_Sportfaktor 1106;
BA_ "GenSigSendType" SG_ 1106 GH1_Sportfaktor 0;
BA_ "GenSigTimeoutTime_Hybrid_MSG" SG_ 1106 GH1_Freig_LL_Reg 500;
BA_ "GenSigTimeoutMsg_Hybrid_MSG" SG_ 1106 GH1_Freig_LL_Reg 1106;
BA_ "GenSigSendType" SG_ 1106 GH1_Freig_LL_Reg 0;
BA_ "GenSigStartValue" SG_ 1106 GH1_Freig_LL_Reg 1;
BA_ "GenSigTimeoutTime_Hybrid_MSG" SG_ 1106 GH1_VM_akt_halten 500;
BA_ "GenSigTimeoutMsg_Hybrid_MSG" SG_ 1106 GH1_VM_akt_halten 1106;
BA_ "GenSigSendType" SG_ 1106 GH1_VM_akt_halten 0;
BA_ "GenSigTimeoutTime_Hybrid_MSG" SG_ 1106 GH1_VKM_StKontr 500;
BA_ "GenSigTimeoutMsg_Hybrid_MSG" SG_ 1106 GH1_VKM_StKontr 1106;
BA_ "GenSigSendType" SG_ 1106 GH1_VKM_StKontr 0;
BA_ "GenSigTimeoutTime_Hybrid_MSG" SG_ 1106 GH1_VKM_StAnf 500;
BA_ "GenSigTimeoutMsg_Hybrid_MSG" SG_ 1106 GH1_VKM_StAnf 1106;
BA_ "GenSigSendType" SG_ 1106 GH1_VKM_StAnf 0;
BA_ "GenSigTimeoutMsg_Gateway_PQ46_A" SG_ 2025 ISO_Getriebe_01_Resp_Data 2025;
BA_ "GenSigTimeoutMsg_Gateway_PQ35_A" SG_ 2025 ISO_Getriebe_01_Resp_Data 2025;
BA_ "GenSigSendType" SG_ 1090 GM3_QB_LangEingr 0;
BA_ "GenSigStartValue" SG_ 1090 GM3_QB_LangEingr 1;
BA_ "GenSigSendType" SG_ 1090 GM3_Moment 0;
BA_ "GenSigStartValue" SG_ 1090 GM3_Moment 1023;
BA_ "GenSigSendType" SG_ 1090 GM3_Checksum 0;
BA_ "INIT" SG_ 1090 GM3_Checksum "CHK";
BA_ "GenSigSendType" SG_ 1090 GM3_res_13 0;
BA_ "GenSigSendType" SG_ 1090 GM3_res_15 0;
BA_ "GenSigTimeoutTime_Hybrid_MSG" SG_ 1090 GM3_MoSoMom 500;
BA_ "GenSigTimeoutMsg_Hybrid_MSG" SG_ 1090 GM3_MoSoMom 1090;
BA_ "GenSigSendType" SG_ 1090 GM3_MoSoMom 0;
BA_ "GenSigStartValue" SG_ 1090 GM3_MoSoMom 1022;
BA_ "GenSigSendType" SG_ 1090 GM3_MomID 0;
BA_ "GenSigTimeoutTime_Hybrid_MSG" SG_ 1090 GM3_MomEingr 500;
BA_ "GenSigTimeoutMsg_Hybrid_MSG" SG_ 1090 GM3_MomEingr 1090;
BA_ "GenSigSendType" SG_ 1090 GM3_MomEingr 0;
BA_ "GenSigSendType" SG_ 1090 GM3_StaSoMom 0;
BA_ "GenSigSendType" SG_ 1090 GM3_Zaehler 0;
BA_ "GenSigSendType" SG_ 1090 GM3_res_61 0;
BA_ "GenSigSendType" SG_ 1090 GM3_res_14 0;
BA_ "GenSigSendType" SG_ 1090 GM3_LangEingr 0;
BA_ "GenSigStartValue" SG_ 1090 GM3_LangEingr 1022;
BA_ "GenSigSendType" SG_ 1090 GM3_res_63 0;
BA_ "GenSigSendType" SG_ 1090 GM3_Zeit 0;
BA_ "GenSigSendType" SG_ 1090 GM3_res_62 0;
BA_ "GenSigTimeoutTime_Gateway_PQ46_A" SG_ 1526 EK1_Comp_main_stat 5000;
BA_ "GenSigTimeoutMsg_Gateway_PQ46_A" SG_ 1526 EK1_Comp_main_stat 1526;
BA_ "GenSigTimeoutTime_Gateway_PQ35_A" SG_ 1526 EK1_Comp_main_stat 5000;
BA_ "GenSigTimeoutMsg_Gateway_PQ35_A" SG_ 1526 EK1_Comp_main_stat 1526;
BA_ "GenSigSendType" SG_ 1526 EK1_Comp_main_stat 0;
BA_ "GenSigTimeoutTime_Gateway_PQ35_A" SG_ 1526 EK1_Comp_ovld_stat 5000;
BA_ "GenSigTimeoutMsg_Gateway_PQ35_A" SG_ 1526 EK1_Comp_ovld_stat 1526;
BA_ "GenSigTimeoutTime_Gateway_PQ46_A" SG_ 1526 EK1_Comp_ovld_stat 5000;
BA_ "GenSigTimeoutMsg_Gateway_PQ46_A" SG_ 1526 EK1_Comp_ovld_stat 1526;
BA_ "GenSigSendType" SG_ 1526 EK1_Comp_ovld_stat 0;
BA_ "GenSigTimeoutTime_Gateway_PQ35_A" SG_ 1526 EK1_Comp_output_stat 5000;
BA_ "GenSigTimeoutMsg_Gateway_PQ35_A" SG_ 1526 EK1_Comp_output_stat 1526;
BA_ "GenSigTimeoutTime_Gateway_PQ46_A" SG_ 1526 EK1_Comp_output_stat 5000;
BA_ "GenSigTimeoutMsg_Gateway_PQ46_A" SG_ 1526 EK1_Comp_output_stat 1526;
BA_ "GenSigSendType" SG_ 1526 EK1_Comp_output_stat 0;
BA_ "GenSigTimeoutTime_Gateway_PQ35_A" SG_ 1526 EK1_res_08 5000;
BA_ "GenSigTimeoutMsg_Gateway_PQ35_A" SG_ 1526 EK1_res_08 1526;
BA_ "GenSigTimeoutTime_Gateway_PQ46_A" SG_ 1526 EK1_res_08 5000;
BA_ "GenSigTimeoutMsg_Gateway_PQ46_A" SG_ 1526 EK1_res_08 1526;
BA_ "GenSigSendType" SG_ 1526 EK1_res_08 0;
BA_ "GenSigTimeoutTime_Gateway_PQ35_A" SG_ 1526 EK1_Comp_photo_temp_stat 5000;
BA_ "GenSigTimeoutMsg_Gateway_PQ35_A" SG_ 1526 EK1_Comp_photo_temp_stat 1526;
BA_ "GenSigTimeoutTime_Gateway_PQ46_A" SG_ 1526 EK1_Comp_photo_temp_stat 5000;
BA_ "GenSigTimeoutMsg_Gateway_PQ46_A" SG_ 1526 EK1_Comp_photo_temp_stat 1526;
BA_ "GenSigSendType" SG_ 1526 EK1_Comp_photo_temp_stat 0;
BA_ "GenSigTimeoutTime_Gateway_PQ35_A" SG_ 1526 EK1_Comp_Inv_stat 5000;
BA_ "GenSigTimeoutMsg_Gateway_PQ35_A" SG_ 1526 EK1_Comp_Inv_stat 1526;
BA_ "GenSigTimeoutTime_Gateway_PQ46_A" SG_ 1526 EK1_Comp_Inv_stat 5000;
BA_ "GenSigTimeoutMsg_Gateway_PQ46_A" SG_ 1526 EK1_Comp_Inv_stat 1526;
BA_ "GenSigSendType" SG_ 1526 EK1_Comp_Inv_stat 0;
BA_ "GenSigTimeoutTime_Gateway_PQ35_A" SG_ 1526 EK1_KD_Fehler 5000;
BA_ "GenSigTimeoutMsg_Gateway_PQ35_A" SG_ 1526 EK1_KD_Fehler 1526;
BA_ "GenSigTimeoutTime_Gateway_PQ46_A" SG_ 1526 EK1_KD_Fehler 5000;
BA_ "GenSigTimeoutMsg_Gateway_PQ46_A" SG_ 1526 EK1_KD_Fehler 1526;
BA_ "GenSigSendType" SG_ 1526 EK1_KD_Fehler 0;
BA_ "GenSigTimeoutTime_Gateway_PQ35_A" SG_ 1526 EK1_Comp_rev_stat 5000;
BA_ "GenSigTimeoutMsg_Gateway_PQ35_A" SG_ 1526 EK1_Comp_rev_stat 1526;
BA_ "GenSigTimeoutTime_Gateway_PQ46_A" SG_ 1526 EK1_Comp_rev_stat 5000;
BA_ "GenSigTimeoutMsg_Gateway_PQ46_A" SG_ 1526 EK1_Comp_rev_stat 1526;
BA_ "GenSigSendType" SG_ 1526 EK1_Comp_rev_stat 0;
BA_ "GenSigTimeoutTime_Gateway_PQ35_A" SG_ 1526 EK1_Comp_SCI_com_stat 5000;
BA_ "GenSigTimeoutMsg_Gateway_PQ35_A" SG_ 1526 EK1_Comp_SCI_com_stat 1526;
BA_ "GenSigTimeoutTime_Gateway_PQ46_A" SG_ 1526 EK1_Comp_SCI_com_stat 5000;
BA_ "GenSigTimeoutMsg_Gateway_PQ46_A" SG_ 1526 EK1_Comp_SCI_com_stat 1526;
BA_ "GenSigSendType" SG_ 1526 EK1_Comp_SCI_com_stat 0;
BA_ "GenSigTimeoutTime_Gateway_PQ35_A" SG_ 1526 EK1_Comp_current 5000;
BA_ "GenSigTimeoutMsg_Gateway_PQ35_A" SG_ 1526 EK1_Comp_current 1526;
BA_ "GenSigTimeoutTime_Gateway_PQ46_A" SG_ 1526 EK1_Comp_current 5000;
BA_ "GenSigTimeoutMsg_Gateway_PQ46_A" SG_ 1526 EK1_Comp_current 1526;
BA_ "GenSigTimeoutTime_Hybrid_MSG" SG_ 1526 EK1_Comp_current 5000;
BA_ "GenSigTimeoutMsg_Hybrid_MSG" SG_ 1526 EK1_Comp_current 1526;
BA_ "GenSigSendType" SG_ 1526 EK1_Comp_current 0;
BA_ "GenSigStartValue" SG_ 1526 EK1_Comp_current 255;
BA_ "GenSigTimeoutTime_Gateway_PQ35_A" SG_ 1526 EK1_Comp_photo_temp 5000;
BA_ "GenSigTimeoutMsg_Gateway_PQ35_A" SG_ 1526 EK1_Comp_photo_temp 1526;
BA_ "GenSigTimeoutTime_Gateway_PQ46_A" SG_ 1526 EK1_Comp_photo_temp 5000;
BA_ "GenSigTimeoutMsg_Gateway_PQ46_A" SG_ 1526 EK1_Comp_photo_temp 1526;
BA_ "GenSigSendType" SG_ 1526 EK1_Comp_photo_temp 0;
BA_ "GenSigStartValue" SG_ 1526 EK1_Comp_photo_temp 255;
BA_ "GenSigTimeoutTime_Gateway_PQ35_A" SG_ 1526 EK1_res_40 5000;
BA_ "GenSigTimeoutMsg_Gateway_PQ35_A" SG_ 1526 EK1_res_40 1526;
BA_ "GenSigTimeoutTime_Gateway_PQ46_A" SG_ 1526 EK1_res_40 5000;
BA_ "GenSigTimeoutMsg_Gateway_PQ46_A" SG_ 1526 EK1_res_40 1526;
BA_ "GenSigSendType" SG_ 1526 EK1_res_40 0;
BA_ "GenSigTimeoutTime_Gateway_PQ35_A" SG_ 1526 EK1_res_14 5000;
BA_ "GenSigTimeoutMsg_Gateway_PQ35_A" SG_ 1526 EK1_res_14 1526;
BA_ "GenSigTimeoutTime_Gateway_PQ46_A" SG_ 1526 EK1_res_14 5000;
BA_ "GenSigTimeoutMsg_Gateway_PQ46_A" SG_ 1526 EK1_res_14 1526;
BA_ "GenSigSendType" SG_ 1526 EK1_res_14 0;
BA_ "GenSigTimeoutMsg_Gateway_PQ35_A" SG_ 1650 BAP_var_SWA 1650;
BA_ "GenSigTimeoutMsg_Gateway_PQ46_A" SG_ 1650 BAP_var_SWA 1650;
BA_ "GenSigTimeoutMsg_Gateway_PQ46_A" SG_ 1650 BAP_Data_SWA 1650;
BA_ "GenSigTimeoutMsg_Gateway_PQ35_A" SG_ 1650 BAP_Data_SWA 1650;
BA_ "GenSigTimeoutTime_Gateway_PQ46_A" SG_ 954 SWA_Gong 500;
BA_ "GenSigTimeoutMsg_Gateway_PQ46_A" SG_ 954 SWA_Gong 954;
BA_ "GenSigTimeoutTime_Gateway_PQ35_A" SG_ 954 SWA_Gong 500;
BA_ "GenSigTimeoutMsg_Gateway_PQ35_A" SG_ 954 SWA_Gong 954;
BA_ "GenSigSendType" SG_ 954 SWA_Gong 0;
BA_ "GenSigTimeoutTime_Gateway_PQ46_A" SG_ 954 SWA_Textbits 500;
BA_ "GenSigTimeoutMsg_Gateway_PQ46_A" SG_ 954 SWA_Textbits 954;
BA_ "GenSigTimeoutTime_Gateway_PQ35_A" SG_ 954 SWA_Textbits 500;
BA_ "GenSigTimeoutMsg_Gateway_PQ35_A" SG_ 954 SWA_Textbits 954;
BA_ "GenSigSendType" SG_ 954 SWA_Textbits 0;
BA_ "GenSigTimeoutTime_Gateway_PQ46_A" SG_ 954 SWA_Sta_passiv 500;
BA_ "GenSigTimeoutMsg_Gateway_PQ46_A" SG_ 954 SWA_Sta_passiv 954;
BA_ "GenSigTimeoutTime_Gateway_PQ35_A" SG_ 954 SWA_Sta_passiv 500;
BA_ "GenSigTimeoutMsg_Gateway_PQ35_A" SG_ 954 SWA_Sta_passiv 954;
BA_ "GenSigSendType" SG_ 954 SWA_Sta_passiv 0;
BA_ "GenSigTimeoutTime_Gateway_PQ46_A" SG_ 954 SWA_KD_Fehler 500;
BA_ "GenSigTimeoutMsg_Gateway_PQ46_A" SG_ 954 SWA_KD_Fehler 954;
BA_ "GenSigTimeoutTime_Gateway_PQ35_A" SG_ 954 SWA_KD_Fehler 500;
BA_ "GenSigTimeoutMsg_Gateway_PQ35_A" SG_ 954 SWA_KD_Fehler 954;
BA_ "GenSigSendType" SG_ 954 SWA_KD_Fehler 0;
BA_ "GenSigTimeoutTime_Gateway_PQ35_A" SG_ 954 SWA_res_00 500;
BA_ "GenSigTimeoutMsg_Gateway_PQ35_A" SG_ 954 SWA_res_00 954;
BA_ "GenSigTimeoutTime_Gateway_PQ46_A" SG_ 954 SWA_res_00 500;
BA_ "GenSigTimeoutMsg_Gateway_PQ46_A" SG_ 954 SWA_res_00 954;
BA_ "GenSigSendType" SG_ 954 SWA_res_00 0;
BA_ "GenSigTimeoutTime_Gateway_PQ35_A" SG_ 954 SWA_res_01 500;
BA_ "GenSigTimeoutMsg_Gateway_PQ35_A" SG_ 954 SWA_res_01 954;
BA_ "GenSigTimeoutTime_Gateway_PQ46_A" SG_ 954 SWA_res_01 500;
BA_ "GenSigTimeoutMsg_Gateway_PQ46_A" SG_ 954 SWA_res_01 954;
BA_ "GenSigSendType" SG_ 954 SWA_res_01 0;
BA_ "GenSigTimeoutTime_Gateway_PQ35_A" SG_ 954 SWA_res_02 500;
BA_ "GenSigTimeoutMsg_Gateway_PQ35_A" SG_ 954 SWA_res_02 954;
BA_ "GenSigTimeoutTime_Gateway_PQ46_A" SG_ 954 SWA_res_02 500;
BA_ "GenSigTimeoutMsg_Gateway_PQ46_A" SG_ 954 SWA_res_02 954;
BA_ "GenSigSendType" SG_ 954 SWA_res_02 0;
BA_ "GenSigTimeoutTime_Gateway_PQ35_A" SG_ 954 SWA_res_03 500;
BA_ "GenSigTimeoutMsg_Gateway_PQ35_A" SG_ 954 SWA_res_03 954;
BA_ "GenSigTimeoutTime_Gateway_PQ46_A" SG_ 954 SWA_res_03 500;
BA_ "GenSigTimeoutMsg_Gateway_PQ46_A" SG_ 954 SWA_res_03 954;
BA_ "GenSigSendType" SG_ 954 SWA_res_03 0;
BA_ "GenSigTimeoutTime_Gateway_PQ35_A" SG_ 954 SWA_res_06 500;
BA_ "GenSigTimeoutMsg_Gateway_PQ35_A" SG_ 954 SWA_res_06 954;
BA_ "GenSigTimeoutTime_Gateway_PQ46_A" SG_ 954 SWA_res_06 500;
BA_ "GenSigTimeoutMsg_Gateway_PQ46_A" SG_ 954 SWA_res_06 954;
BA_ "GenSigSendType" SG_ 954 SWA_res_06 0;
BA_ "GenSigTimeoutTime_Gateway_PQ35_A" SG_ 954 SWA_res_07 500;
BA_ "GenSigTimeoutMsg_Gateway_PQ35_A" SG_ 954 SWA_res_07 954;
BA_ "GenSigTimeoutTime_Gateway_PQ46_A" SG_ 954 SWA_res_07 500;
BA_ "GenSigTimeoutMsg_Gateway_PQ46_A" SG_ 954 SWA_res_07 954;
BA_ "GenSigSendType" SG_ 954 SWA_res_07 0;
BA_ "GenSigTimeoutTime_Gateway_PQ46_A" SG_ 954 SWA_Sta_aktiv 500;
BA_ "GenSigTimeoutMsg_Gateway_PQ46_A" SG_ 954 SWA_Sta_aktiv 954;
BA_ "GenSigTimeoutTime_Gateway_PQ35_A" SG_ 954 SWA_Sta_aktiv 500;
BA_ "GenSigTimeoutMsg_Gateway_PQ35_A" SG_ 954 SWA_Sta_aktiv 954;
BA_ "GenSigSendType" SG_ 954 SWA_Sta_aktiv 0;
BA_ "GenSigTimeoutTime_Gateway_PQ35_A" SG_ 954 SWA_res_04 500;
BA_ "GenSigTimeoutMsg_Gateway_PQ35_A" SG_ 954 SWA_res_04 954;
BA_ "GenSigTimeoutTime_Gateway_PQ46_A" SG_ 954 SWA_res_04 500;
BA_ "GenSigTimeoutMsg_Gateway_PQ46_A" SG_ 954 SWA_res_04 954;
BA_ "GenSigSendType" SG_ 954 SWA_res_04 0;
BA_ "GenSigTimeoutTime_Gateway_PQ35_A" SG_ 954 SWA_res_05 500;
BA_ "GenSigTimeoutMsg_Gateway_PQ35_A" SG_ 954 SWA_res_05 954;
BA_ "GenSigTimeoutTime_Gateway_PQ46_A" SG_ 954 SWA_res_05 500;
BA_ "GenSigTimeoutMsg_Gateway_PQ46_A" SG_ 954 SWA_res_05 954;
BA_ "GenSigSendType" SG_ 954 SWA_res_05 0;
BA_ "GenSigTimeoutTime_Gateway_PQ35_A" SG_ 954 SWA_res_08 500;
BA_ "GenSigTimeoutMsg_Gateway_PQ35_A" SG_ 954 SWA_res_08 954;
BA_ "GenSigTimeoutTime_Gateway_PQ46_A" SG_ 954 SWA_res_08 500;
BA_ "GenSigTimeoutMsg_Gateway_PQ46_A" SG_ 954 SWA_res_08 954;
BA_ "GenSigSendType" SG_ 954 SWA_res_08 0;
BA_ "GenSigTimeoutTime_Gateway_PQ35_A" SG_ 954 SWA_res_09 500;
BA_ "GenSigTimeoutMsg_Gateway_PQ35_A" SG_ 954 SWA_res_09 954;
BA_ "GenSigTimeoutTime_Gateway_PQ46_A" SG_ 954 SWA_res_09 500;
BA_ "GenSigTimeoutMsg_Gateway_PQ46_A" SG_ 954 SWA_res_09 954;
BA_ "GenSigSendType" SG_ 954 SWA_res_09 0;
BA_ "GenSigTimeoutTime_Gateway_PQ35_A" SG_ 954 SWA_res_10 500;
BA_ "GenSigTimeoutMsg_Gateway_PQ35_A" SG_ 954 SWA_res_10 954;
BA_ "GenSigTimeoutTime_Gateway_PQ46_A" SG_ 954 SWA_res_10 500;
BA_ "GenSigTimeoutMsg_Gateway_PQ46_A" SG_ 954 SWA_res_10 954;
BA_ "GenSigSendType" SG_ 954 SWA_res_10 0;
BA_ "GenSigTimeoutTime_Gateway_PQ35_A" SG_ 954 SWA_res_11 500;
BA_ "GenSigTimeoutMsg_Gateway_PQ35_A" SG_ 954 SWA_res_11 954;
BA_ "GenSigTimeoutTime_Gateway_PQ46_A" SG_ 954 SWA_res_11 500;
BA_ "GenSigTimeoutMsg_Gateway_PQ46_A" SG_ 954 SWA_res_11 954;
BA_ "GenSigSendType" SG_ 954 SWA_res_11 0;
BA_ "GenSigTimeoutTime_Gateway_PQ35_A" SG_ 954 SWA_res_21 500;
BA_ "GenSigTimeoutMsg_Gateway_PQ35_A" SG_ 954 SWA_res_21 954;
BA_ "GenSigTimeoutTime_Gateway_PQ46_A" SG_ 954 SWA_res_21 500;
BA_ "GenSigTimeoutMsg_Gateway_PQ46_A" SG_ 954 SWA_res_21 954;
BA_ "GenSigSendType" SG_ 954 SWA_res_21 0;
BA_ "GenSigTimeoutTime_Gateway_PQ35_A" SG_ 954 SWA_res_22 500;
BA_ "GenSigTimeoutMsg_Gateway_PQ35_A" SG_ 954 SWA_res_22 954;
BA_ "GenSigTimeoutTime_Gateway_PQ46_A" SG_ 954 SWA_res_22 500;
BA_ "GenSigTimeoutMsg_Gateway_PQ46_A" SG_ 954 SWA_res_22 954;
BA_ "GenSigSendType" SG_ 954 SWA_res_22 0;
BA_ "GenSigTimeoutTime_Gateway_PQ35_A" SG_ 954 SWA_res_23 500;
BA_ "GenSigTimeoutMsg_Gateway_PQ35_A" SG_ 954 SWA_res_23 954;
BA_ "GenSigTimeoutTime_Gateway_PQ46_A" SG_ 954 SWA_res_23 500;
BA_ "GenSigTimeoutMsg_Gateway_PQ46_A" SG_ 954 SWA_res_23 954;
BA_ "GenSigSendType" SG_ 954 SWA_res_23 0;
BA_ "GenSigTimeoutTime_Gateway_PQ35_A" SG_ 954 SWA_res_18 500;
BA_ "GenSigTimeoutMsg_Gateway_PQ35_A" SG_ 954 SWA_res_18 954;
BA_ "GenSigTimeoutTime_Gateway_PQ46_A" SG_ 954 SWA_res_18 500;
BA_ "GenSigTimeoutMsg_Gateway_PQ46_A" SG_ 954 SWA_res_18 954;
BA_ "GenSigSendType" SG_ 954 SWA_res_18 0;
BA_ "GenSigTimeoutTime_Gateway_PQ35_A" SG_ 954 SWA_res_24 500;
BA_ "GenSigTimeoutMsg_Gateway_PQ35_A" SG_ 954 SWA_res_24 954;
BA_ "GenSigTimeoutTime_Gateway_PQ46_A" SG_ 954 SWA_res_24 500;
BA_ "GenSigTimeoutMsg_Gateway_PQ46_A" SG_ 954 SWA_res_24 954;
BA_ "GenSigSendType" SG_ 954 SWA_res_24 0;
BA_ "GenSigTimeoutTime_Gateway_PQ35_A" SG_ 954 SWA_res_25 500;
BA_ "GenSigTimeoutMsg_Gateway_PQ35_A" SG_ 954 SWA_res_25 954;
BA_ "GenSigTimeoutTime_Gateway_PQ46_A" SG_ 954 SWA_res_25 500;
BA_ "GenSigTimeoutMsg_Gateway_PQ46_A" SG_ 954 SWA_res_25 954;
BA_ "GenSigSendType" SG_ 954 SWA_res_25 0;
BA_ "GenSigTimeoutTime_Gateway_PQ35_A" SG_ 954 SWA_res_26 500;
BA_ "GenSigTimeoutMsg_Gateway_PQ35_A" SG_ 954 SWA_res_26 954;
BA_ "GenSigTimeoutTime_Gateway_PQ46_A" SG_ 954 SWA_res_26 500;
BA_ "GenSigTimeoutMsg_Gateway_PQ46_A" SG_ 954 SWA_res_26 954;
BA_ "GenSigSendType" SG_ 954 SWA_res_26 0;
BA_ "GenSigTimeoutTime_Gateway_PQ35_A" SG_ 954 SWA_res_27 500;
BA_ "GenSigTimeoutMsg_Gateway_PQ35_A" SG_ 954 SWA_res_27 954;
BA_ "GenSigTimeoutTime_Gateway_PQ46_A" SG_ 954 SWA_res_27 500;
BA_ "GenSigTimeoutMsg_Gateway_PQ46_A" SG_ 954 SWA_res_27 954;
BA_ "GenSigSendType" SG_ 954 SWA_res_27 0;
BA_ "GenSigTimeoutTime_Gateway_PQ35_A" SG_ 954 SWA_res_28 500;
BA_ "GenSigTimeoutMsg_Gateway_PQ35_A" SG_ 954 SWA_res_28 954;
BA_ "GenSigTimeoutTime_Gateway_PQ46_A" SG_ 954 SWA_res_28 500;
BA_ "GenSigTimeoutMsg_Gateway_PQ46_A" SG_ 954 SWA_res_28 954;
BA_ "GenSigSendType" SG_ 954 SWA_res_28 0;
BA_ "GenSigTimeoutTime_Gateway_PQ35_A" SG_ 954 SWA_res_30 500;
BA_ "GenSigTimeoutMsg_Gateway_PQ35_A" SG_ 954 SWA_res_30 954;
BA_ "GenSigTimeoutTime_Gateway_PQ46_A" SG_ 954 SWA_res_30 500;
BA_ "GenSigTimeoutMsg_Gateway_PQ46_A" SG_ 954 SWA_res_30 954;
BA_ "GenSigSendType" SG_ 954 SWA_res_30 0;
BA_ "GenSigTimeoutTime_Gateway_PQ35_A" SG_ 954 SWA_res_31 500;
BA_ "GenSigTimeoutMsg_Gateway_PQ35_A" SG_ 954 SWA_res_31 954;
BA_ "GenSigTimeoutTime_Gateway_PQ46_A" SG_ 954 SWA_res_31 500;
BA_ "GenSigTimeoutMsg_Gateway_PQ46_A" SG_ 954 SWA_res_31 954;
BA_ "GenSigSendType" SG_ 954 SWA_res_31 0;
BA_ "GenSigTimeoutTime_Gateway_PQ35_A" SG_ 954 SWA_res_32 500;
BA_ "GenSigTimeoutMsg_Gateway_PQ35_A" SG_ 954 SWA_res_32 954;
BA_ "GenSigTimeoutTime_Gateway_PQ46_A" SG_ 954 SWA_res_32 500;
BA_ "GenSigTimeoutMsg_Gateway_PQ46_A" SG_ 954 SWA_res_32 954;
BA_ "GenSigSendType" SG_ 954 SWA_res_32 0;
BA_ "GenSigTimeoutTime_Gateway_PQ35_A" SG_ 954 SWA_res_29 500;
BA_ "GenSigTimeoutMsg_Gateway_PQ35_A" SG_ 954 SWA_res_29 954;
BA_ "GenSigTimeoutTime_Gateway_PQ46_A" SG_ 954 SWA_res_29 500;
BA_ "GenSigTimeoutMsg_Gateway_PQ46_A" SG_ 954 SWA_res_29 954;
BA_ "GenSigSendType" SG_ 954 SWA_res_29 0;
BA_ "GenSigTimeoutTime_Gateway_PQ35_A" SG_ 954 SWA_res_33 500;
BA_ "GenSigTimeoutMsg_Gateway_PQ35_A" SG_ 954 SWA_res_33 954;
BA_ "GenSigTimeoutTime_Gateway_PQ46_A" SG_ 954 SWA_res_33 500;
BA_ "GenSigTimeoutMsg_Gateway_PQ46_A" SG_ 954 SWA_res_33 954;
BA_ "GenSigSendType" SG_ 954 SWA_res_33 0;
BA_ "GenSigTimeoutTime_Gateway_PQ35_A" SG_ 954 SWA_res_34 500;
BA_ "GenSigTimeoutMsg_Gateway_PQ35_A" SG_ 954 SWA_res_34 954;
BA_ "GenSigTimeoutTime_Gateway_PQ46_A" SG_ 954 SWA_res_34 500;
BA_ "GenSigTimeoutMsg_Gateway_PQ46_A" SG_ 954 SWA_res_34 954;
BA_ "GenSigSendType" SG_ 954 SWA_res_34 0;
BA_ "GenSigTimeoutTime_Gateway_PQ35_A" SG_ 954 SWA_res_35 500;
BA_ "GenSigTimeoutMsg_Gateway_PQ35_A" SG_ 954 SWA_res_35 954;
BA_ "GenSigTimeoutTime_Gateway_PQ46_A" SG_ 954 SWA_res_35 500;
BA_ "GenSigTimeoutMsg_Gateway_PQ46_A" SG_ 954 SWA_res_35 954;
BA_ "GenSigSendType" SG_ 954 SWA_res_35 0;
BA_ "GenSigTimeoutTime_Gateway_PQ35_A" SG_ 954 SWA_res_38 500;
BA_ "GenSigTimeoutMsg_Gateway_PQ35_A" SG_ 954 SWA_res_38 954;
BA_ "GenSigTimeoutTime_Gateway_PQ46_A" SG_ 954 SWA_res_38 500;
BA_ "GenSigTimeoutMsg_Gateway_PQ46_A" SG_ 954 SWA_res_38 954;
BA_ "GenSigSendType" SG_ 954 SWA_res_38 0;
BA_ "GenSigTimeoutTime_Gateway_PQ35_A" SG_ 954 SWA_res_39 500;
BA_ "GenSigTimeoutMsg_Gateway_PQ35_A" SG_ 954 SWA_res_39 954;
BA_ "GenSigTimeoutTime_Gateway_PQ46_A" SG_ 954 SWA_res_39 500;
BA_ "GenSigTimeoutMsg_Gateway_PQ46_A" SG_ 954 SWA_res_39 954;
BA_ "GenSigSendType" SG_ 954 SWA_res_39 0;
BA_ "GenSigTimeoutTime_Gateway_PQ35_A" SG_ 954 SWA_res_40 500;
BA_ "GenSigTimeoutMsg_Gateway_PQ35_A" SG_ 954 SWA_res_40 954;
BA_ "GenSigTimeoutTime_Gateway_PQ46_A" SG_ 954 SWA_res_40 500;
BA_ "GenSigTimeoutMsg_Gateway_PQ46_A" SG_ 954 SWA_res_40 954;
BA_ "GenSigSendType" SG_ 954 SWA_res_40 0;
BA_ "GenSigTimeoutTime_Gateway_PQ35_A" SG_ 954 SWA_res_37 500;
BA_ "GenSigTimeoutMsg_Gateway_PQ35_A" SG_ 954 SWA_res_37 954;
BA_ "GenSigTimeoutTime_Gateway_PQ46_A" SG_ 954 SWA_res_37 500;
BA_ "GenSigTimeoutMsg_Gateway_PQ46_A" SG_ 954 SWA_res_37 954;
BA_ "GenSigSendType" SG_ 954 SWA_res_37 0;
BA_ "GenSigTimeoutTime_Gateway_PQ35_A" SG_ 954 SWA_res_41 500;
BA_ "GenSigTimeoutMsg_Gateway_PQ35_A" SG_ 954 SWA_res_41 954;
BA_ "GenSigTimeoutTime_Gateway_PQ46_A" SG_ 954 SWA_res_41 500;
BA_ "GenSigTimeoutMsg_Gateway_PQ46_A" SG_ 954 SWA_res_41 954;
BA_ "GenSigSendType" SG_ 954 SWA_res_41 0;
BA_ "GenSigTimeoutTime_Gateway_PQ35_A" SG_ 954 SWA_res_36 500;
BA_ "GenSigTimeoutMsg_Gateway_PQ35_A" SG_ 954 SWA_res_36 954;
BA_ "GenSigTimeoutTime_Gateway_PQ46_A" SG_ 954 SWA_res_36 500;
BA_ "GenSigTimeoutMsg_Gateway_PQ46_A" SG_ 954 SWA_res_36 954;
BA_ "GenSigSendType" SG_ 954 SWA_res_36 0;
BA_ "GenSigTimeoutTime_Gateway_PQ35_A" SG_ 954 SWA_res_42 500;
BA_ "GenSigTimeoutMsg_Gateway_PQ35_A" SG_ 954 SWA_res_42 954;
BA_ "GenSigTimeoutTime_Gateway_PQ46_A" SG_ 954 SWA_res_42 500;
BA_ "GenSigTimeoutMsg_Gateway_PQ46_A" SG_ 954 SWA_res_42 954;
BA_ "GenSigSendType" SG_ 954 SWA_res_42 0;
BA_ "GenSigTimeoutTime_Gateway_PQ35_A" SG_ 954 SWA_res_43 500;
BA_ "GenSigTimeoutMsg_Gateway_PQ35_A" SG_ 954 SWA_res_43 954;
BA_ "GenSigTimeoutTime_Gateway_PQ46_A" SG_ 954 SWA_res_43 500;
BA_ "GenSigTimeoutMsg_Gateway_PQ46_A" SG_ 954 SWA_res_43 954;
BA_ "GenSigSendType" SG_ 954 SWA_res_43 0;
BA_ "GenSigTimeoutTime_Gateway_PQ35_A" SG_ 954 SWA_res_44 500;
BA_ "GenSigTimeoutMsg_Gateway_PQ35_A" SG_ 954 SWA_res_44 954;
BA_ "GenSigTimeoutTime_Gateway_PQ46_A" SG_ 954 SWA_res_44 500;
BA_ "GenSigTimeoutMsg_Gateway_PQ46_A" SG_ 954 SWA_res_44 954;
BA_ "GenSigSendType" SG_ 954 SWA_res_44 0;
BA_ "GenSigTimeoutTime_Gateway_PQ35_A" SG_ 954 SWA_res_45 500;
BA_ "GenSigTimeoutMsg_Gateway_PQ35_A" SG_ 954 SWA_res_45 954;
BA_ "GenSigTimeoutTime_Gateway_PQ46_A" SG_ 954 SWA_res_45 500;
BA_ "GenSigTimeoutMsg_Gateway_PQ46_A" SG_ 954 SWA_res_45 954;
BA_ "GenSigSendType" SG_ 954 SWA_res_45 0;
BA_ "GenSigTimeoutTime_Gateway_PQ35_A" SG_ 954 SWA_res_47 500;
BA_ "GenSigTimeoutMsg_Gateway_PQ35_A" SG_ 954 SWA_res_47 954;
BA_ "GenSigTimeoutTime_Gateway_PQ46_A" SG_ 954 SWA_res_47 500;
BA_ "GenSigTimeoutMsg_Gateway_PQ46_A" SG_ 954 SWA_res_47 954;
BA_ "GenSigSendType" SG_ 954 SWA_res_47 0;
BA_ "GenSigTimeoutTime_Gateway_PQ35_A" SG_ 954 SWA_res_48 500;
BA_ "GenSigTimeoutMsg_Gateway_PQ35_A" SG_ 954 SWA_res_48 954;
BA_ "GenSigTimeoutTime_Gateway_PQ46_A" SG_ 954 SWA_res_48 500;
BA_ "GenSigTimeoutMsg_Gateway_PQ46_A" SG_ 954 SWA_res_48 954;
BA_ "GenSigSendType" SG_ 954 SWA_res_48 0;
BA_ "GenSigTimeoutTime_Gateway_PQ35_A" SG_ 954 SWA_res_46 500;
BA_ "GenSigTimeoutMsg_Gateway_PQ35_A" SG_ 954 SWA_res_46 954;
BA_ "GenSigTimeoutTime_Gateway_PQ46_A" SG_ 954 SWA_res_46 500;
BA_ "GenSigTimeoutMsg_Gateway_PQ46_A" SG_ 954 SWA_res_46 954;
BA_ "GenSigSendType" SG_ 954 SWA_res_46 0;
BA_ "GenSigTimeoutTime_Gateway_PQ35_A" SG_ 954 SWA_res_50 500;
BA_ "GenSigTimeoutMsg_Gateway_PQ35_A" SG_ 954 SWA_res_50 954;
BA_ "GenSigTimeoutTime_Gateway_PQ46_A" SG_ 954 SWA_res_50 500;
BA_ "GenSigTimeoutMsg_Gateway_PQ46_A" SG_ 954 SWA_res_50 954;
BA_ "GenSigSendType" SG_ 954 SWA_res_50 0;
BA_ "GenSigTimeoutTime_Gateway_PQ35_A" SG_ 954 SWA_res_49 500;
BA_ "GenSigTimeoutMsg_Gateway_PQ35_A" SG_ 954 SWA_res_49 954;
BA_ "GenSigTimeoutTime_Gateway_PQ46_A" SG_ 954 SWA_res_49 500;
BA_ "GenSigTimeoutMsg_Gateway_PQ46_A" SG_ 954 SWA_res_49 954;
BA_ "GenSigSendType" SG_ 954 SWA_res_49 0;
BA_ "GenSigTimeoutTime_Gateway_PQ35_A" SG_ 954 SWA_res_51 500;
BA_ "GenSigTimeoutMsg_Gateway_PQ35_A" SG_ 954 SWA_res_51 954;
BA_ "GenSigTimeoutTime_Gateway_PQ46_A" SG_ 954 SWA_res_51 500;
BA_ "GenSigTimeoutMsg_Gateway_PQ46_A" SG_ 954 SWA_res_51 954;
BA_ "GenSigSendType" SG_ 954 SWA_res_51 0;
BA_ "GenSigTimeoutTime_Gateway_PQ35_A" SG_ 954 SWA_res_52 500;
BA_ "GenSigTimeoutMsg_Gateway_PQ35_A" SG_ 954 SWA_res_52 954;
BA_ "GenSigTimeoutTime_Gateway_PQ46_A" SG_ 954 SWA_res_52 500;
BA_ "GenSigTimeoutMsg_Gateway_PQ46_A" SG_ 954 SWA_res_52 954;
BA_ "GenSigSendType" SG_ 954 SWA_res_52 0;
BA_ "GenSigTimeoutTime_Gateway_PQ35_A" SG_ 954 SWA_res_53 500;
BA_ "GenSigTimeoutMsg_Gateway_PQ35_A" SG_ 954 SWA_res_53 954;
BA_ "GenSigTimeoutTime_Gateway_PQ46_A" SG_ 954 SWA_res_53 500;
BA_ "GenSigTimeoutMsg_Gateway_PQ46_A" SG_ 954 SWA_res_53 954;
BA_ "GenSigSendType" SG_ 954 SWA_res_53 0;
BA_ "GenSigTimeoutTime_Gateway_PQ35_A" SG_ 954 SWA_res_55 500;
BA_ "GenSigTimeoutMsg_Gateway_PQ35_A" SG_ 954 SWA_res_55 954;
BA_ "GenSigTimeoutTime_Gateway_PQ46_A" SG_ 954 SWA_res_55 500;
BA_ "GenSigTimeoutMsg_Gateway_PQ46_A" SG_ 954 SWA_res_55 954;
BA_ "GenSigSendType" SG_ 954 SWA_res_55 0;
BA_ "GenSigTimeoutTime_Gateway_PQ35_A" SG_ 954 SWA_res_57 500;
BA_ "GenSigTimeoutMsg_Gateway_PQ35_A" SG_ 954 SWA_res_57 954;
BA_ "GenSigTimeoutTime_Gateway_PQ46_A" SG_ 954 SWA_res_57 500;
BA_ "GenSigTimeoutMsg_Gateway_PQ46_A" SG_ 954 SWA_res_57 954;
BA_ "GenSigSendType" SG_ 954 SWA_res_57 0;
BA_ "GenSigTimeoutTime_Gateway_PQ35_A" SG_ 954 SWA_res_54 500;
BA_ "GenSigTimeoutMsg_Gateway_PQ35_A" SG_ 954 SWA_res_54 954;
BA_ "GenSigTimeoutTime_Gateway_PQ46_A" SG_ 954 SWA_res_54 500;
BA_ "GenSigTimeoutMsg_Gateway_PQ46_A" SG_ 954 SWA_res_54 954;
BA_ "GenSigSendType" SG_ 954 SWA_res_54 0;
BA_ "GenSigTimeoutTime_Gateway_PQ35_A" SG_ 954 SWA_res_60 500;
BA_ "GenSigTimeoutMsg_Gateway_PQ35_A" SG_ 954 SWA_res_60 954;
BA_ "GenSigTimeoutTime_Gateway_PQ46_A" SG_ 954 SWA_res_60 500;
BA_ "GenSigTimeoutMsg_Gateway_PQ46_A" SG_ 954 SWA_res_60 954;
BA_ "GenSigSendType" SG_ 954 SWA_res_60 0;
BA_ "GenSigTimeoutTime_Gateway_PQ35_A" SG_ 954 SWA_res_61 500;
BA_ "GenSigTimeoutMsg_Gateway_PQ35_A" SG_ 954 SWA_res_61 954;
BA_ "GenSigTimeoutTime_Gateway_PQ46_A" SG_ 954 SWA_res_61 500;
BA_ "GenSigTimeoutMsg_Gateway_PQ46_A" SG_ 954 SWA_res_61 954;
BA_ "GenSigSendType" SG_ 954 SWA_res_61 0;
BA_ "GenSigTimeoutTime_Gateway_PQ35_A" SG_ 954 SWA_res_56 500;
BA_ "GenSigTimeoutMsg_Gateway_PQ35_A" SG_ 954 SWA_res_56 954;
BA_ "GenSigTimeoutTime_Gateway_PQ46_A" SG_ 954 SWA_res_56 500;
BA_ "GenSigTimeoutMsg_Gateway_PQ46_A" SG_ 954 SWA_res_56 954;
BA_ "GenSigSendType" SG_ 954 SWA_res_56 0;
BA_ "GenSigTimeoutTime_Gateway_PQ35_A" SG_ 954 SWA_res_63 500;
BA_ "GenSigTimeoutMsg_Gateway_PQ35_A" SG_ 954 SWA_res_63 954;
BA_ "GenSigTimeoutTime_Gateway_PQ46_A" SG_ 954 SWA_res_63 500;
BA_ "GenSigTimeoutMsg_Gateway_PQ46_A" SG_ 954 SWA_res_63 954;
BA_ "GenSigSendType" SG_ 954 SWA_res_63 0;
BA_ "GenSigTimeoutTime_Gateway_PQ35_A" SG_ 954 SWA_res_58 500;
BA_ "GenSigTimeoutMsg_Gateway_PQ35_A" SG_ 954 SWA_res_58 954;
BA_ "GenSigTimeoutTime_Gateway_PQ46_A" SG_ 954 SWA_res_58 500;
BA_ "GenSigTimeoutMsg_Gateway_PQ46_A" SG_ 954 SWA_res_58 954;
BA_ "GenSigSendType" SG_ 954 SWA_res_58 0;
BA_ "GenSigTimeoutTime_Gateway_PQ35_A" SG_ 954 SWA_res_62 500;
BA_ "GenSigTimeoutMsg_Gateway_PQ35_A" SG_ 954 SWA_res_62 954;
BA_ "GenSigTimeoutTime_Gateway_PQ46_A" SG_ 954 SWA_res_62 500;
BA_ "GenSigTimeoutMsg_Gateway_PQ46_A" SG_ 954 SWA_res_62 954;
BA_ "GenSigSendType" SG_ 954 SWA_res_62 0;
BA_ "GenSigTimeoutMsg_Gateway_PQ46_A" SG_ 540 SWA_TP_Er 540;
BA_ "GenSigTimeoutMsg_Gateway_PQ35_A" SG_ 540 SWA_TP_Er 540;
BA_ "GenSigSendType" SG_ 540 SWA_TP_Er 5;
BA_ "GenSigTimeoutMsg_Gateway_PQ35_A" SG_ 1651 BAP_Data_LDW 1651;
BA_ "GenSigTimeoutMsg_Gateway_PQ46_A" SG_ 1651 BAP_Data_LDW 1651;
BA_ "GenSigTimeoutMsg_Gateway_PQ35_A" SG_ 1651 BAP_var_LDW 1651;
BA_ "GenSigTimeoutMsg_Gateway_PQ46_A" SG_ 1651 BAP_var_LDW 1651;
BA_ "GenSigTimeoutTime_Gateway_PQ35_A" SG_ 1470 LDW_Lampe_gelb 500;
BA_ "GenSigTimeoutMsg_Gateway_PQ35_A" SG_ 1470 LDW_Lampe_gelb 1470;
BA_ "GenSigTimeoutTime_Gateway_PQ46_A" SG_ 1470 LDW_Lampe_gelb 500;
BA_ "GenSigTimeoutMsg_Gateway_PQ46_A" SG_ 1470 LDW_Lampe_gelb 1470;
BA_ "GenSigSendType" SG_ 1470 LDW_Lampe_gelb 0;
BA_ "GenSigTimeoutTime_Gateway_PQ35_A" SG_ 1470 LDW_Gong 500;
BA_ "GenSigTimeoutMsg_Gateway_PQ35_A" SG_ 1470 LDW_Gong 1470;
BA_ "GenSigTimeoutTime_Gateway_PQ46_A" SG_ 1470 LDW_Gong 500;
BA_ "GenSigTimeoutMsg_Gateway_PQ46_A" SG_ 1470 LDW_Gong 1470;
BA_ "GenSigSendType" SG_ 1470 LDW_Gong 0;
BA_ "GenSigTimeoutTime_Gateway_PQ35_A" SG_ 1470 LDW_Lampe_gruen 500;
BA_ "GenSigTimeoutMsg_Gateway_PQ35_A" SG_ 1470 LDW_Lampe_gruen 1470;
BA_ "GenSigTimeoutTime_Gateway_PQ46_A" SG_ 1470 LDW_Lampe_gruen 500;
BA_ "GenSigTimeoutMsg_Gateway_PQ46_A" SG_ 1470 LDW_Lampe_gruen 1470;
BA_ "GenSigSendType" SG_ 1470 LDW_Lampe_gruen 0;
BA_ "GenSigTimeoutTime_Gateway_PQ35_A" SG_ 1470 LDW_KD_Fehler 500;
BA_ "GenSigTimeoutMsg_Gateway_PQ35_A" SG_ 1470 LDW_KD_Fehler 1470;
BA_ "GenSigTimeoutTime_Gateway_PQ46_A" SG_ 1470 LDW_KD_Fehler 500;
BA_ "GenSigTimeoutMsg_Gateway_PQ46_A" SG_ 1470 LDW_KD_Fehler 1470;
BA_ "GenSigSendType" SG_ 1470 LDW_KD_Fehler 0;
BA_ "GenSigTimeoutTime_Gateway_PQ35_A" SG_ 1470 LDW_res_00 500;
BA_ "GenSigTimeoutMsg_Gateway_PQ35_A" SG_ 1470 LDW_res_00 1470;
BA_ "GenSigTimeoutTime_Gateway_PQ46_A" SG_ 1470 LDW_res_00 500;
BA_ "GenSigTimeoutMsg_Gateway_PQ46_A" SG_ 1470 LDW_res_00 1470;
BA_ "GenSigSendType" SG_ 1470 LDW_res_00 0;
BA_ "GenSigTimeoutTime_Gateway_PQ35_A" SG_ 1470 LDW_Textbits 500;
BA_ "GenSigTimeoutMsg_Gateway_PQ35_A" SG_ 1470 LDW_Textbits 1470;
BA_ "GenSigTimeoutTime_Gateway_PQ46_A" SG_ 1470 LDW_Textbits 500;
BA_ "GenSigTimeoutMsg_Gateway_PQ46_A" SG_ 1470 LDW_Textbits 1470;
BA_ "GenSigSendType" SG_ 1470 LDW_Textbits 0;
BA_ "GenSigTimeoutTime_Gateway_PQ35_A" SG_ 1470 LDW_res_01 500;
BA_ "GenSigTimeoutMsg_Gateway_PQ35_A" SG_ 1470 LDW_res_01 1470;
BA_ "GenSigTimeoutTime_Gateway_PQ46_A" SG_ 1470 LDW_res_01 500;
BA_ "GenSigTimeoutMsg_Gateway_PQ46_A" SG_ 1470 LDW_res_01 1470;
BA_ "GenSigSendType" SG_ 1470 LDW_res_01 0;
BA_ "GenSigTimeoutTime_Gateway_PQ35_A" SG_ 1470 LDW_res_02 500;
BA_ "GenSigTimeoutMsg_Gateway_PQ35_A" SG_ 1470 LDW_res_02 1470;
BA_ "GenSigTimeoutTime_Gateway_PQ46_A" SG_ 1470 LDW_res_02 500;
BA_ "GenSigTimeoutMsg_Gateway_PQ46_A" SG_ 1470 LDW_res_02 1470;
BA_ "GenSigSendType" SG_ 1470 LDW_res_02 0;
BA_ "GenSigTimeoutTime_Gateway_PQ35_A" SG_ 1470 LDW_res_03 500;
BA_ "GenSigTimeoutMsg_Gateway_PQ35_A" SG_ 1470 LDW_res_03 1470;
BA_ "GenSigTimeoutTime_Gateway_PQ46_A" SG_ 1470 LDW_res_03 500;
BA_ "GenSigTimeoutMsg_Gateway_PQ46_A" SG_ 1470 LDW_res_03 1470;
BA_ "GenSigSendType" SG_ 1470 LDW_res_03 0;
BA_ "GenSigTimeoutTime_Gateway_PQ35_A" SG_ 1470 LDW_res_05 500;
BA_ "GenSigTimeoutMsg_Gateway_PQ35_A" SG_ 1470 LDW_res_05 1470;
BA_ "GenSigTimeoutTime_Gateway_PQ46_A" SG_ 1470 LDW_res_05 500;
BA_ "GenSigTimeoutMsg_Gateway_PQ46_A" SG_ 1470 LDW_res_05 1470;
BA_ "GenSigSendType" SG_ 1470 LDW_res_05 0;
BA_ "GenSigTimeoutTime_Gateway_PQ35_A" SG_ 1470 LDW_res_06 500;
BA_ "GenSigTimeoutMsg_Gateway_PQ35_A" SG_ 1470 LDW_res_06 1470;
BA_ "GenSigTimeoutTime_Gateway_PQ46_A" SG_ 1470 LDW_res_06 500;
BA_ "GenSigTimeoutMsg_Gateway_PQ46_A" SG_ 1470 LDW_res_06 1470;
BA_ "GenSigSendType" SG_ 1470 LDW_res_06 0;
BA_ "GenSigTimeoutTime_Gateway_PQ35_A" SG_ 1470 LDW_res_07 500;
BA_ "GenSigTimeoutMsg_Gateway_PQ35_A" SG_ 1470 LDW_res_07 1470;
BA_ "GenSigTimeoutTime_Gateway_PQ46_A" SG_ 1470 LDW_res_07 500;
BA_ "GenSigTimeoutMsg_Gateway_PQ46_A" SG_ 1470 LDW_res_07 1470;
BA_ "GenSigSendType" SG_ 1470 LDW_res_07 0;
BA_ "GenSigTimeoutTime_Gateway_PQ35_A" SG_ 1470 LDW_res_08 500;
BA_ "GenSigTimeoutMsg_Gateway_PQ35_A" SG_ 1470 LDW_res_08 1470;
BA_ "GenSigTimeoutTime_Gateway_PQ46_A" SG_ 1470 LDW_res_08 500;
BA_ "GenSigTimeoutMsg_Gateway_PQ46_A" SG_ 1470 LDW_res_08 1470;
BA_ "GenSigSendType" SG_ 1470 LDW_res_08 0;
BA_ "GenSigTimeoutTime_Gateway_PQ35_A" SG_ 1470 LDW_Lernmodus 500;
BA_ "GenSigTimeoutMsg_Gateway_PQ35_A" SG_ 1470 LDW_Lernmodus 1470;
BA_ "GenSigTimeoutTime_Gateway_PQ46_A" SG_ 1470 LDW_Lernmodus 500;
BA_ "GenSigTimeoutMsg_Gateway_PQ46_A" SG_ 1470 LDW_Lernmodus 1470;
BA_ "GenSigSendType" SG_ 1470 LDW_Lernmodus 0;
BA_ "GenSigTimeoutTime_Gateway_PQ35_A" SG_ 1470 LDW_res_04 500;
BA_ "GenSigTimeoutMsg_Gateway_PQ35_A" SG_ 1470 LDW_res_04 1470;
BA_ "GenSigTimeoutTime_Gateway_PQ46_A" SG_ 1470 LDW_res_04 500;
BA_ "GenSigTimeoutMsg_Gateway_PQ46_A" SG_ 1470 LDW_res_04 1470;
BA_ "GenSigSendType" SG_ 1470 LDW_res_04 0;
BA_ "GenSigTimeoutTime_Gateway_PQ35_A" SG_ 1470 LDW_res_18 500;
BA_ "GenSigTimeoutMsg_Gateway_PQ35_A" SG_ 1470 LDW_res_18 1470;
BA_ "GenSigTimeoutTime_Gateway_PQ46_A" SG_ 1470 LDW_res_18 500;
BA_ "GenSigTimeoutMsg_Gateway_PQ46_A" SG_ 1470 LDW_res_18 1470;
BA_ "GenSigSendType" SG_ 1470 LDW_res_18 0;
BA_ "GenSigTimeoutTime_Gateway_PQ35_A" SG_ 1470 LDW_res_21 500;
BA_ "GenSigTimeoutMsg_Gateway_PQ35_A" SG_ 1470 LDW_res_21 1470;
BA_ "GenSigTimeoutTime_Gateway_PQ46_A" SG_ 1470 LDW_res_21 500;
BA_ "GenSigTimeoutMsg_Gateway_PQ46_A" SG_ 1470 LDW_res_21 1470;
BA_ "GenSigSendType" SG_ 1470 LDW_res_21 0;
BA_ "GenSigTimeoutTime_Gateway_PQ35_A" SG_ 1470 LDW_res_22 500;
BA_ "GenSigTimeoutMsg_Gateway_PQ35_A" SG_ 1470 LDW_res_22 1470;
BA_ "GenSigTimeoutTime_Gateway_PQ46_A" SG_ 1470 LDW_res_22 500;
BA_ "GenSigTimeoutMsg_Gateway_PQ46_A" SG_ 1470 LDW_res_22 1470;
BA_ "GenSigSendType" SG_ 1470 LDW_res_22 0;
BA_ "GenSigTimeoutMsg_Gateway_PQ35_A" SG_ 538 LDW_TP_Er 538;
BA_ "GenSigTimeoutMsg_Gateway_PQ46_A" SG_ 538 LDW_TP_Er 538;
BA_ "GenSigSendType" SG_ 538 LDW_TP_Er 5;
BA_ "GenSigTimeoutTime_Lenkhilfe_ZF_3" SG_ 210 HC1_Checksumme 500;
BA_ "GenSigTimeoutMsg_Lenkhilfe_ZF_3" SG_ 210 HC1_Checksumme 210;
BA_ "GenSigTimeoutTime_Lenkhilfe_APA" SG_ 210 HC1_Checksumme 500;
BA_ "GenSigTimeoutMsg_Lenkhilfe_APA" SG_ 210 HC1_Checksumme 210;
BA_ "GenSigTimeoutTime_Lenkhilfe_ZF_2" SG_ 210 HC1_Checksumme 500;
BA_ "GenSigTimeoutMsg_Lenkhilfe_ZF_2" SG_ 210 HC1_Checksumme 210;
BA_ "GenSigSendType" SG_ 210 HC1_Checksumme 0;
BA_ "INIT" SG_ 210 HC1_Checksumme "CHK";
BA_ "GenSigTimeoutTime_Lenkhilfe_ZF_3" SG_ 210 HC1_Zaehler 500;
BA_ "GenSigTimeoutMsg_Lenkhilfe_ZF_3" SG_ 210 HC1_Zaehler 210;
BA_ "GenSigTimeoutTime_Lenkhilfe_ZF_2" SG_ 210 HC1_Zaehler 500;
BA_ "GenSigTimeoutMsg_Lenkhilfe_ZF_2" SG_ 210 HC1_Zaehler 210;
BA_ "GenSigTimeoutTime_Lenkhilfe_APA" SG_ 210 HC1_Zaehler 500;
BA_ "GenSigTimeoutMsg_Lenkhilfe_APA" SG_ 210 HC1_Zaehler 210;
BA_ "GenSigSendType" SG_ 210 HC1_Zaehler 0;
BA_ "GenSigTimeoutTime_Lenkhilfe_ZF_3" SG_ 210 HC1_Sta_HCA 500;
BA_ "GenSigTimeoutMsg_Lenkhilfe_ZF_3" SG_ 210 HC1_Sta_HCA 210;
BA_ "GenSigTimeoutTime_Lenkhilfe_ZF_2" SG_ 210 HC1_Sta_HCA 500;
BA_ "GenSigTimeoutMsg_Lenkhilfe_ZF_2" SG_ 210 HC1_Sta_HCA 210;
BA_ "GenSigTimeoutTime_Lenkhilfe_APA" SG_ 210 HC1_Sta_HCA 500;
BA_ "GenSigTimeoutMsg_Lenkhilfe_APA" SG_ 210 HC1_Sta_HCA 210;
BA_ "GenSigSendType" SG_ 210 HC1_Sta_HCA 0;
BA_ "GenSigTimeoutTime_Lenkhilfe_ZF_3" SG_ 210 HC1_LM_Offset 500;
BA_ "GenSigTimeoutMsg_Lenkhilfe_ZF_3" SG_ 210 HC1_LM_Offset 210;
BA_ "GenSigTimeoutTime_Lenkhilfe_ZF_2" SG_ 210 HC1_LM_Offset 500;
BA_ "GenSigTimeoutMsg_Lenkhilfe_ZF_2" SG_ 210 HC1_LM_Offset 210;
BA_ "GenSigTimeoutTime_Lenkhilfe_APA" SG_ 210 HC1_LM_Offset 500;
BA_ "GenSigTimeoutMsg_Lenkhilfe_APA" SG_ 210 HC1_LM_Offset 210;
BA_ "GenSigSendType" SG_ 210 HC1_LM_Offset 0;
BA_ "GenSigTimeoutTime_Lenkhilfe_ZF_3" SG_ 210 HC1_LM_Offset_Sign 500;
BA_ "GenSigTimeoutMsg_Lenkhilfe_ZF_3" SG_ 210 HC1_LM_Offset_Sign 210;
BA_ "GenSigTimeoutTime_Lenkhilfe_ZF_2" SG_ 210 HC1_LM_Offset_Sign 500;
BA_ "GenSigTimeoutMsg_Lenkhilfe_ZF_2" SG_ 210 HC1_LM_Offset_Sign 210;
BA_ "GenSigTimeoutTime_Lenkhilfe_APA" SG_ 210 HC1_LM_Offset_Sign 500;
BA_ "GenSigTimeoutMsg_Lenkhilfe_APA" SG_ 210 HC1_LM_Offset_Sign 210;
BA_ "GenSigSendType" SG_ 210 HC1_LM_Offset_Sign 0;
BA_ "GenSigTimeoutTime_Lenkhilfe_ZF_3" SG_ 210 HC1_Frequenz 500;
BA_ "GenSigTimeoutMsg_Lenkhilfe_ZF_3" SG_ 210 HC1_Frequenz 210;
BA_ "GenSigTimeoutTime_Lenkhilfe_ZF_2" SG_ 210 HC1_Frequenz 500;
BA_ "GenSigTimeoutMsg_Lenkhilfe_ZF_2" SG_ 210 HC1_Frequenz 210;
BA_ "GenSigTimeoutTime_Lenkhilfe_APA" SG_ 210 HC1_Frequenz 500;
BA_ "GenSigTimeoutMsg_Lenkhilfe_APA" SG_ 210 HC1_Frequenz 210;
BA_ "GenSigSendType" SG_ 210 HC1_Frequenz 0;
BA_ "GenSigTimeoutTime_Lenkhilfe_ZF_3" SG_ 210 HC1_Amplitude 500;
BA_ "GenSigTimeoutMsg_Lenkhilfe_ZF_3" SG_ 210 HC1_Amplitude 210;
BA_ "GenSigTimeoutTime_Lenkhilfe_ZF_2" SG_ 210 HC1_Amplitude 500;
BA_ "GenSigTimeoutMsg_Lenkhilfe_ZF_2" SG_ 210 HC1_Amplitude 210;
BA_ "GenSigTimeoutTime_Lenkhilfe_APA" SG_ 210 HC1_Amplitude 500;
BA_ "GenSigTimeoutMsg_Lenkhilfe_APA" SG_ 210 HC1_Amplitude 210;
BA_ "GenSigSendType" SG_ 210 HC1_Amplitude 0;
BA_ "GenSigTimeoutMsg_Gateway_PQ46_A" SG_ 1985 ISO_ACC_Resp_Data 1985;
BA_ "GenSigTimeoutMsg_Gateway_PQ35_A" SG_ 1985 ISO_ACC_Resp_Data 1985;
BA_ "GenSigTimeoutMsg_Gateway_PQ35_A" SG_ 1916 ISO_Lenkhilfe_Resp_Data 1916;
BA_ "GenSigTimeoutMsg_Gateway_PQ46_A" SG_ 1916 ISO_Lenkhilfe_Resp_Data 1916;
BA_ "GenSigTimeoutMsg_Gateway_PQ46_A" SG_ 534 FLA_TP_Er 534;
BA_ "GenSigSendType" SG_ 534 FLA_TP_Er 5;
BA_ "GenSigSendType" SG_ 1626 FL1_Reserve01 3;
BA_ "GenSigSendType" SG_ 1626 FL1_Reserve02 3;
BA_ "GenSigTimeoutTime_Gateway_PQ35_A" SG_ 1626 FL1_KD_Fehler 5000;
BA_ "GenSigTimeoutMsg_Gateway_PQ35_A" SG_ 1626 FL1_KD_Fehler 1626;
BA_ "GenSigTimeoutTime_Gateway_PQ46_A" SG_ 1626 FL1_KD_Fehler 5000;
BA_ "GenSigTimeoutMsg_Gateway_PQ46_A" SG_ 1626 FL1_KD_Fehler 1626;
BA_ "GenSigSendType" SG_ 1626 FL1_KD_Fehler 3;
BA_ "GenSigTimeoutTime_Gateway_PQ35_A" SG_ 1626 FL1_FLA_aktiv 5000;
BA_ "GenSigTimeoutMsg_Gateway_PQ35_A" SG_ 1626 FL1_FLA_aktiv 1626;
BA_ "GenSigTimeoutTime_Gateway_PQ46_A" SG_ 1626 FL1_FLA_aktiv 5000;
BA_ "GenSigTimeoutMsg_Gateway_PQ46_A" SG_ 1626 FL1_FLA_aktiv 1626;
BA_ "GenSigSendType" SG_ 1626 FL1_FLA_aktiv 3;
BA_ "GenSigSendType" SG_ 1626 FL1_ISP_defekt 3;
BA_ "GenSigSendType" SG_ 1626 FL1_Sensor_blockiert 3;
BA_ "GenSigSendType" SG_ 1626 FL1_Abblendursache 3;
BA_ "GenSigSendType" SG_ 1626 FL1_Fernlicht_PWM 3;
BA_ "GenSigStartValue" SG_ 1626 FL1_Fernlicht_PWM 100;
BA_ "GenSigSendType" SG_ 1626 FL1_ISP_Lichtwert_vo 3;
BA_ "GenSigStartValue" SG_ 1626 FL1_ISP_Lichtwert_vo 62;
BA_ "GenSigSendType" SG_ 1626 FL1_ISP_Lichtwert_hi 3;
BA_ "GenSigStartValue" SG_ 1626 FL1_ISP_Lichtwert_hi 62;
BA_ "GenSigSendType" SG_ 1626 FL1_ISP_Taste 3;
BA_ "GenSigSendType" SG_ 1626 FL1_ISP_EC_aktiv 3;
BA_ "GenSigStartValue" SG_ 1626 FL1_ISP_EC_aktiv 1;
BA_ "GenSigSendType" SG_ 1626 FL1_ISP_Kompass_aktiv 3;
BA_ "GenSigStartValue" SG_ 1626 FL1_ISP_Kompass_aktiv 1;
BA_ "GenSigSendType" SG_ 1626 FL1_Dimmwert_ASP 3;
BA_ "GenSigTimeoutTime_Gateway_PQ35_A" SG_ 1626 FL1_FLA_Aufblenden 5000;
BA_ "GenSigTimeoutMsg_Gateway_PQ35_A" SG_ 1626 FL1_FLA_Aufblenden 1626;
BA_ "GenSigTimeoutTime_Gateway_PQ46_A" SG_ 1626 FL1_FLA_Aufblenden 5000;
BA_ "GenSigTimeoutMsg_Gateway_PQ46_A" SG_ 1626 FL1_FLA_Aufblenden 1626;
BA_ "GenSigSendType" SG_ 1626 FL1_FLA_Aufblenden 3;
BA_ "GenSigSendType" SG_ 1626 FL1_ISP_Himmelsrichtung 3;
BA_ "GenSigStartValue" SG_ 1626 FL1_ISP_Himmelsrichtung 30;
BA_ "GenSigSendType" SG_ 1626 FL1_res_31 3;
BA_ "GenSigSendType" SG_ 1626 FL1_res_38 3;
BA_ "GenSigSendType" SG_ 1626 FL1_res_39 3;
BA_ "GenSigSendType" SG_ 1626 FL1_res_46 3;
BA_ "GenSigSendType" SG_ 1626 FL1_res_63 3;
BA_ "GenSigSendType" SG_ 1626 FL1_res_47 3;
BA_ "GenSigTimeoutTime_Otto" SG_ 1100 GE6_Checksum 500;
BA_ "GenSigTimeoutMsg_Otto" SG_ 1100 GE6_Checksum 1100;
BA_ "GenSigTimeoutTime_Diesel" SG_ 1100 GE6_Checksum 500;
BA_ "GenSigTimeoutMsg_Diesel" SG_ 1100 GE6_Checksum 1100;
BA_ "GenSigSendType" SG_ 1100 GE6_Checksum 0;
BA_ "INIT" SG_ 1100 GE6_Checksum "CHK";
BA_ "GenSigTimeoutTime_Otto" SG_ 1100 GE6_Zaehler 500;
BA_ "GenSigTimeoutMsg_Otto" SG_ 1100 GE6_Zaehler 1100;
BA_ "GenSigTimeoutTime_Diesel" SG_ 1100 GE6_Zaehler 500;
BA_ "GenSigTimeoutMsg_Diesel" SG_ 1100 GE6_Zaehler 1100;
BA_ "GenSigSendType" SG_ 1100 GE6_Zaehler 0;
BA_ "GenSigTimeoutTime_Diesel" SG_ 1100 GE6_res_48 500;
BA_ "GenSigTimeoutMsg_Diesel" SG_ 1100 GE6_res_48 1100;
BA_ "GenSigTimeoutTime_Otto" SG_ 1100 GE6_res_48 500;
BA_ "GenSigTimeoutMsg_Otto" SG_ 1100 GE6_res_48 1100;
BA_ "GenSigSendType" SG_ 1100 GE6_res_48 0;
BA_ "GenSigTimeoutTime_Otto" SG_ 1100 GE6_OelTemp 500;
BA_ "GenSigTimeoutMsg_Otto" SG_ 1100 GE6_OelTemp 1100;
BA_ "GenSigTimeoutTime_Diesel" SG_ 1100 GE6_OelTemp 500;
BA_ "GenSigTimeoutMsg_Diesel" SG_ 1100 GE6_OelTemp 1100;
BA_ "GenSigSendType" SG_ 1100 GE6_OelTemp 0;
BA_ "GenSigTimeoutTime_Diesel" SG_ 1100 GE6_res_42 500;
BA_ "GenSigTimeoutMsg_Diesel" SG_ 1100 GE6_res_42 1100;
BA_ "GenSigTimeoutTime_Otto" SG_ 1100 GE6_res_42 500;
BA_ "GenSigTimeoutMsg_Otto" SG_ 1100 GE6_res_42 1100;
BA_ "GenSigSendType" SG_ 1100 GE6_res_42 0;
BA_ "GenSigTimeoutTime_Diesel" SG_ 1100 GE6_maxBeschl 500;
BA_ "GenSigTimeoutMsg_Diesel" SG_ 1100 GE6_maxBeschl 1100;
BA_ "GenSigTimeoutTime_Otto" SG_ 1100 GE6_maxBeschl 500;
BA_ "GenSigTimeoutMsg_Otto" SG_ 1100 GE6_maxBeschl 1100;
BA_ "GenSigSendType" SG_ 1100 GE6_maxBeschl 0;
BA_ "GenSigStartValue" SG_ 1100 GE6_maxBeschl 88;
BA_ "GenSigTimeoutTime_Diesel" SG_ 1100 GE6_Verlustmom 500;
BA_ "GenSigTimeoutMsg_Diesel" SG_ 1100 GE6_Verlustmom 1100;
BA_ "GenSigTimeoutTime_Otto" SG_ 1100 GE6_Verlustmom 500;
BA_ "GenSigTimeoutMsg_Otto" SG_ 1100 GE6_Verlustmom 1100;
BA_ "GenSigSendType" SG_ 1100 GE6_Verlustmom 0;
BA_ "GenSigTimeoutTime_Diesel" SG_ 1100 GE6_QmaxBeschl 500;
BA_ "GenSigTimeoutMsg_Diesel" SG_ 1100 GE6_QmaxBeschl 1100;
BA_ "GenSigTimeoutTime_Otto" SG_ 1100 GE6_QmaxBeschl 500;
BA_ "GenSigTimeoutMsg_Otto" SG_ 1100 GE6_QmaxBeschl 1100;
BA_ "GenSigSendType" SG_ 1100 GE6_QmaxBeschl 0;
BA_ "GenSigStartValue" SG_ 1100 GE6_QmaxBeschl 1;
BA_ "GenSigTimeoutTime_Otto" SG_ 1100 GE6_QB_OelTemp 500;
BA_ "GenSigTimeoutMsg_Otto" SG_ 1100 GE6_QB_OelTemp 1100;
BA_ "GenSigTimeoutTime_Diesel" SG_ 1100 GE6_QB_OelTemp 500;
BA_ "GenSigTimeoutMsg_Diesel" SG_ 1100 GE6_QB_OelTemp 1100;
BA_ "GenSigSendType" SG_ 1100 GE6_QB_OelTemp 0;
BA_ "GenSigStartValue" SG_ 1100 GE6_QB_OelTemp 1;
BA_ "GenSigTimeoutTime_Diesel" SG_ 1100 GE6_Zielgang_err 500;
BA_ "GenSigTimeoutMsg_Diesel" SG_ 1100 GE6_Zielgang_err 1100;
BA_ "GenSigTimeoutTime_Otto" SG_ 1100 GE6_Zielgang_err 500;
BA_ "GenSigTimeoutMsg_Otto" SG_ 1100 GE6_Zielgang_err 1100;
BA_ "GenSigSendType" SG_ 1100 GE6_Zielgang_err 0;
BA_ "GenSigStartValue" SG_ 1100 GE6_Zielgang_err 1;
BA_ "GenSigTimeoutTime_Diesel" SG_ 1100 GE6_Gangwechsel 500;
BA_ "GenSigTimeoutMsg_Diesel" SG_ 1100 GE6_Gangwechsel 1100;
BA_ "GenSigTimeoutTime_Otto" SG_ 1100 GE6_Gangwechsel 500;
BA_ "GenSigTimeoutMsg_Otto" SG_ 1100 GE6_Gangwechsel 1100;
BA_ "GenSigSendType" SG_ 1100 GE6_Gangwechsel 0;
BA_ "GenSigTimeoutTime_Otto" SG_ 1100 GE6_TurbDZ 500;
BA_ "GenSigTimeoutMsg_Otto" SG_ 1100 GE6_TurbDZ 1100;
BA_ "GenSigTimeoutTime_Diesel" SG_ 1100 GE6_TurbDZ 500;
BA_ "GenSigTimeoutMsg_Diesel" SG_ 1100 GE6_TurbDZ 1100;
BA_ "GenSigSendType" SG_ 1100 GE6_TurbDZ 0;
BA_ "GenSigStartValue" SG_ 1100 GE6_TurbDZ 16382;
BA_ "GenSigTimeoutTime_TRW_ESP" SG_ 896 MO3_Prio_Dz 500;
BA_ "GenSigTimeoutMsg_TRW_ESP" SG_ 896 MO3_Prio_Dz 896;
BA_ "GenSigSendType" SG_ 896 MO3_Prio_Dz 0;
BA_ "GenSigTimeoutTime_TRW_ESP" SG_ 896 MO3_Sta_Pedal 500;
BA_ "GenSigTimeoutMsg_TRW_ESP" SG_ 896 MO3_Sta_Pedal 896;
BA_ "GenSigTimeoutTime_EPB" SG_ 896 MO3_Sta_Pedal 500;
BA_ "GenSigTimeoutMsg_EPB" SG_ 896 MO3_Sta_Pedal 896;
BA_ "GenSigSendType" SG_ 896 MO3_Sta_Pedal 0;
BA_ "GenSigTimeoutTime_TRW_ESP" SG_ 896 MO3_res_02 500;
BA_ "GenSigTimeoutMsg_TRW_ESP" SG_ 896 MO3_res_02 896;
BA_ "GenSigSendType" SG_ 896 MO3_res_02 0;
BA_ "GenSigTimeoutTime_Hybrid_DQ200" SG_ 896 MO3_Winterprg 500;
BA_ "GenSigTimeoutMsg_Hybrid_DQ200" SG_ 896 MO3_Winterprg 896;
BA_ "GenSigTimeoutTime_TRW_ESP" SG_ 896 MO3_Winterprg 500;
BA_ "GenSigTimeoutMsg_TRW_ESP" SG_ 896 MO3_Winterprg 896;
BA_ "GenSigTimeoutTime_DQ" SG_ 896 MO3_Winterprg 500;
BA_ "GenSigTimeoutMsg_DQ" SG_ 896 MO3_Winterprg 896;
BA_ "GenSigTimeoutTime_AG6" SG_ 896 MO3_Winterprg 500;
BA_ "GenSigTimeoutMsg_AG6" SG_ 896 MO3_Winterprg 896;
BA_ "GenSigSendType" SG_ 896 MO3_Winterprg 0;
BA_ "GenSigTimeoutTime_Teves_MK60_ESP" SG_ 896 MO3_Sign_FPG 500;
BA_ "GenSigTimeoutMsg_Teves_MK60_ESP" SG_ 896 MO3_Sign_FPG 896;
BA_ "GenSigTimeoutTime_TRW_ESP" SG_ 896 MO3_Sign_FPG 500;
BA_ "GenSigTimeoutMsg_TRW_ESP" SG_ 896 MO3_Sign_FPG 896;
BA_ "GenSigSendType" SG_ 896 MO3_Sign_FPG 0;
BA_ "GenSigTimeoutTime_Magne_Ride" SG_ 896 MO3_Aussentemp 500;
BA_ "GenSigTimeoutMsg_Magne_Ride" SG_ 896 MO3_Aussentemp 896;
BA_ "GenSigTimeoutTime_TRW_ESP" SG_ 896 MO3_Aussentemp 500;
BA_ "GenSigTimeoutMsg_TRW_ESP" SG_ 896 MO3_Aussentemp 896;
BA_ "GenSigSendType" SG_ 896 MO3_Aussentemp 0;
BA_ "GenSigTimeoutTime_Teves_MK60_ESP" SG_ 896 MO3_Sta_FPG 500;
BA_ "GenSigTimeoutMsg_Teves_MK60_ESP" SG_ 896 MO3_Sta_FPG 896;
BA_ "GenSigTimeoutTime_TRW_ESP" SG_ 896 MO3_Sta_FPG 500;
BA_ "GenSigTimeoutMsg_TRW_ESP" SG_ 896 MO3_Sta_FPG 896;
BA_ "GenSigSendType" SG_ 896 MO3_Sta_FPG 0;
BA_ "GenSigTimeoutTime_TRW_ESP" SG_ 896 MO3_Vorgluehen 500;
BA_ "GenSigTimeoutMsg_TRW_ESP" SG_ 896 MO3_Vorgluehen 896;
BA_ "GenSigSendType" SG_ 896 MO3_Vorgluehen 0;
BA_ "GenSigTimeoutTime_TRW_ESP" SG_ 896 MO3_Sta_Temp 500;
BA_ "GenSigTimeoutMsg_TRW_ESP" SG_ 896 MO3_Sta_Temp 896;
BA_ "GenSigSendType" SG_ 896 MO3_Sta_Temp 0;
BA_ "GenSigTimeoutTime_Teves_MK60_ESP" SG_ 896 MO3_Pedalwert 500;
BA_ "GenSigTimeoutMsg_Teves_MK60_ESP" SG_ 896 MO3_Pedalwert 896;
BA_ "GenSigTimeoutTime_HCA" SG_ 896 MO3_Pedalwert 500;
BA_ "GenSigTimeoutMsg_HCA" SG_ 896 MO3_Pedalwert 896;
BA_ "GenSigTimeoutTime_Magne_Ride" SG_ 896 MO3_Pedalwert 500;
BA_ "GenSigTimeoutMsg_Magne_Ride" SG_ 896 MO3_Pedalwert 896;
BA_ "GenSigTimeoutTime_TRW_ESP" SG_ 896 MO3_Pedalwert 500;
BA_ "GenSigTimeoutMsg_TRW_ESP" SG_ 896 MO3_Pedalwert 896;
BA_ "GenSigTimeoutTime_EPB" SG_ 896 MO3_Pedalwert 500;
BA_ "GenSigTimeoutMsg_EPB" SG_ 896 MO3_Pedalwert 896;
BA_ "GenSigTimeoutTime_AG6" SG_ 896 MO3_Pedalwert 500;
BA_ "GenSigTimeoutMsg_AG6" SG_ 896 MO3_Pedalwert 896;
BA_ "GenSigSendType" SG_ 896 MO3_Pedalwert 0;
BA_ "GenSigTimeoutTime_TRW_ESP" SG_ 896 MO3_res_37 500;
BA_ "GenSigTimeoutMsg_TRW_ESP" SG_ 896 MO3_res_37 896;
BA_ "GenSigSendType" SG_ 896 MO3_res_37 0;
BA_ "GenSigTimeoutTime_TRW_ESP" SG_ 896 MO3_res_38 500;
BA_ "GenSigTimeoutMsg_TRW_ESP" SG_ 896 MO3_res_38 896;
BA_ "GenSigSendType" SG_ 896 MO3_res_38 0;
BA_ "GenSigTimeoutTime_TRW_ESP" SG_ 896 MO3_res_39 500;
BA_ "GenSigTimeoutMsg_TRW_ESP" SG_ 896 MO3_res_39 896;
BA_ "GenSigSendType" SG_ 896 MO3_res_39 0;
BA_ "GenSigTimeoutTime_Teves_MK60_ESP" SG_ 896 MO3_FPGradient 500;
BA_ "GenSigTimeoutMsg_Teves_MK60_ESP" SG_ 896 MO3_FPGradient 896;
BA_ "GenSigTimeoutTime_TRW_ESP" SG_ 896 MO3_FPGradient 500;
BA_ "GenSigTimeoutMsg_TRW_ESP" SG_ 896 MO3_FPGradient 896;
BA_ "GenSigSendType" SG_ 896 MO3_FPGradient 0;
BA_ "GenSigTimeoutTime_DQ" SG_ 896 MO3_Vorz_RadWu 500;
BA_ "GenSigTimeoutMsg_DQ" SG_ 896 MO3_Vorz_RadWu 896;
BA_ "GenSigTimeoutTime_TRW_ESP" SG_ 896 MO3_Vorz_RadWu 500;
BA_ "GenSigTimeoutMsg_TRW_ESP" SG_ 896 MO3_Vorz_RadWu 896;
BA_ "GenSigSendType" SG_ 896 MO3_Vorz_RadWu 0;
BA_ "GenSigTimeoutTime_TRW_ESP" SG_ 896 MO3_WunschDz 500;
BA_ "GenSigTimeoutMsg_TRW_ESP" SG_ 896 MO3_WunschDz 896;
BA_ "GenSigSendType" SG_ 896 MO3_WunschDz 0;
BA_ "GenSigTimeoutTime_DQ" SG_ 896 MO3_Rad_Wu_Mo 500;
BA_ "GenSigTimeoutMsg_DQ" SG_ 896 MO3_Rad_Wu_Mo 896;
BA_ "GenSigTimeoutTime_TRW_ESP" SG_ 896 MO3_Rad_Wu_Mo 500;
BA_ "GenSigTimeoutMsg_TRW_ESP" SG_ 896 MO3_Rad_Wu_Mo 896;
BA_ "GenSigSendType" SG_ 896 MO3_Rad_Wu_Mo 0;
BA_ "GenSigTimeoutTime_TRW_ESP" SG_ 896 MO3_DKW 500;
BA_ "GenSigTimeoutMsg_TRW_ESP" SG_ 896 MO3_DKW 896;
BA_ "GenSigSendType" SG_ 896 MO3_DKW 0;
BA_ "GenSigTimeoutTime_Hybrid_DQ200" SG_ 896 MO3_Dz_Beeinfl 500;
BA_ "GenSigTimeoutMsg_Hybrid_DQ200" SG_ 896 MO3_Dz_Beeinfl 896;
BA_ "GenSigTimeoutTime_TRW_ESP" SG_ 896 MO3_Dz_Beeinfl 500;
BA_ "GenSigTimeoutMsg_TRW_ESP" SG_ 896 MO3_Dz_Beeinfl 896;
BA_ "GenSigTimeoutTime_DQ" SG_ 896 MO3_Dz_Beeinfl 500;
BA_ "GenSigTimeoutMsg_DQ" SG_ 896 MO3_Dz_Beeinfl 896;
BA_ "GenSigSendType" SG_ 896 MO3_Dz_Beeinfl 0;
BA_ "GenSigTimeoutTime_Teves_MK60_ESP" SG_ 1420 M10_Status_StSt 1000;
BA_ "GenSigTimeoutMsg_Teves_MK60_ESP" SG_ 1420 M10_Status_StSt 1420;
BA_ "GenSigTimeoutTime_TRW_ESP" SG_ 1420 M10_Status_StSt 1000;
BA_ "GenSigTimeoutMsg_TRW_ESP" SG_ 1420 M10_Status_StSt 1420;
BA_ "GenSigTimeoutTime_DQ" SG_ 1420 M10_Status_StSt 1000;
BA_ "GenSigTimeoutMsg_DQ" SG_ 1420 M10_Status_StSt 1420;
BA_ "GenSigTimeoutTime_ACC_Radar" SG_ 1420 M10_Status_StSt 1000;
BA_ "GenSigTimeoutMsg_ACC_Radar" SG_ 1420 M10_Status_StSt 1420;
BA_ "GenSigTimeoutTime_ACC_Lidar" SG_ 1420 M10_Status_StSt 1000;
BA_ "GenSigTimeoutMsg_ACC_Lidar" SG_ 1420 M10_Status_StSt 1420;
BA_ "GenSigTimeoutTime_Gateway_PQ46_A" SG_ 1420 M10_Status_StSt 1000;
BA_ "GenSigTimeoutMsg_Gateway_PQ46_A" SG_ 1420 M10_Status_StSt 1420;
BA_ "GenSigTimeoutTime_Gateway_PQ35_A" SG_ 1420 M10_Status_StSt 1000;
BA_ "GenSigTimeoutMsg_Gateway_PQ35_A" SG_ 1420 M10_Status_StSt 1420;
BA_ "GenSigSendType" SG_ 1420 M10_Status_StSt 0;
BA_ "GenSigTimeoutTime_Gateway_PQ46_A" SG_ 1420 M10_Druck_err_gem 1000;
BA_ "GenSigTimeoutMsg_Gateway_PQ46_A" SG_ 1420 M10_Druck_err_gem 1420;
BA_ "GenSigTimeoutTime_Gateway_PQ35_A" SG_ 1420 M10_Druck_err_gem 1000;
BA_ "GenSigTimeoutMsg_Gateway_PQ35_A" SG_ 1420 M10_Druck_err_gem 1420;
BA_ "GenSigSendType" SG_ 1420 M10_Druck_err_gem 0;
BA_ "GenSigTimeoutTime_Gateway_PQ46_A" SG_ 1420 M10_Anzeige 1000;
BA_ "GenSigTimeoutMsg_Gateway_PQ46_A" SG_ 1420 M10_Anzeige 1420;
BA_ "GenSigTimeoutTime_Gateway_PQ35_A" SG_ 1420 M10_Anzeige 1000;
BA_ "GenSigTimeoutMsg_Gateway_PQ35_A" SG_ 1420 M10_Anzeige 1420;
BA_ "GenSigSendType" SG_ 1420 M10_Anzeige 0;
BA_ "GenSigTimeoutTime_Gateway_PQ46_A" SG_ 1420 M10_Schubabschaltung 1000;
BA_ "GenSigTimeoutMsg_Gateway_PQ46_A" SG_ 1420 M10_Schubabschaltung 1420;
BA_ "GenSigTimeoutTime_Gateway_PQ35_A" SG_ 1420 M10_Schubabschaltung 1000;
BA_ "GenSigTimeoutMsg_Gateway_PQ35_A" SG_ 1420 M10_Schubabschaltung 1420;
BA_ "GenSigTimeoutTime_Teves_MK60_ESP" SG_ 1420 M10_Schubabschaltung 1000;
BA_ "GenSigTimeoutMsg_Teves_MK60_ESP" SG_ 1420 M10_Schubabschaltung 1420;
BA_ "GenSigSendType" SG_ 1420 M10_Schubabschaltung 0;
BA_ "GenSigTimeoutTime_Gateway_PQ46_A" SG_ 1420 M10_rel_Saugrohrdruck 1000;
BA_ "GenSigTimeoutMsg_Gateway_PQ46_A" SG_ 1420 M10_rel_Saugrohrdruck 1420;
BA_ "GenSigTimeoutTime_Gateway_PQ35_A" SG_ 1420 M10_rel_Saugrohrdruck 1000;
BA_ "GenSigTimeoutMsg_Gateway_PQ35_A" SG_ 1420 M10_rel_Saugrohrdruck 1420;
BA_ "GenSigTimeoutTime_Teves_MK60_ESP" SG_ 1420 M10_rel_Saugrohrdruck 1000;
BA_ "GenSigTimeoutMsg_Teves_MK60_ESP" SG_ 1420 M10_rel_Saugrohrdruck 1420;
BA_ "GenSigSendType" SG_ 1420 M10_rel_Saugrohrdruck 0;
BA_ "GenSigTimeoutTime_Gateway_PQ46_A" SG_ 1420 M10_Fahrbereitschaft 1000;
BA_ "GenSigTimeoutMsg_Gateway_PQ46_A" SG_ 1420 M10_Fahrbereitschaft 1420;
BA_ "GenSigTimeoutTime_Gateway_PQ35_A" SG_ 1420 M10_Fahrbereitschaft 1000;
BA_ "GenSigTimeoutMsg_Gateway_PQ35_A" SG_ 1420 M10_Fahrbereitschaft 1420;
BA_ "GenSigTimeoutTime_EKlimakomp" SG_ 1420 M10_Fahrbereitschaft 1000;
BA_ "GenSigTimeoutMsg_EKlimakomp" SG_ 1420 M10_Fahrbereitschaft 1420;
BA_ "GenSigTimeoutTime_Lenkhilfe_ZF_3" SG_ 1420 M10_Fahrbereitschaft 1000;
BA_ "GenSigTimeoutMsg_Lenkhilfe_ZF_3" SG_ 1420 M10_Fahrbereitschaft 1420;
BA_ "GenSigTimeoutTime_Lenkhilfe_ZF_2" SG_ 1420 M10_Fahrbereitschaft 1000;
BA_ "GenSigTimeoutMsg_Lenkhilfe_ZF_2" SG_ 1420 M10_Fahrbereitschaft 1420;
BA_ "GenSigSendType" SG_ 1420 M10_Fahrbereitschaft 0;
BA_ "GenSigTimeoutTime_Gateway_PQ46_A" SG_ 1420 M10_Hybrid 1000;
BA_ "GenSigTimeoutMsg_Gateway_PQ46_A" SG_ 1420 M10_Hybrid 1420;
BA_ "GenSigTimeoutTime_Gateway_PQ35_A" SG_ 1420 M10_Hybrid 1000;
BA_ "GenSigTimeoutMsg_Gateway_PQ35_A" SG_ 1420 M10_Hybrid 1420;
BA_ "GenSigTimeoutTime_Lenkhilfe_ZF_3" SG_ 1420 M10_Hybrid 1000;
BA_ "GenSigTimeoutMsg_Lenkhilfe_ZF_3" SG_ 1420 M10_Hybrid 1420;
BA_ "GenSigTimeoutTime_Lenkhilfe_ZF_2" SG_ 1420 M10_Hybrid 1000;
BA_ "GenSigTimeoutMsg_Lenkhilfe_ZF_2" SG_ 1420 M10_Hybrid 1420;
BA_ "GenSigSendType" SG_ 1420 M10_Hybrid 0;
BA_ "INIT" SG_ 1420 M10_Hybrid "const";
BA_ "GenSigTimeoutTime_Gateway_PQ46_A" SG_ 1420 M10_Freigabe_Reku 1000;
BA_ "GenSigTimeoutMsg_Gateway_PQ46_A" SG_ 1420 M10_Freigabe_Reku 1420;
BA_ "GenSigTimeoutTime_Gateway_PQ35_A" SG_ 1420 M10_Freigabe_Reku 1000;
BA_ "GenSigTimeoutMsg_Gateway_PQ35_A" SG_ 1420 M10_Freigabe_Reku 1420;
BA_ "GenSigSendType" SG_ 1420 M10_Freigabe_Reku 0;
BA_ "GenSigTimeoutTime_Gateway_PQ46_A" SG_ 1420 M10_VM_aktiv 1000;
BA_ "GenSigTimeoutMsg_Gateway_PQ46_A" SG_ 1420 M10_VM_aktiv 1420;
BA_ "GenSigTimeoutTime_Gateway_PQ35_A" SG_ 1420 M10_VM_aktiv 1000;
BA_ "GenSigTimeoutMsg_Gateway_PQ35_A" SG_ 1420 M10_VM_aktiv 1420;
BA_ "GenSigSendType" SG_ 1420 M10_VM_aktiv 0;
BA_ "GenSigTimeoutTime_Gateway_PQ46_A" SG_ 1420 M10_HYB_Bereitlampe 1000;
BA_ "GenSigTimeoutMsg_Gateway_PQ46_A" SG_ 1420 M10_HYB_Bereitlampe 1420;
BA_ "GenSigTimeoutTime_Gateway_PQ35_A" SG_ 1420 M10_HYB_Bereitlampe 1000;
BA_ "GenSigTimeoutMsg_Gateway_PQ35_A" SG_ 1420 M10_HYB_Bereitlampe 1420;
BA_ "GenSigSendType" SG_ 1420 M10_HYB_Bereitlampe 0;
BA_ "GenSigTimeoutTime_Gateway_PQ46_A" SG_ 1420 M10_HYB_Warnlampe 1000;
BA_ "GenSigTimeoutMsg_Gateway_PQ46_A" SG_ 1420 M10_HYB_Warnlampe 1420;
BA_ "GenSigTimeoutTime_Gateway_PQ35_A" SG_ 1420 M10_HYB_Warnlampe 1000;
BA_ "GenSigTimeoutMsg_Gateway_PQ35_A" SG_ 1420 M10_HYB_Warnlampe 1420;
BA_ "GenSigSendType" SG_ 1420 M10_HYB_Warnlampe 0;
BA_ "GenSigTimeoutTime_Gateway_PQ46_A" SG_ 1420 M10_HYB_Fehlerlampe 1000;
BA_ "GenSigTimeoutMsg_Gateway_PQ46_A" SG_ 1420 M10_HYB_Fehlerlampe 1420;
BA_ "GenSigTimeoutTime_Gateway_PQ35_A" SG_ 1420 M10_HYB_Fehlerlampe 1000;
BA_ "GenSigTimeoutMsg_Gateway_PQ35_A" SG_ 1420 M10_HYB_Fehlerlampe 1420;
BA_ "GenSigSendType" SG_ 1420 M10_HYB_Fehlerlampe 0;
BA_ "GenSigTimeoutTime_Gateway_PQ46_A" SG_ 1420 M10_Fehler_HV_Netz 1000;
BA_ "GenSigTimeoutMsg_Gateway_PQ46_A" SG_ 1420 M10_Fehler_HV_Netz 1420;
BA_ "GenSigTimeoutTime_Gateway_PQ35_A" SG_ 1420 M10_Fehler_HV_Netz 1000;
BA_ "GenSigTimeoutMsg_Gateway_PQ35_A" SG_ 1420 M10_Fehler_HV_Netz 1420;
BA_ "GenSigSendType" SG_ 1420 M10_Fehler_HV_Netz 0;
BA_ "GenSigTimeoutTime_Gateway_PQ46_A" SG_ 1420 M10_EKlKomLeiRed 1000;
BA_ "GenSigTimeoutMsg_Gateway_PQ46_A" SG_ 1420 M10_EKlKomLeiRed 1420;
BA_ "GenSigTimeoutTime_Gateway_PQ35_A" SG_ 1420 M10_EKlKomLeiRed 1000;
BA_ "GenSigTimeoutMsg_Gateway_PQ35_A" SG_ 1420 M10_EKlKomLeiRed 1420;
BA_ "GenSigSendType" SG_ 1420 M10_EKlKomLeiRed 0;
BA_ "GenSigTimeoutTime_Gateway_PQ46_A" SG_ 1420 M10_EM_aktiv 1000;
BA_ "GenSigTimeoutMsg_Gateway_PQ46_A" SG_ 1420 M10_EM_aktiv 1420;
BA_ "GenSigTimeoutTime_Gateway_PQ35_A" SG_ 1420 M10_EM_aktiv 1000;
BA_ "GenSigTimeoutMsg_Gateway_PQ35_A" SG_ 1420 M10_EM_aktiv 1420;
BA_ "GenSigSendType" SG_ 1420 M10_EM_aktiv 0;
BA_ "GenSigTimeoutTime_Gateway_PQ35_A" SG_ 1420 M10_Klimadruck 1000;
BA_ "GenSigTimeoutMsg_Gateway_PQ35_A" SG_ 1420 M10_Klimadruck 1420;
BA_ "GenSigTimeoutTime_Gateway_PQ46_A" SG_ 1420 M10_Klimadruck 1000;
BA_ "GenSigTimeoutMsg_Gateway_PQ46_A" SG_ 1420 M10_Klimadruck 1420;
BA_ "GenSigSendType" SG_ 1420 M10_Klimadruck 0;
BA_ "GenSigStartValue" SG_ 1420 M10_Klimadruck 254;
BA_ "GenSigTimeoutTime_Gateway_PQ35_A" SG_ 1420 M10_KompAusCode 1000;
BA_ "GenSigTimeoutMsg_Gateway_PQ35_A" SG_ 1420 M10_KompAusCode 1420;
BA_ "GenSigTimeoutTime_Gateway_PQ46_A" SG_ 1420 M10_KompAusCode 1000;
BA_ "GenSigTimeoutMsg_Gateway_PQ46_A" SG_ 1420 M10_KompAusCode 1420;
BA_ "GenSigSendType" SG_ 1420 M10_KompAusCode 0;
BA_ "GenSigTimeoutTime_Gateway_PQ46_A" SG_ 1420 M10_Akustik 1000;
BA_ "GenSigTimeoutMsg_Gateway_PQ46_A" SG_ 1420 M10_Akustik 1420;
BA_ "GenSigTimeoutTime_Gateway_PQ35_A" SG_ 1420 M10_Akustik 1000;
BA_ "GenSigTimeoutMsg_Gateway_PQ35_A" SG_ 1420 M10_Akustik 1420;
BA_ "GenSigSendType" SG_ 1420 M10_Akustik 0;
BA_ "GenSigTimeoutTime_Gateway_PQ46_A" SG_ 1420 M10_ShiftLockLampe 1000;
BA_ "GenSigTimeoutMsg_Gateway_PQ46_A" SG_ 1420 M10_ShiftLockLampe 1420;
BA_ "GenSigTimeoutTime_Gateway_PQ35_A" SG_ 1420 M10_ShiftLockLampe 1000;
BA_ "GenSigTimeoutMsg_Gateway_PQ35_A" SG_ 1420 M10_ShiftLockLampe 1420;
BA_ "GenSigSendType" SG_ 1420 M10_ShiftLockLampe 0;
BA_ "GenSigTimeoutTime_Gateway_PQ46_A" SG_ 1420 M10_Text_1_Hybrid 1000;
BA_ "GenSigTimeoutMsg_Gateway_PQ46_A" SG_ 1420 M10_Text_1_Hybrid 1420;
BA_ "GenSigTimeoutTime_Gateway_PQ35_A" SG_ 1420 M10_Text_1_Hybrid 1000;
BA_ "GenSigTimeoutMsg_Gateway_PQ35_A" SG_ 1420 M10_Text_1_Hybrid 1420;
BA_ "GenSigSendType" SG_ 1420 M10_Text_1_Hybrid 0;
BA_ "GenSigTimeoutTime_Gateway_PQ46_A" SG_ 1420 M10_Text_2_Hybrid 1000;
BA_ "GenSigTimeoutMsg_Gateway_PQ46_A" SG_ 1420 M10_Text_2_Hybrid 1420;
BA_ "GenSigTimeoutTime_Gateway_PQ35_A" SG_ 1420 M10_Text_2_Hybrid 1000;
BA_ "GenSigTimeoutMsg_Gateway_PQ35_A" SG_ 1420 M10_Text_2_Hybrid 1420;
BA_ "GenSigSendType" SG_ 1420 M10_Text_2_Hybrid 0;
BA_ "GenSigTimeoutTime_Gateway_PQ46_A" SG_ 1420 M10_Text_4_Hybrid 1000;
BA_ "GenSigTimeoutMsg_Gateway_PQ46_A" SG_ 1420 M10_Text_4_Hybrid 1420;
BA_ "GenSigTimeoutTime_Gateway_PQ35_A" SG_ 1420 M10_Text_4_Hybrid 1000;
BA_ "GenSigTimeoutMsg_Gateway_PQ35_A" SG_ 1420 M10_Text_4_Hybrid 1420;
BA_ "GenSigSendType" SG_ 1420 M10_Text_4_Hybrid 0;
BA_ "GenSigTimeoutTime_Gateway_PQ46_A" SG_ 1420 M10_Text_5_Hybrid 1000;
BA_ "GenSigTimeoutMsg_Gateway_PQ46_A" SG_ 1420 M10_Text_5_Hybrid 1420;
BA_ "GenSigTimeoutTime_Gateway_PQ35_A" SG_ 1420 M10_Text_5_Hybrid 1000;
BA_ "GenSigTimeoutMsg_Gateway_PQ35_A" SG_ 1420 M10_Text_5_Hybrid 1420;
BA_ "GenSigSendType" SG_ 1420 M10_Text_5_Hybrid 0;
BA_ "GenSigTimeoutTime_Gateway_PQ46_A" SG_ 1420 M10_Text_6_Hybrid 1000;
BA_ "GenSigTimeoutMsg_Gateway_PQ46_A" SG_ 1420 M10_Text_6_Hybrid 1420;
BA_ "GenSigTimeoutTime_Gateway_PQ35_A" SG_ 1420 M10_Text_6_Hybrid 1000;
BA_ "GenSigTimeoutMsg_Gateway_PQ35_A" SG_ 1420 M10_Text_6_Hybrid 1420;
BA_ "GenSigSendType" SG_ 1420 M10_Text_6_Hybrid 0;
BA_ "GenSigTimeoutTime_Gateway_PQ46_A" SG_ 1420 M10_Text_7_Hybrid 1000;
BA_ "GenSigTimeoutMsg_Gateway_PQ46_A" SG_ 1420 M10_Text_7_Hybrid 1420;
BA_ "GenSigTimeoutTime_Gateway_PQ35_A" SG_ 1420 M10_Text_7_Hybrid 1000;
BA_ "GenSigTimeoutMsg_Gateway_PQ35_A" SG_ 1420 M10_Text_7_Hybrid 1420;
BA_ "GenSigSendType" SG_ 1420 M10_Text_7_Hybrid 0;
BA_ "GenSigTimeoutTime_Gateway_PQ46_A" SG_ 1420 M10_Text_8_Hybrid 1000;
BA_ "GenSigTimeoutMsg_Gateway_PQ46_A" SG_ 1420 M10_Text_8_Hybrid 1420;
BA_ "GenSigTimeoutTime_Gateway_PQ35_A" SG_ 1420 M10_Text_8_Hybrid 1000;
BA_ "GenSigTimeoutMsg_Gateway_PQ35_A" SG_ 1420 M10_Text_8_Hybrid 1420;
BA_ "GenSigSendType" SG_ 1420 M10_Text_8_Hybrid 0;
BA_ "GenSigTimeoutTime_Gateway_PQ46_A" SG_ 1420 M10_Text_3_Hybrid 1000;
BA_ "GenSigTimeoutMsg_Gateway_PQ46_A" SG_ 1420 M10_Text_3_Hybrid 1420;
BA_ "GenSigTimeoutTime_Gateway_PQ35_A" SG_ 1420 M10_Text_3_Hybrid 1000;
BA_ "GenSigTimeoutMsg_Gateway_PQ35_A" SG_ 1420 M10_Text_3_Hybrid 1420;
BA_ "GenSigSendType" SG_ 1420 M10_Text_3_Hybrid 0;
BA_ "GenSigTimeoutTime_Gateway_PQ46_A" SG_ 1420 M10_StSt_Lampe 1000;
BA_ "GenSigTimeoutMsg_Gateway_PQ46_A" SG_ 1420 M10_StSt_Lampe 1420;
BA_ "GenSigTimeoutTime_Gateway_PQ35_A" SG_ 1420 M10_StSt_Lampe 1000;
BA_ "GenSigTimeoutMsg_Gateway_PQ35_A" SG_ 1420 M10_StSt_Lampe 1420;
BA_ "GenSigSendType" SG_ 1420 M10_StSt_Lampe 0;
BA_ "GenSigTimeoutTime_Gateway_PQ46_A" SG_ 1420 M10_BattFanSpd 1000;
BA_ "GenSigTimeoutMsg_Gateway_PQ46_A" SG_ 1420 M10_BattFanSpd 1420;
BA_ "GenSigTimeoutTime_Gateway_PQ35_A" SG_ 1420 M10_BattFanSpd 1000;
BA_ "GenSigTimeoutMsg_Gateway_PQ35_A" SG_ 1420 M10_BattFanSpd 1420;
BA_ "GenSigSendType" SG_ 1420 M10_BattFanSpd 0;
BA_ "GenSigStartValue" SG_ 1420 M10_BattFanSpd 14;
BA_ "GenSigTimeoutTime_Gateway_PQ46_A" SG_ 1420 M10_BMSInfo_gue 1000;
BA_ "GenSigTimeoutMsg_Gateway_PQ46_A" SG_ 1420 M10_BMSInfo_gue 1420;
BA_ "GenSigTimeoutTime_Gateway_PQ35_A" SG_ 1420 M10_BMSInfo_gue 1000;
BA_ "GenSigTimeoutMsg_Gateway_PQ35_A" SG_ 1420 M10_BMSInfo_gue 1420;
BA_ "GenSigSendType" SG_ 1420 M10_BMSInfo_gue 0;
BA_ "GenSigTimeoutTime_Gateway_PQ46_A" SG_ 1420 M10_VentilationReq 1000;
BA_ "GenSigTimeoutMsg_Gateway_PQ46_A" SG_ 1420 M10_VentilationReq 1420;
BA_ "GenSigTimeoutTime_Gateway_PQ35_A" SG_ 1420 M10_VentilationReq 1000;
BA_ "GenSigTimeoutMsg_Gateway_PQ35_A" SG_ 1420 M10_VentilationReq 1420;
BA_ "GenSigSendType" SG_ 1420 M10_VentilationReq 0;
BA_ "GenSigTimeoutTime_Gateway_PQ35_A" SG_ 1420 M10_res_06 1000;
BA_ "GenSigTimeoutMsg_Gateway_PQ35_A" SG_ 1420 M10_res_06 1420;
BA_ "GenSigTimeoutTime_Gateway_PQ46_A" SG_ 1420 M10_res_06 1000;
BA_ "GenSigTimeoutMsg_Gateway_PQ46_A" SG_ 1420 M10_res_06 1420;
BA_ "GenSigSendType" SG_ 1420 M10_res_06 0;
BA_ "GenSigTimeoutTime_Gateway_PQ46_A" SG_ 1420 M10_MotorStopp 1000;
BA_ "GenSigTimeoutMsg_Gateway_PQ46_A" SG_ 1420 M10_MotorStopp 1420;
BA_ "GenSigTimeoutTime_Gateway_PQ35_A" SG_ 1420 M10_MotorStopp 1000;
BA_ "GenSigTimeoutMsg_Gateway_PQ35_A" SG_ 1420 M10_MotorStopp 1420;
BA_ "GenSigSendType" SG_ 1420 M10_MotorStopp 3;
BA_ "GenSigTimeoutTime_TRW_ESP" SG_ 1420 M10_Wiederstart 1000;
BA_ "GenSigTimeoutMsg_TRW_ESP" SG_ 1420 M10_Wiederstart 1420;
BA_ "GenSigTimeoutTime_Teves_MK60_ESP" SG_ 1420 M10_Wiederstart 1000;
BA_ "GenSigTimeoutMsg_Teves_MK60_ESP" SG_ 1420 M10_Wiederstart 1420;
BA_ "GenSigTimeoutTime_DQ" SG_ 1420 M10_Wiederstart 1000;
BA_ "GenSigTimeoutMsg_DQ" SG_ 1420 M10_Wiederstart 1420;
BA_ "GenSigTimeoutTime_ACC_Lidar" SG_ 1420 M10_Wiederstart 1000;
BA_ "GenSigTimeoutMsg_ACC_Lidar" SG_ 1420 M10_Wiederstart 1420;
BA_ "GenSigTimeoutTime_ACC_Radar" SG_ 1420 M10_Wiederstart 1000;
BA_ "GenSigTimeoutMsg_ACC_Radar" SG_ 1420 M10_Wiederstart 1420;
BA_ "GenSigTimeoutTime_Gateway_PQ46_A" SG_ 1420 M10_Wiederstart 1000;
BA_ "GenSigTimeoutMsg_Gateway_PQ46_A" SG_ 1420 M10_Wiederstart 1420;
BA_ "GenSigTimeoutTime_Gateway_PQ35_A" SG_ 1420 M10_Wiederstart 1000;
BA_ "GenSigTimeoutMsg_Gateway_PQ35_A" SG_ 1420 M10_Wiederstart 1420;
BA_ "GenSigSendType" SG_ 1420 M10_Wiederstart 3;
BA_ "GenSigTimeoutTime_Gateway_PQ35_A" SG_ 1420 M10_Anf_Kl75 1000;
BA_ "GenSigTimeoutMsg_Gateway_PQ35_A" SG_ 1420 M10_Anf_Kl75 1420;
BA_ "GenSigTimeoutTime_Gateway_PQ46_A" SG_ 1420 M10_Anf_Kl75 1000;
BA_ "GenSigTimeoutMsg_Gateway_PQ46_A" SG_ 1420 M10_Anf_Kl75 1420;
BA_ "GenSigSendType" SG_ 1420 M10_Anf_Kl75 3;
BA_ "GenSigStartValue" SG_ 1420 M10_Anf_Kl75 1;
BA_ "GenSigTimeoutTime_DQ" SG_ 1420 M10_Start_D_erl 1000;
BA_ "GenSigTimeoutMsg_DQ" SG_ 1420 M10_Start_D_erl 1420;
BA_ "GenSigTimeoutTime_Gateway_PQ35_A" SG_ 1420 M10_Start_D_erl 1000;
BA_ "GenSigTimeoutMsg_Gateway_PQ35_A" SG_ 1420 M10_Start_D_erl 1420;
BA_ "GenSigTimeoutTime_Gateway_PQ46_A" SG_ 1420 M10_Start_D_erl 1000;
BA_ "GenSigTimeoutMsg_Gateway_PQ46_A" SG_ 1420 M10_Start_D_erl 1420;
BA_ "GenSigSendType" SG_ 1420 M10_Start_D_erl 0;
BA_ "GenSigTimeoutTime_Gateway_PQ46_A" SG_ 1420 M10_Blinken 1000;
BA_ "GenSigTimeoutMsg_Gateway_PQ46_A" SG_ 1420 M10_Blinken 1420;
BA_ "GenSigTimeoutTime_Gateway_PQ35_A" SG_ 1420 M10_Blinken 1000;
BA_ "GenSigTimeoutMsg_Gateway_PQ35_A" SG_ 1420 M10_Blinken 1420;
BA_ "GenSigSendType" SG_ 1420 M10_Blinken 0;
BA_ "GenSigTimeoutTime_DQ" SG_ 1420 M10_Start_D_gueltig 1000;
BA_ "GenSigTimeoutMsg_DQ" SG_ 1420 M10_Start_D_gueltig 1420;
BA_ "GenSigTimeoutTime_Gateway_PQ46_A" SG_ 1420 M10_Start_D_gueltig 1000;
BA_ "GenSigTimeoutMsg_Gateway_PQ46_A" SG_ 1420 M10_Start_D_gueltig 1420;
BA_ "GenSigTimeoutTime_Gateway_PQ35_A" SG_ 1420 M10_Start_D_gueltig 1000;
BA_ "GenSigTimeoutMsg_Gateway_PQ35_A" SG_ 1420 M10_Start_D_gueltig 1420;
BA_ "GenSigSendType" SG_ 1420 M10_Start_D_gueltig 0;
BA_ "GenSigTimeoutTime_Teves_MK60_ESP" SG_ 1420 M10_UDruckDyn 1000;
BA_ "GenSigTimeoutMsg_Teves_MK60_ESP" SG_ 1420 M10_UDruckDyn 1420;
BA_ "GenSigTimeoutTime_Gateway_PQ46_A" SG_ 1420 M10_UDruckDyn 1000;
BA_ "GenSigTimeoutMsg_Gateway_PQ46_A" SG_ 1420 M10_UDruckDyn 1420;
BA_ "GenSigTimeoutTime_Gateway_PQ35_A" SG_ 1420 M10_UDruckDyn 1000;
BA_ "GenSigTimeoutMsg_Gateway_PQ35_A" SG_ 1420 M10_UDruckDyn 1420;
BA_ "GenSigSendType" SG_ 1420 M10_UDruckDyn 0;
BA_ "GenSigTimeoutMsg_Gateway_PQ35_A" SG_ 513 Motor_TP_Er 513;
BA_ "GenSigTimeoutMsg_Gateway_PQ46_A" SG_ 513 Motor_TP_Er 513;
BA_ "GenSigSendType" SG_ 513 Motor_TP_Er 5;
VAL_ 1104 GE8_Hydr_Pumpe 1 "Hydraulikpumpe_angest" 0 "Hydraulikpumpe_aus" ;
VAL_ 1104 GE8_Motor_aus 1 "Motor_aus" 0 "Motor_startbereit" ;
VAL_ 1104 GE8_Anfahrfkt 1 "Anfahrfunktion_aktiv" 0 "Anfahrfunktion_nicht_aktiv" ;
VAL_ 1102 WH2_Fehler0 1 "Sensorik_Einzelfehler" 0 "kein_Sensorik_Einzelfehler" ;
VAL_ 1102 WH2_Init 1 "Initphase" 0 "keine_Initphase" ;
VAL_ 1102 WH2_Winter 1 "Wintertaster_betaetigt" 0 "nicht_betaetigt" ;
VAL_ 1102 WH2_Sport 1 "Sporttaster_betaetigt" 0 "nicht_betaetigt" ;
VAL_ 1102 WH2_Test_Flag 1 "Testergebnis_gueltig" 0 "Testergebnis_ungueltig" ;
VAL_ 1102 WH2_Position 7 "Tip_R" 6 "Ruhelage_X" 5 "Zwischenpos_V" 4 "Tip_D" 3 "Tip_minus" 2 "Tip_plus" 1 "Ruhelage_U" 0 "ungueltig" ;
VAL_ 1102 WH2_Ruhestromfehler 1 "Ruhestromfehler" 0 "kein_Ruhestromfehler" ;
VAL_ 1102 WH2_Fehler2 1 "Sporttaster_unterbr" 0 "Sporttaster_nicht_unterbr" ;
VAL_ 1102 WH2_Fehler1 1 "Sensorik_Mehrfachfehler" 0 "kein_Sensorik_Mehrfachfehler" ;
VAL_ 1102 WH2_Fehler4 1 "UnterUebersp_Fehler" 0 "kein_UnterUebersp_Fehler" ;
VAL_ 1102 WH2_Fehler5 1 "Timeout_Kombi2" 0 "kein_Timeout_Kombi2" ;
VAL_ 1102 WH2_Fehler3 1 "Anzeige_Waehlhebel_defekt" 0 "keine_defekte_Anzeige" ;
VAL_ 1102 WH2_Fehler7 1 "Timeout_GateKomf1" 0 "kein_Timeout_GateKomf1" ;
VAL_ 1102 WH2_Fehler6 1 "Timeout_Getriebe5" 0 "kein_Timeout_Getriebe5" ;
VAL_ 1494 PLS_PL_exist 1 "Parkluecke" 0 "keine_Parkluecke" ;
VAL_ 1494 PLS_mehrzg_aktiv 1 "aktiv" 0 "nicht_aktiv" ;
VAL_ 1494 PLS_Anf_Anz 1 "Anzeige_Anforderung" 0 "keine_Anforderung" ;
VAL_ 1494 PLS_Pos_OK 1 "Pos_OK" 0 "Pos_NOK" ;
VAL_ 1494 PLS_PL_Seite 1 "links" 0 "rechts" ;
VAL_ 1494 PLS_Meldungen 17 "ID_PLA_018" 16 "ID_PLA_017" 15 "ID_PLA_009" 14 "ID_PLA_008" 13 "ID_PLA_016" 12 "ID_PLA_015" 11 "ID_PLA_014" 10 "ID_PLA_013" 9 "ID_PLA_012" 8 "ID_PLA_011" 7 "ID_PLA_007" 6 "ID_PLA_006" 5 "ID_PLA_005" 4 "ID_PLA_004" 3 "ID_PLA_003" 2 "ID_PLA_002" 1 "ID_PLA_001" 0 "kein_Text" ;
VAL_ 1494 PLS_Lenk_Aktiv 1 "Lenkeingriff_aktiv" 0 "keine_Info" ;
VAL_ 1494 PLS_Akustik1 1 "Akustik" 0 "keine_Akustik" ;
VAL_ 1494 PLS_Akustik2 1 "Akustik" 0 "keine_Akustik" ;
VAL_ 1494 PLS_AnzeigePrio 3 "nicht_belegt" 2 "hohe_Prio" 1 "niedrige_Prio" 0 "Init_keine_Anzeige" ;
VAL_ 1494 PLS_Fahrtrichtg_mehrzg 1 "rueckwaerts" 0 "vorwaerts" ;
VAL_ 980 PL1_LW_Soll_Sign 1 "neg_Vorzeichen" 0 "pos_Vorzeichen" ;
VAL_ 1355 PA5_VMR_Abstand 255 "kein_Hindernis" ;
VAL_ 1355 PA5_VL_Abstand 255 "kein_Hindernis" ;
VAL_ 1355 PA5_HL_Abstand 255 "kein_Hindernis" ;
VAL_ 1355 PA5_HR_Abstand 255 "kein_Hindernis" ;
VAL_ 1355 PA5_HML_Abstand 255 "kein_Hindernis" ;
VAL_ 1355 PA5_HMR_Abstand 255 "kein_Hindernis" ;
VAL_ 1355 PA5_VML_Abstand 255 "kein_Hindernis" ;
VAL_ 1355 PA5_VR_Abstand 255 "kein_Hindernis" ;
VAL_ 1175 PH_Opt_Anzeige_V_ein 1 "opt_Anzeige_vorn_aktiv" ;
VAL_ 1175 PH_Opt_Anzeige_H_ein 1 "opt_Anzeige_hinten_aktiv" ;
VAL_ 1175 PH_Opt_Anz_V_Hindernis 1 "vorn_Hind_im_Warnbereich" ;
VAL_ 1175 PH_Abschaltursache 7 "Fehler" 5 "Kl_15_Bit_Null" 4 "PLA_Absch" 3 "PDC_Taster_Absch" 2 "v_Absch" 1 "Absch_Herausn_RGang" 0 "keine_Sys_aktiv" ;
VAL_ 1175 PH_Opt_Anz_H_Hindernis 1 "hinten_Hind_im_Warnbereich" ;
VAL_ 1175 PH_Tongeber_V_aktiv 1 "Tongeber_vorne_aktiv" ;
VAL_ 1175 PH_Tongeber_mute 1 "Tongeber_stumm" ;
VAL_ 1175 PH_Tongeber_H_aktiv 1 "Tongeber_hinten_aktiv" ;
VAL_ 1175 PH_defekt 1 "PH_wg_Defekt_deaktiv" ;
VAL_ 1175 PH_Anf_Audioabsenkung 1 "Anf_Audioabsenkung" ;
VAL_ 1175 PH_Systemzustand 7 "Fehler_gestoert" 3 "Anlage_auto_akt" 2 "Anlage_man_akt" 1 "Anlage_wg_RGang_akt" 0 "Anlage_aus" ;
VAL_ 1175 PH_Display_Kundenwunsch 3 "automatisch" 2 "Rear_View" 1 "Graphik" 0 "Anzeige_aus" ;
VAL_ 1175 PH_KD_Fehler 1 "Fehler" 0 "kein_Fehler" ;
VAL_ 1175 PH_gestoert 1 "PH_wg_Stoerung_temp_deaktiv" ;
VAL_ 1175 PH_BerErk_vorn 3 "Kollisionsbereich" 2 "Hauptwarnbereich" 1 "Vorwarnbereich_nur_NFZ" 0 "Init" ;
VAL_ 1175 PH_StartStopp_Info 3 "Systemfehler" 2 "Motoranlauf_notw" 1 "Stoppverbot_Motoranl_nn" 0 "Motorlauf_nn" ;
VAL_ 1175 PH_BerErk_hinten 3 "Kollisionsbereich" 2 "Hauptwarnbereich" 1 "Vorwarnbereich_nur_NFZ" 0 "Init" ;
VAL_ 714 QS2_Ist_Wert 255 "Fehler" ;
VAL_ 714 QS2_Gleichlauf 1 "Gleichlauf" 0 "Schlupf" ;
VAL_ 714 QS2_KD_Fehler 1 "Fehler" 0 "kein_Fehler" ;
VAL_ 714 QS2_Soll_Wert 255 "Fehler" ;
VAL_ 714 QS2_Status_VAQ 6 "Fehler_zu" 5 "norm_Abschaltung" 4 "norm_mit_ESP_Eing" 3 "norm_ohne_ESP_Eing" 2 "Kom_gestoert" 1 "Fehler_auf" 0 "Init" ;
VAL_ 1404 BY1_KD_Fehler 1 "Fehler" 0 "kein_Fehler" ;
VAL_ 1406 EY1_KD_Fehler 1 "Fehler" 0 "kein_Fehler" ;
VAL_ 1352 GE4_Shiftlock 1 "Waehlhebel_frei" 0 "Waehlhebel_verriegelt" ;
VAL_ 1352 GE4_Ausleuchtung 15 "Fehler" 14 "Tipp_Gasse" 13 "Position_L" 12 "Position_S_Sport" 11 "Position_Tipp_minus" 10 "Position_Tipp_plus" 8 "Position_P_Stop" 7 "Position_R" 6 "Position_N" 5 "Position_D" 4 "Position_4" 3 "Position_3" 2 "Position_2" 1 "Position_1" 0 "Keine_Lampe_angesteuert" ;
VAL_ 1352 GE4_AuslModus 1 "USA" 0 "RDW" ;
VAL_ 1352 GE4_Test 1 "Test_aktiv" 0 "kein_Test" ;
VAL_ 1106 GH1_FreigabeVMStop 1 "VM_Stopp_erlaubt" 0 "VM_Stopp_nicht_erlaubt" ;
VAL_ 1106 GH1_FreigabeK0 1 "K0_schliessen" 0 "K0_oeffnen" ;
VAL_ 1106 GH1_nK0 255 "Fehler" ;
VAL_ 1106 GH1_FehlerstatusGSG 3 "beide_Fehler" 2 "Anforderung_n_gleich_0" 1 "kein_Hydraulikdruck" 0 "kein_Fehler" ;
VAL_ 1106 GH1_Wiederstart 1 "Wiederstart_aktiv" 0 "kein_Wiederstart_aktiv" ;
VAL_ 1106 GH1_VZMomEingriff 1 "neg" 0 "pos" ;
VAL_ 1106 GH1_Sportfaktor 0 "nicht_sportlich" ;
VAL_ 1106 GH1_Freig_LL_Reg 1 "LL_Reg_freigegeben" 0 "keine_DZ_Reg_erlaubt" ;
VAL_ 1106 GH1_VM_akt_halten 1 "VM_aktiv_halten_starten" 0 "keine_Empfehlung" ;
VAL_ 1106 GH1_VKM_StKontr 1 "aktiv" 0 "nicht_aktiv" ;
VAL_ 1106 GH1_VKM_StAnf 1 "Startanf" 0 "keine_Startanf" ;
VAL_ 1090 GM3_QB_LangEingr 1 "Init_Fehler" 0 "gueltig" ;
VAL_ 1090 GM3_Moment 1023 "Neutralwert" ;
VAL_ 1090 GM3_MoSoMom 1023 "Fehler" 1022 "kein_Eingriff" ;
VAL_ 1090 GM3_MomID 15 "Fehler" 0 "reserviert" ;
VAL_ 1090 GM3_MomEingr 1 "MomEingAnf_moeglich" 0 "keine_Freigabe" ;
VAL_ 1090 GM3_StaSoMom 3 "Fehler" 2 "erh_Getriebeeingriff" 1 "reduz_Getriebeeingriff" 0 "keine_anforderung" ;
VAL_ 1090 GM3_LangEingr 1023 "Fehler" 1022 "kein_Eingriff" ;
VAL_ 1526 EK1_Comp_main_stat 1 "Comp_enabled" 0 "Comp_not_enabled" ;
VAL_ 1526 EK1_Comp_ovld_stat 6 "over_input_current" 4 "over_load" 3 "sw_over_current" 2 "current_restriction" 0 "normal" ;
VAL_ 1526 EK1_Comp_output_stat 3 "abnorm_curr_detection" 2 "output_line_cut_out" 1 "output_line_short" 0 "normal" ;
VAL_ 1526 EK1_Comp_photo_temp_stat 3 "sermister_abnormal" 2 "over_heat_S" 1 "over_heat_L" 0 "normal" ;
VAL_ 1526 EK1_Comp_Inv_stat 3 "system_abnormal_stop" 2 "temp_protection" 1 "start_fail" 0 "normal" ;
VAL_ 1526 EK1_KD_Fehler 1 "Fehler" 0 "kein_Fehler" ;
VAL_ 1526 EK1_Comp_SCI_com_stat 2 "Inverter_error" 1 "CAN_error" 0 "normal" ;
VAL_ 1526 EK1_Comp_current 255 "Init_not_avail" ;
VAL_ 1526 EK1_Comp_photo_temp 255 "Init_not_avail" ;
VAL_ 954 SWA_Gong 2 "Gong2" 1 "Gong1" 0 "kein_akust_Signal" ;
VAL_ 954 SWA_Textbits 0 "kein_Text" ;
VAL_ 954 SWA_Sta_passiv 1 "ein" 0 "aus" ;
VAL_ 954 SWA_KD_Fehler 1 "Fehler" 0 "kein_Fehler" ;
VAL_ 954 SWA_Sta_aktiv 1 "ein" 0 "aus" ;
VAL_ 1470 LDW_Lampe_gelb 1 "ein" 0 "aus" ;
VAL_ 1470 LDW_Gong 2 "Gong2" 1 "Gong1" 0 "kein_akust_Signal" ;
VAL_ 1470 LDW_Lampe_gruen 1 "ein" 0 "aus" ;
VAL_ 1470 LDW_KD_Fehler 1 "Fehler" 0 "kein_Fehler" ;
VAL_ 1470 LDW_Textbits 0 "kein_Text" ;
VAL_ 1470 LDW_Lernmodus 4 "LDW_Warn_li" 3 "LDW_warn_re" 2 "LDW_an_aktiv" 1 "LDW_an_inakt" 0 "LDW_aus" ;
VAL_ 210 HC1_Sta_HCA 5 "ext_MomEingr_angef" 3 "bereit" 2 "Kom_gestoert" 1 "Anf_nicht_ausf" 0 "deaktiv" ;
VAL_ 210 HC1_LM_Offset_Sign 1 "neg_Vorz" 0 "pos_Vorz" ;
VAL_ 1626 FL1_KD_Fehler 1 "Fehler" 0 "kein_Fehler" ;
VAL_ 1626 FL1_FLA_aktiv 1 "aktiv" 0 "nicht_aktiv" ;
VAL_ 1626 FL1_ISP_defekt 1 "defekt" 0 "nicht_defekt" ;
VAL_ 1626 FL1_Sensor_blockiert 1 "Sensor_blockiert" 0 "Sensor_iO" ;
VAL_ 1626 FL1_Abblendursache 255 "Fehler" 128 "Verz_Bed" 64 "Uebertemp" 32 "Nebel" 16 "zu_hell" 8 "Ort_erkannt" 4 "v_unterschr" 2 "voraus_Fzg" 1 "entg_Fzg" 0 "keine" ;
VAL_ 1626 FL1_Fernlicht_PWM 127 "Fehler" ;
VAL_ 1626 FL1_ISP_Lichtwert_vo 63 "Fehler" 62 "Init" ;
VAL_ 1626 FL1_ISP_Lichtwert_hi 63 "Fehler" 62 "Init" ;
VAL_ 1626 FL1_ISP_Taste 1 "betaetigt" 0 "nicht_betaetigt" ;
VAL_ 1626 FL1_ISP_EC_aktiv 1 "aktiv" 0 "nicht_aktiv" ;
VAL_ 1626 FL1_ISP_Kompass_aktiv 1 "aktiv" 0 "nicht_aktiv" ;
VAL_ 1626 FL1_Dimmwert_ASP 63 "Fehler" ;
VAL_ 1626 FL1_FLA_Aufblenden 1 "aufblenden" 0 "nicht_aufblenden" ;
VAL_ 1626 FL1_ISP_Himmelsrichtung 31 "Fehler" 30 "Init" ;
VAL_ 1100 GE6_OelTemp 255 "Fehler" ;
VAL_ 1100 GE6_maxBeschl 255 "Fehler" ;
VAL_ 1100 GE6_QmaxBeschl 1 "Ersatz_Init_Fehler" 0 "gueltig" ;
VAL_ 1100 GE6_QB_OelTemp 1 "Ersatz_Init_Fehler" 0 "gueltig" ;
VAL_ 1100 GE6_Zielgang_err 1 "Zielgang_erreicht" 0 "Zielgang_nicht_erreicht" ;
VAL_ 1100 GE6_Gangwechsel 1 "Gangwechsel" 0 "kein_Gangwechsel" ;
VAL_ 1100 GE6_TurbDZ 16383 "Fehler" 16382 "Init" ;
VAL_ 896 MO3_Prio_Dz 1 "Zwang" 0 "Wunsch" ;
VAL_ 896 MO3_Sta_Pedal 1 "Ersatzwert" 0 "Fahrpedal_iO" ;
VAL_ 896 MO3_Winterprg 1 "aktiv" 0 "nicht_aktiv" ;
VAL_ 896 MO3_Sign_FPG 1 "negativ" 0 "positiv" ;
VAL_ 896 MO3_Aussentemp 255 "Fehler" ;
VAL_ 896 MO3_Sta_FPG 1 "Gradient_bed" 0 "Gradient_nicht_bed" ;
VAL_ 896 MO3_Vorgluehen 1 "Motor_muss_gestartet_werden" 0 "keine_Anforderung" ;
VAL_ 896 MO3_Sta_Temp 1 "Ersatzwert" 0 "Geber_iO" ;
VAL_ 896 MO3_Pedalwert 255 "Fehler" ;
VAL_ 896 MO3_FPGradient 255 "Fehler" ;
VAL_ 896 MO3_Vorz_RadWu 1 "Negativ" 0 "Positiv" ;
VAL_ 896 MO3_WunschDz 255 "Fehler" ;
VAL_ 896 MO3_Rad_Wu_Mo 4095 "Fehler" ;
VAL_ 896 MO3_DKW 255 "Fehler" ;
VAL_ 1420 M10_Status_StSt 3 "Syst_akt_MoLauf_notw" 2 "Syst_akt_kein_MoLauf_notw" 1 "Abschaltung" 0 "StSt_nicht_verf" ;
VAL_ 1420 M10_Druck_err_gem 1 "gemessen" 0 "errechnet" ;
VAL_ 1420 M10_Anzeige 15 "Bremse_treten" 14 "WH_in_P_N" 13 "Kuppl_bet" 12 "Mot_startet" 3 "Wiederstart" 2 "StSt_deaktiv" 1 "Mot_Stopp" 0 "keine_Anzeige" ;
VAL_ 1420 M10_Schubabschaltung 1 "Schubabschaltung" 0 "keine_Schubabsch" ;
VAL_ 1420 M10_rel_Saugrohrdruck 63 "Fehler_nicht_verf" 0 "Init_Ueberdruck" ;
VAL_ 1420 M10_Fahrbereitschaft 1 "fahrbereit" 0 "nicht_fahrbereit" ;
VAL_ 1420 M10_Hybrid 1 "Hybrid" 0 "kein_Hybrid" ;
VAL_ 1420 M10_Freigabe_Reku 3 "RekuModus_aktiv" 2 "Empf_U_Absenkung" 1 "Empf_U_Anhebung" 0 "RekuModus_aus" ;
VAL_ 1420 M10_VM_aktiv 1 "VM_aktiv" 0 "VM_inaktiv" ;
VAL_ 1420 M10_HYB_Bereitlampe 1 "Lampe_ein" 0 "Lampe_aus" ;
VAL_ 1420 M10_HYB_Warnlampe 1 "Lampe_ein" 0 "Lampe_aus" ;
VAL_ 1420 M10_HYB_Fehlerlampe 1 "Lampe_ein" 0 "Lampe_aus" ;
VAL_ 1420 M10_Fehler_HV_Netz 1 "kein_gen_Betrieb_moegl" 0 "iO" ;
VAL_ 1420 M10_EKlKomLeiRed 3 "LeistBegr_25" 2 "LeistBegr_50" 1 "LeistBegr_75" 0 "keine_LeistBegr" ;
VAL_ 1420 M10_EM_aktiv 1 "EM_aktiv" 0 "EM_inaktiv" ;
VAL_ 1420 M10_Klimadruck 255 "Fehler" 254 "Init" ;
VAL_ 1420 M10_KompAusCode 7 "Unterspg_10" 6 "Ueberspg_13" 5 "HD_Sensor_def_17" 4 "MotManagem_12" 3 "Aussentemp_8" 2 "Niederdruck_3" 1 "Hochdruck_1" 0 "keine" ;
VAL_ 1420 M10_Akustik 3 "frei" 2 "Akustik_2" 1 "Akustik_1" 0 "keine_Akustik" ;
VAL_ 1420 M10_ShiftLockLampe 1 "Lampe_ein" 0 "Lampe_aus" ;
VAL_ 1420 M10_Text_1_Hybrid 1 "Text_1" 0 "kein_Text" ;
VAL_ 1420 M10_Text_2_Hybrid 1 "Text_2" 0 "kein_Text" ;
VAL_ 1420 M10_Text_4_Hybrid 1 "Text_4" 0 "kein_Text" ;
VAL_ 1420 M10_Text_5_Hybrid 1 "Text_5" 0 "kein_Text" ;
VAL_ 1420 M10_Text_6_Hybrid 0 "kein_Text" ;
VAL_ 1420 M10_Text_7_Hybrid 0 "kein_Text" ;
VAL_ 1420 M10_Text_8_Hybrid 0 "kein_Text" ;
VAL_ 1420 M10_Text_3_Hybrid 1 "Text_3" 0 "kein_Text" ;
VAL_ 1420 M10_StSt_Lampe 1 "Lampe_ein" 0 "Lampe_aus" ;
VAL_ 1420 M10_BattFanSpd 15 "Fehler" 14 "Init" ;
VAL_ 1420 M10_BMSInfo_gue 1 "gueltig" 0 "nicht_gueltig_od_alt" ;
VAL_ 1420 M10_VentilationReq 1 "Umluftklappe_oeffnen" 0 "Umluftklappe_nicht_oeffnen" ;
VAL_ 1420 M10_MotorStopp 1 "Motor_Stopp_aktiv" 0 "Motor_Stopp_inaktiv" ;
VAL_ 1420 M10_Wiederstart 1 "Wiederstart_aktiv" 0 "Wiederstart_inaktiv" ;
VAL_ 1420 M10_Anf_Kl75 1 "Anf_Kl75_einschalten" 0 "Anf_Kl75_ausschalten" ;
VAL_ 1420 M10_Start_D_erl 1 "Startfreigabe_in_Fahrstufe" 0 "Startfreigabe_nur_PN" ;
VAL_ 1420 M10_Blinken 1 "Blinken" 0 "kein_Blinken" ;
VAL_ 1420 M10_Start_D_gueltig 1 "gueltig" 0 "nicht_gueltig" ;
VAL_ 1420 M10_UDruckDyn 1 "Dyn_immer_kleiner_50mbar" 0 "Dyn_1mal_groesser_50mbar" ;
